VERSION "HNNBNNNYNNNNNNNNNNNNNNNNNNNNNNNNNNNNNNNNNN/4/%%%/4/'%**4NNN///"

NS_ :

BS_:

BU_: AAG BCM1 BCM2 ELV Gateway HDSG IEZS MFG MSBBR SAD SAD2 Schwerpanzer_Zusatz SitzMem_BFS SitzMem_FS SitzMem_HBFS SitzMem_HFS SitzMem_SR3 SpoilerSG TSG_BFS TSG_FS VSG VTS DK_Dummy

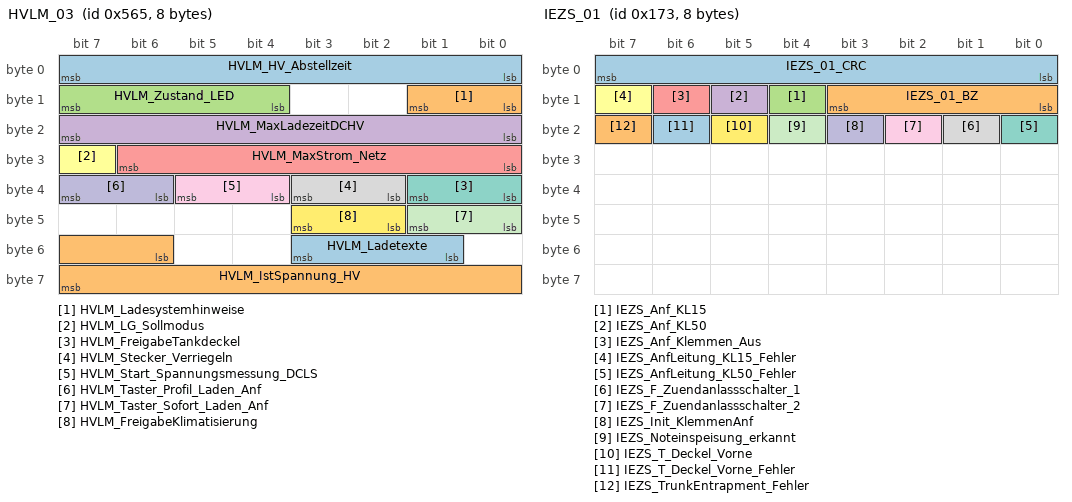
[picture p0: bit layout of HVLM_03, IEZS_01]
BO_ 1381 HVLM_03: 8 Gateway
 SG_ HVLM_HV_Abstellzeit : 0|8@1+ (4,0) [0|1012] "Unit_Minut" Vector__XXX
 SG_ HVLM_Ladesystemhinweise : 8|2@1+ (1,0) [0|3] "" Vector__XXX
 SG_ HVLM_Zustand_LED : 12|4@1+ (1,0) [0|15] "" Vector__XXX
 SG_ HVLM_MaxLadezeitDCHV : 16|8@1+ (10,0) [0|2530] "Unit_Minut" Vector__XXX
 SG_ HVLM_MaxStrom_Netz : 24|7@1+ (0.5,0) [0|62.5] "Unit_Amper" Vector__XXX
 SG_ HVLM_LG_Sollmodus : 31|1@1+ (1,0) [0|1] "" Vector__XXX
 SG_ HVLM_FreigabeTankdeckel : 32|2@1+ (1,0) [0|3] "" Vector__XXX
 SG_ HVLM_Stecker_Verriegeln : 34|2@1+ (1,0) [0|3] "" Vector__XXX
 SG_ HVLM_Start_Spannungsmessung_DCLS : 36|2@1+ (1,0) [0|3] "" Vector__XXX
 SG_ HVLM_Taster_Profil_Laden_Anf : 38|2@1+ (1,0) [0|3] "" Vector__XXX
 SG_ HVLM_Taster_Sofort_Laden_Anf : 40|2@1+ (1,0) [0|3] "" Vector__XXX
 SG_ HVLM_FreigabeKlimatisierung : 42|2@1+ (1,0) [0|3] "" Vector__XXX
 SG_ HVLM_Ladetexte : 49|3@1+ (1,0) [0|7] ""  VTS
 SG_ HVLM_IstSpannung_HV : 54|10@1+ (1,0) [0|1021] "Unit_Volt" Vector__XXX

BO_ 1340 HVLM_04: 8 Gateway
 SG_ HVLM_04_CRC : 0|8@1+ (1,0) [0|255] "" Vector__XXX
 SG_ HVLM_04_BZ : 8|4@1+ (1,0) [0|15] "" Vector__XXX
 SG_ HVLM_STH_Betriebsmodus : 12|3@1+ (1,0) [0|7] "" Vector__XXX
 SG_ HVLM_Standklima_Timer_Status : 15|1@1+ (1,0) [0|1] "" Vector__XXX
 SG_ HVLM_HVEM_MaxLeistung : 16|9@1+ (50,0) [0|25450] "Unit_Watt" Vector__XXX
 SG_ HVLM_Status_Netz : 25|1@1+ (1,0) [0|1] "" Vector__XXX
 SG_ HVLM_Ladeart : 27|2@1+ (1,0) [0|3] "" Vector__XXX
 SG_ HVLM_VK_STH_Einsatz : 29|3@1+ (1,0) [0|7] "" Vector__XXX
 SG_ HVLM_VK_Modus : 32|2@1+ (1,0) [0|3] "" Vector__XXX
 SG_ HVLM_IstModus_02 : 34|2@1+ (1,0) [0|3] "" Vector__XXX
 SG_ HVLM_HV_Anf : 36|2@1+ (1,0) [0|3] "" Vector__XXX
 SG_ HVLM_Fehlerstatus : 38|3@1+ (1,0) [0|7] "" Vector__XXX
 SG_ HVLM_Anforderung_HMS : 41|3@1+ (1,0) [0|7] "" Vector__XXX
 SG_ HVLM_Parken_beibehalten_HMS : 44|2@1+ (1,0) [0|3] "" Vector__XXX
 SG_ HVLM_Dauer_Klima : 46|5@1+ (1,0) [0|30] "Unit_Minut" Vector__XXX
 SG_ HVLM_Stecker_Status : 51|2@1+ (1,0) [0|3] ""  VTS
 SG_ HVLM_LadeAnforderung : 53|3@1+ (1,0) [0|7] "" Vector__XXX
 SG_ HVLM_MaxBatLadestromHV : 56|8@1+ (1,0) [0|253] "Unit_Amper" Vector__XXX

BO_ 371 IEZS_01: 8 IEZS
 SG_ IEZS_01_CRC : 0|8@1+ (1,0) [0|255] ""  BCM2
 SG_ IEZS_01_BZ : 8|4@1+ (1,0) [0|15] ""  BCM2
 SG_ IEZS_Anf_KL15 : 12|1@1+ (1,0) [0|1] ""  BCM2
 SG_ IEZS_Anf_KL50 : 13|1@1+ (1,0) [0|1] ""  BCM2
 SG_ IEZS_Anf_Klemmen_Aus : 14|1@1+ (1,0) [0|1] "Unit_Bit"  BCM2
 SG_ IEZS_AnfLeitung_KL15_Fehler : 15|1@1+ (1,0) [0|1] ""  BCM2
 SG_ IEZS_AnfLeitung_KL50_Fehler : 16|1@1+ (1,0) [0|1] ""  BCM2
 SG_ IEZS_F_Zuendanlassschalter_1 : 17|1@1+ (1,0) [0|1] ""  BCM2
 SG_ IEZS_F_Zuendanlassschalter_2 : 18|1@1+ (1,0) [0|1] ""  BCM2
 SG_ IEZS_Init_KlemmenAnf : 19|1@1+ (1,0) [0|1] ""  BCM2
 SG_ IEZS_Noteinspeisung_erkannt : 20|1@1+ (1,0) [0|1] ""  BCM2
 SG_ IEZS_T_Deckel_Vorne : 21|1@1+ (1,0) [0|1] ""  BCM2
 SG_ IEZS_T_Deckel_Vorne_Fehler : 22|1@1+ (1,0) [0|1] ""  BCM2
 SG_ IEZS_TrunkEntrapment_Fehler : 23|1@1+ (1,0) [0|1] ""  BCM2

BO_ 17 IMMO_Auth_Master_Slave01: 8 BCM2
 SG_ IMMO_Auth_Master_Slave01_Sig : 0|64@1+ (1,0) [0|1.84467440737096E+019] ""  Gateway

BO_ 19 IMMO_Auth_Master_Slave02: 8 BCM2
 SG_ IMMO_Auth_Master_Slave02_Sig : 0|64@1+ (1,0) [0|1.84467440737096E+019] ""  Gateway

BO_ 21 IMMO_Auth_Master_Slave03: 8 BCM2
 SG_ IMMO_Auth_Master_Slave03_Sig : 0|64@1+ (1,0) [0|1.84467440737096E+019] ""  Gateway

BO_ 23 IMMO_Auth_Master_Slave04: 8 BCM2
 SG_ IMMO_Auth_Master_Slave04_Sig : 0|64@1+ (1,0) [0|1.84467440737096E+019] ""  Gateway

BO_ 25 IMMO_Auth_Master_Slave05: 8 BCM2
 SG_ IMMO_Auth_Master_Slave05_Sig : 0|64@1+ (1,0) [0|1.84467440737096E+019] ""  Gateway

BO_ 27 IMMO_Auth_Master_Slave06: 8 BCM2
 SG_ IMMO_Auth_Master_Slave06_Sig : 0|64@1+ (1,0) [0|1.84467440737096E+019] ""  ELV

BO_ 29 IMMO_Auth_Master_Slave07: 8 BCM2
 SG_ IMMO_Auth_Master_Slave07_Sig1 : 0|64@1+ (1,0) [0|1.84467440737096E+019] ""  Gateway

BO_ 31 IMMO_Auth_Master_Slave08: 8 BCM2
 SG_ IMMO_Auth_Master_Slave08_Sig : 0|64@1+ (1,0) [0|1.84467440737096E+019] ""  VTS

BO_ 16 IMMO_Auth_Slave01_Master: 8 Gateway
 SG_ IMMO_Auth_Slave01_Master_Sig : 0|64@1+ (1,0) [0|1.84467440737096E+019] ""  BCM2

BO_ 18 IMMO_Auth_Slave02_Master: 8 Gateway
 SG_ IMMO_Auth_Slave02_Master_Sig : 0|64@1+ (1,0) [0|1.84467440737096E+019] ""  BCM2

BO_ 20 IMMO_Auth_Slave03_Master: 8 Gateway
 SG_ IMMO_Auth_Slave03_Master_Sig : 0|64@1+ (1,0) [0|1.84467440737096E+019] ""  BCM2

BO_ 22 IMMO_Auth_Slave04_Master: 8 Gateway
 SG_ IMMO_Auth_Slave04_Master_Sig : 0|64@1+ (1,0) [0|1.84467440737096E+019] ""  BCM2

BO_ 24 IMMO_Auth_Slave05_Master: 8 Gateway
 SG_ IMMO_Auth_Slave05_Master_Sig : 0|64@1+ (1,0) [0|1.84467440737096E+019] ""  BCM2

BO_ 26 IMMO_Auth_Slave06_Master: 8 ELV
 SG_ IMMO_Auth_Slave06_Master_Sig : 0|64@1+ (1,0) [0|1.84467440737096E+019] ""  BCM2

BO_ 28 IMMO_Auth_Slave07_Master: 8 Gateway
 SG_ IMMO_Auth_Slave07_Master_Sig1 : 0|64@1+ (1,0) [0|1.84467440737096E+019] ""  BCM2

BO_ 30 IMMO_Auth_Slave08_Master: 8 VTS
 SG_ IMMO_Auth_Slave08_Master_Sig : 0|64@1+ (1,0) [0|1.84467440737096E+019] ""  BCM2

BO_ 268 IMMO_CORD_01: 8 Gateway
 SG_ ImoCord_Auth_Aufforderung_WFS : 63|1@1+ (1,0) [0|1] ""  BCM2

BO_ 1524 Innenlicht_11: 8 BCM1
 SG_ IL_Dimmung_V_Tuerkontur : 0|8@1+ (1,0) [0|100] "Unit_PerCent"  Gateway,TSG_BFS,TSG_FS
 SG_ IL_Dimmung_H_Tuerkontur : 8|8@1+ (1,0) [0|100] "Unit_PerCent"  Gateway,TSG_BFS,TSG_FS
 SG_ IL_Dimmung_Tuerinnengriff : 16|8@1+ (1,0) [0|100] "Unit_PerCent"  Gateway,TSG_BFS,TSG_FS
 SG_ IL_Dimmung_Umfeldbel : 24|8@1+ (1,0) [0|100] "Unit_PerCent"  Gateway,TSG_BFS,TSG_FS
 SG_ IL_Bel_FS_Ausstieg : 32|1@1+ (1,0) [0|1] ""  Gateway,TSG_FS
 SG_ IL_Bel_BFS_Ausstieg : 33|1@1+ (1,0) [0|1] ""  Gateway,TSG_BFS
 SG_ IL_Bel_HFS_Ausstieg : 34|1@1+ (1,0) [0|1] ""  Gateway,TSG_FS
 SG_ IL_Bel_HBFS_Ausstieg : 35|1@1+ (1,0) [0|1] ""  Gateway,TSG_BFS
 SG_ BCM1_Innenlicht_gedimmt_V : 36|1@1+ (1,0) [0|1] ""  Gateway
 SG_ BCM1_Innenlicht_gedimmt_H : 37|1@1+ (1,0) [0|1] ""  Gateway
 SG_ IL_Innenlicht_aktiv : 38|1@1+ (1,0) [0|1] ""  Gateway
 SG_ IL_Klemme_30G_aktiv : 39|1@1+ (1,0) [0|1] ""  Gateway,TSG_BFS,TSG_FS
 SG_ BCM1_DI_Rampe_Innenlicht : 40|1@1+ (1,0) [0|1] ""  Gateway
 SG_ BCM1_DI_Rampe_Leselicht : 41|1@1+ (1,0) [0|1] ""  Gateway
 SG_ BCM1_Innenlicht_H : 42|1@1+ (1,0) [0|1] ""  Gateway,TSG_FS
 SG_ BCM1_Innenlicht_V : 43|1@1+ (1,0) [0|1] ""  Gateway
 SG_ BCM1_Leselicht_Anf_hl : 44|1@1+ (1,0) [0|1] ""  Gateway
 SG_ BCM1_Leselicht_Anf_hr : 45|1@1+ (1,0) [0|1] ""  Gateway
 SG_ BCM1_Leselicht_Anf_vl : 46|1@1+ (1,0) [0|1] ""  Gateway
 SG_ BCM1_Leselicht_Anf_vr : 47|1@1+ (1,0) [0|1] ""  Gateway
 SG_ BCM1_Leuchten_Aus : 48|1@1+ (1,0) [0|1] ""  Gateway
 SG_ AMB_Charisma_FahrPr : 49|4@1+ (1,0) [0|15] ""  Gateway
 SG_ AMB_Charisma_Status : 53|2@1+ (1,0) [0|3] ""  Gateway
 SG_ IL_Dimmung_Lautspr : 56|8@1+ (1,0) [0|100] "Unit_PerCent"  Gateway,TSG_BFS,TSG_FS

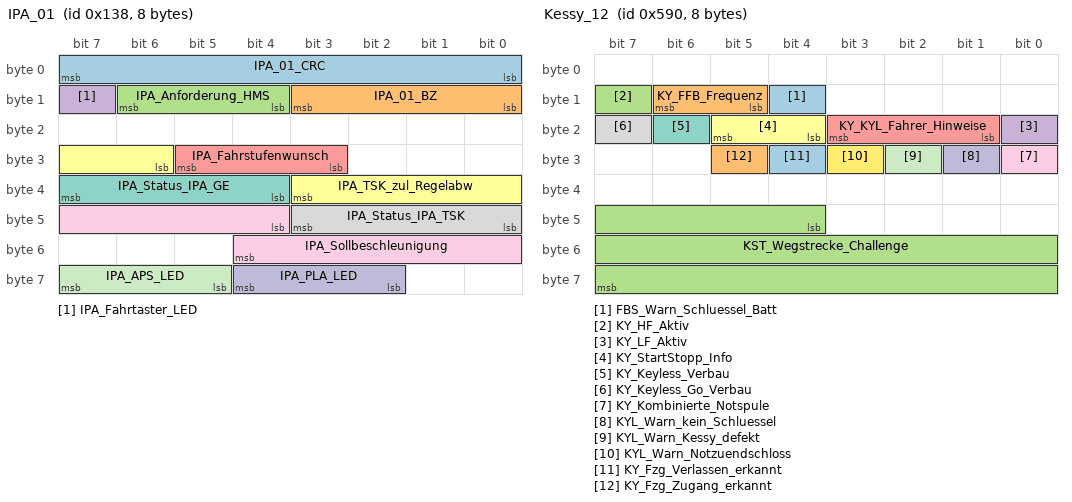
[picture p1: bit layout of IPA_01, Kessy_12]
BO_ 312 IPA_01: 8 Gateway
 SG_ IPA_01_CRC : 0|8@1+ (1,0) [0|255] "" Vector__XXX
 SG_ IPA_01_BZ : 8|4@1+ (1,0) [0|15] "" Vector__XXX
 SG_ IPA_Anforderung_HMS : 12|3@1+ (1,0) [0|7] "" Vector__XXX
 SG_ IPA_Fahrtaster_LED : 15|1@1+ (1,0) [0|1] ""  BCM1
 SG_ IPA_Fahrstufenwunsch : 27|3@1+ (1,0) [0|7] "" Vector__XXX
 SG_ IPA_TSK_zul_Regelabw : 30|6@1+ (0.024,0) [0|1.512] "Unit_MeterPerSeconSquar" Vector__XXX
 SG_ IPA_Status_IPA_GE : 36|4@1+ (1,0) [0|15] "" Vector__XXX
 SG_ IPA_Status_IPA_TSK : 40|4@1+ (1,0) [0|15] ""  BCM1
 SG_ IPA_Sollbeschleunigung : 44|9@1+ (0.01,-4.11) [-4.1|1] "Unit_MeterPerSeconSquar" Vector__XXX
 SG_ IPA_PLA_LED : 58|3@1+ (1,0) [0|7] ""  BCM1
 SG_ IPA_APS_LED : 61|3@1+ (1,0) [0|7] ""  BCM1

BO_ 1863 ISO_AAG_Req: 8 Gateway
 SG_ ISO_AAG_Req_Data : 0|64@1+ (1,0) [0|1.84467440737096E+019] ""  AAG

BO_ 1969 ISO_AAG_Resp: 8 AAG
 SG_ ISO_AAG_Resp_Data : 0|64@1+ (1,0) [0|1.84467440737096E+019] ""  Gateway

BO_ 1806 ISO_BCM1_Req: 8 Gateway
 SG_ ISO_BCM1_Req_Data : 0|64@1+ (1,0) [0|1.84467440737096E+019] ""  BCM1

BO_ 1912 ISO_BCM1_Resp: 8 BCM1
 SG_ ISO_BCM1_Resp_Data : 0|64@1+ (1,0) [0|1.84467440737096E+019] ""  Gateway

BO_ 1841 ISO_ELV_Req: 8 Gateway
 SG_ ISO_ELV_Req_Data : 0|64@1+ (1,0) [0|1.84467440737096E+019] ""  ELV

BO_ 1947 ISO_ELV_Resp: 8 ELV
 SG_ ISO_ELV_Resp_Data : 0|64@1+ (1,0) [0|1.84467440737096E+019] ""  Gateway

BO_ 1792 ISO_Funktionaler_Req_All: 8 Gateway
 SG_ ISO_ALL_01_Req_Data : 0|64@1+ (1,0) [0|1.84467440737096E+019] ""  AAG,BCM1,BCM2,ELV,HDSG,IEZS,MFG,MSBBR,SAD,SAD2,SitzMem_BFS,SitzMem_FS,SitzMem_HBFS,SitzMem_HFS,SitzMem_SR3,SpoilerSG,TSG_BFS,TSG_FS,VSG,VTS

BO_ 1827 ISO_HDSG_Req: 8 Gateway
 SG_ ISO_HDSG_Req_Data : 0|64@1+ (1,0) [0|1.84467440737096E+019] ""  HDSG

BO_ 1933 ISO_HDSG_Resp: 8 HDSG
 SG_ ISO_HDSG_Resp_Data : 0|64@1+ (1,0) [0|1.84467440737096E+019] ""  Gateway

BO_ 1842 ISO_Kessy_Req: 8 Gateway
 SG_ ISO_Kessy_Req_Data : 0|64@1+ (1,0) [0|1.84467440737096E+019] ""  IEZS

BO_ 1948 ISO_Kessy_Resp: 8 IEZS
 SG_ ISO_Kessy_Resp_Data : 0|64@1+ (1,0) [0|1.84467440737096E+019] ""  Gateway

BO_ 1836 ISO_MFG_Req: 8 Gateway
 SG_ ISO_MFG_Req_Data : 0|64@1+ (1,0) [0|1.84467440737096E+019] ""  MFG

BO_ 1942 ISO_MFG_Resp: 8 MFG
 SG_ ISO_MFG_Resp_Data : 0|64@1+ (1,0) [0|1.84467440737096E+019] ""  Gateway

BO_ 2549350921 ISO_OBDC_SKEY_Req: 8 Gateway
 SG_ ISO_OBDC_SKEY_Req_Data : 0|64@1+ (1,0) [0|1.84467440737096E+019] ""  BCM2

BO_ 2549483778 ISO_OBDC_SKEY_Resp: 8 BCM2
 SG_ ISO_OBDC_SKEY_Resp_Data : 0|64@1+ (1,0) [0|1.84467440737096E+019] ""  Gateway

BO_ 2549350923 ISO_OBDC_VSR_Req: 8 Gateway
 SG_ ISO_OBDC_VSR_Req_Data : 0|64@1+ (1,0) [0|1.84467440737096E+019] ""  VTS

BO_ 2549484290 ISO_OBDC_VSR_Resp: 8 VTS
 SG_ ISO_OBDC_VSR_Resp_Data : 0|64@1+ (1,0) [0|1.84467440737096E+019] ""  Gateway

BO_ 1869 ISO_Sitzmemo_BFS_Req: 8 Gateway
 SG_ ISO_Sitzmemo_BFS_Req_Data : 0|64@1+ (1,0) [0|1.84467440737096E+019] ""  SitzMem_BFS

BO_ 1975 ISO_Sitzmemo_BFS_Resp: 8 SitzMem_BFS
 SG_ ISO_Sitzmemo_BFS_Resp_Data : 0|64@1+ (1,0) [0|1.84467440737096E+019] ""  Gateway

BO_ 1868 ISO_Sitzmemo_FS_Req: 8 Gateway
 SG_ ISO_Sitzmemo_FS_Req_Data : 0|64@1+ (1,0) [0|1.84467440737096E+019] ""  SitzMem_FS

BO_ 1974 ISO_Sitzmemo_FS_Resp: 8 SitzMem_FS
 SG_ ISO_Sitzmemo_FS_Resp_Data : 0|64@1+ (1,0) [0|1.84467440737096E+019] ""  Gateway

BO_ 2549352706 ISO_SKEY_OBDC_Req: 8 BCM2
 SG_ ISO_SKEY_OBDC_Req_Data : 0|64@1+ (1,0) [0|1.84467440737096E+019] ""  Gateway

BO_ 2549481993 ISO_SKEY_OBDC_Resp: 8 Gateway
 SG_ ISO_SKEY_OBDC_Resp_Data : 0|64@1+ (1,0) [0|1.84467440737096E+019] ""  BCM2

BO_ 1828 ISO_SpoilerSG_Req: 8 Gateway
 SG_ ISO_SpoilerSG_Req_Data : 0|64@1+ (1,0) [0|1.84467440737096E+019] ""  SpoilerSG

BO_ 1934 ISO_SpoilerSG_Resp: 8 SpoilerSG
 SG_ ISO_SpoilerSG_Resp_Data : 0|64@1+ (1,0) [0|1.84467440737096E+019] ""  Gateway

BO_ 1835 ISO_STS_Req: 8 Gateway
 SG_ ISO_STS_Req_Data : 0|64@1+ (1,0) [0|1.84467440737096E+019] ""  VTS

BO_ 1941 ISO_STS_Resp: 8 VTS
 SG_ ISO_STS_Resp_Data : 0|64@1+ (1,0) [0|1.84467440737096E+019] ""  Gateway

BO_ 1867 ISO_TSG_BT_Req: 8 Gateway
 SG_ ISO_TSG_BT_Req_Data : 0|64@1+ (1,0) [0|1.84467440737096E+019] ""  TSG_BFS

BO_ 1973 ISO_TSG_BT_Resp: 8 TSG_BFS
 SG_ ISO_TSG_BT_Resp_Data : 0|64@1+ (1,0) [0|1.84467440737096E+019] ""  Gateway

BO_ 1866 ISO_TSG_FT_Req: 8 Gateway
 SG_ ISO_TSG_FT_Req_Data : 0|64@1+ (1,0) [0|1.84467440737096E+019] ""  TSG_FS

BO_ 1972 ISO_TSG_FT_Resp: 8 TSG_FS
 SG_ ISO_TSG_FT_Resp_Data : 0|64@1+ (1,0) [0|1.84467440737096E+019] ""  Gateway

BO_ 1855 ISO_TSG_HBFS_Req: 8 Gateway
 SG_ ISO_TSG_HBFS_Req_Data : 0|64@1+ (1,0) [0|1.84467440737096E+019] ""  TSG_BFS

BO_ 1961 ISO_TSG_HBFS_Resp: 8 TSG_BFS
 SG_ ISO_TSG_HBFS_Resp_Data : 0|64@1+ (1,0) [0|1.84467440737096E+019] ""  Gateway

BO_ 1854 ISO_TSG_HFS_Req: 8 Gateway
 SG_ ISO_TSG_HFS_Req_Data : 0|64@1+ (1,0) [0|1.84467440737096E+019] ""  TSG_FS

BO_ 1960 ISO_TSG_HFS_Resp: 8 TSG_FS
 SG_ ISO_TSG_HFS_Resp_Data : 0|64@1+ (1,0) [0|1.84467440737096E+019] ""  Gateway

BO_ 1837 ISO_VSG_Req: 8 Gateway
 SG_ ISO_VSG_Req_Data : 0|64@1+ (1,0) [0|1.84467440737096E+019] ""  VSG

BO_ 1943 ISO_VSG_Resp: 8 VSG
 SG_ ISO_VSG_Resp_Data : 0|64@1+ (1,0) [0|1.84467440737096E+019] ""  Gateway

BO_ 2549353218 ISO_VSR_OBDC_Req: 8 VTS
 SG_ ISO_VSR_OBDC_Req_Data : 0|64@1+ (1,0) [0|1.84467440737096E+019] ""  Gateway

BO_ 2549481995 ISO_VSR_OBDC_Resp: 8 Gateway
 SG_ ISO_VSR_OBDC_Resp_Data : 0|64@1+ (1,0) [0|1.84467440737096E+019] ""  VTS

BO_ 2549874827 ISOx_BCM2_Req: 8 Gateway
 SG_ ISO_BCM2_Req_Data : 0|64@1+ (1,0) [0|1.84467440737096E+019] ""  BCM2

BO_ 2550005899 ISOx_BCM2_Resp: 8 BCM2
 SG_ ISO_BCM2_Resp_Data : 0|64@1+ (1,0) [0|1.84467440737096E+019] ""  Gateway

BO_ 2549874818 ISOx_LCM_L_Req: 8 Gateway
 SG_ ISO_LCM_L_Req_Data : 0|64@1+ (1,0) [0|1.84467440737096E+019] ""  BCM1

BO_ 2550005890 ISOx_LCM_L_Resp: 8 BCM1
 SG_ ISO_LCM_L_Resp_Data : 0|64@1+ (1,0) [0|1.84467440737096E+019] ""  Gateway

BO_ 2549874819 ISOx_LCM_R_Req: 8 Gateway
 SG_ ISO_LCM_R_Req_Data : 0|64@1+ (1,0) [0|1.84467440737096E+019] ""  BCM1

BO_ 2550005891 ISOx_LCM_R_Resp: 8 BCM1
 SG_ ISO_LCM_R_Resp_Data : 0|64@1+ (1,0) [0|1.84467440737096E+019] ""  Gateway

BO_ 2549874838 ISOx_LED_LM_L_Req: 8 Gateway
 SG_ ISO_LED_LM_L_Req_Data : 0|64@1+ (1,0) [0|1.84467440737096E+019] ""  BCM1

BO_ 2550005910 ISOx_LED_LM_L_Resp: 8 BCM1
 SG_ ISO_LED_LM_L_Resp_Data : 0|64@1+ (1,0) [0|1.84467440737096E+019] ""  Gateway

BO_ 2549874839 ISOx_LED_LM_R_Req: 8 Gateway
 SG_ ISO_LED_LM_R_Req_Data : 0|64@1+ (1,0) [0|1.84467440737096E+019] ""  BCM1

BO_ 2550005911 ISOx_LED_LM_R_Resp: 8 BCM1
 SG_ ISO_LED_LM_R_Resp_Data : 0|64@1+ (1,0) [0|1.84467440737096E+019] ""  Gateway

BO_ 2549874848 ISOx_SAD2_Req: 8 Gateway
 SG_ ISO_SAD2_Req_Data : 0|64@1+ (1,0) [0|1.84467440737096E+019] ""  SAD2

BO_ 2550005920 ISOx_SAD2_Resp: 8 SAD2
 SG_ ISO_SAD2_Resp_Data : 0|64@1+ (1,0) [0|1.84467440737096E+019] ""  Gateway

BO_ 2549874820 ISOx_SAD_Req: 8 Gateway
 SG_ ISO_SAD_Req_Data : 0|64@1+ (1,0) [0|1.84467440737096E+019] ""  SAD

BO_ 2550005892 ISOx_SAD_Resp: 8 SAD
 SG_ ISO_SAD_Resp_Data : 0|64@1+ (1,0) [0|1.84467440737096E+019] ""  Gateway

BO_ 2549874843 ISOx_SBBR_Req: 8 Gateway
 SG_ ISO_SBBR_Req_Data : 0|64@1+ (1,0) [0|1.84467440737096E+019] ""  MSBBR

BO_ 2550005915 ISOx_SBBR_Resp: 8 MSBBR
 SG_ ISO_SBBR_Resp_Data : 0|64@1+ (1,0) [0|1.84467440737096E+019] ""  Gateway

BO_ 2549874824 ISOx_Sitzmemo_HBFS_Req: 8 Gateway
 SG_ ISO_Sitzmemo_HBFS_Req_Data : 0|64@1+ (1,0) [0|1.84467440737096E+019] ""  SitzMem_HBFS

BO_ 2550005896 ISOx_Sitzmemo_HBFS_Resp: 8 SitzMem_HBFS
 SG_ ISO_Sitzmemo_HBFS_Resp_Data : 0|64@1+ (1,0) [0|1.84467440737096E+019] ""  Gateway

BO_ 2549874823 ISOx_Sitzmemo_HFS_Req: 8 Gateway
 SG_ ISO_Sitzmemo_HFS_Req_Data : 0|64@1+ (1,0) [0|1.84467440737096E+019] ""  SitzMem_HFS

BO_ 2550005895 ISOx_Sitzmemo_HFS_Resp: 8 SitzMem_HFS
 SG_ ISO_Sitzmemo_HFS_Resp_Data : 0|64@1+ (1,0) [0|1.84467440737096E+019] ""  Gateway

BO_ 2549874837 ISOx_Sitzmemo_SR3_Req: 8 Gateway
 SG_ ISO_Sitzmemo_SR3_Req_Data : 0|64@1+ (1,0) [0|1.84467440737096E+019] ""  SitzMem_SR3

BO_ 2550005909 ISOx_Sitzmemo_SR3_Resp: 8 SitzMem_SR3
 SG_ ISO_Sitzmemo_SR3_Resp_Data : 0|64@1+ (1,0) [0|1.84467440737096E+019] ""  Gateway

BO_ 497 Kessy_11: 8 BCM2
 SG_ FBS_IDG_in_Reichweite : 12|1@1+ (1,0) [0|1] ""  Gateway,HDSG
 SG_ FFB_Auf_Taste : 13|1@1+ (1,0) [0|1] ""  Gateway,SitzMem_FS
 SG_ FFB_HDF_Taste : 14|1@1+ (1,0) [0|1] ""  AAG,BCM1,Gateway,HDSG
 SG_ FFB_Panik_Taste : 15|1@1+ (1,0) [0|1] ""  Gateway,MFG,SitzMem_FS
 SG_ FFB_Zu_Taste : 16|1@1+ (1,0) [0|1] ""  Gateway,SitzMem_FS
 SG_ KY_FT_Entriegelung_Autorisiert : 17|1@1+ (1,0) [0|1] ""  Gateway,SitzMem_FS,TSG_BFS,TSG_FS
 SG_ KY_FT_Verriegelung_Autorisiert : 18|1@1+ (1,0) [0|1] ""  Gateway,TSG_FS
 SG_ KY_BT_Entriegelung_Autorisiert : 19|1@1+ (1,0) [0|1] ""  Gateway,TSG_BFS
 SG_ KY_BT_Verriegelung_Autorisiert : 20|1@1+ (1,0) [0|1] ""  Gateway,TSG_BFS
 SG_ KY_HFS_Entriegelung_Autorisiert : 21|1@1+ (1,0) [0|1] ""  Gateway,TSG_FS
 SG_ KY_HFS_Verriegelung_Autorisiert : 22|1@1+ (1,0) [0|1] ""  Gateway,TSG_FS
 SG_ KY_HBFS_Entriegelung_Autorisiert : 23|1@1+ (1,0) [0|1] ""  Gateway,TSG_BFS
 SG_ KY_HBFS_Verriegelung_Autorisiert : 24|1@1+ (1,0) [0|1] ""  Gateway,TSG_BFS
 SG_ KY_Front_Entr_Autorisiert : 25|1@1+ (1,0) [0|1] ""  BCM1,Gateway
 SG_ KY_Front_Verr_Autorisiert : 26|1@1+ (1,0) [0|1] ""  BCM1,Gateway
 SG_ KY_HD_Entriegelung_Autorisiert : 27|1@1+ (1,0) [0|1] ""  Gateway,HDSG
 SG_ KY_HD_Verriegelung_Autorisiert : 28|1@1+ (1,0) [0|1] ""  Gateway,HDSG
 SG_ KY_Bereich : 29|3@1+ (1,0) [0|7] ""  BCM1,Gateway
 SG_ KY_Position : 32|3@1+ (1,0) [0|7] ""  BCM1,Gateway
 SG_ KY_ZV_Signatur : 35|11@1+ (1,0) [0|2047] ""  Gateway,TSG_BFS,TSG_FS
 SG_ Schluesselnr_Personalisierung : 46|4@1+ (1,0) [0|15] ""  BCM1,Gateway,MFG,SitzMem_BFS,SitzMem_FS,TSG_BFS,TSG_FS
 SG_ FFB_FDF_Taste : 50|1@1+ (1,0) [0|1] ""  BCM1,Gateway
 SG_ FFB_Joker_Taste : 51|1@1+ (1,0) [0|1] ""  BCM1,Gateway,VSG

BO_ 1424 Kessy_12: 8 BCM2
 SG_ FBS_Warn_Schluessel_Batt : 12|1@1+ (1,0) [0|1] ""  Gateway
 SG_ KY_FFB_Frequenz : 13|2@1+ (1,0) [0|3] ""  Gateway,HDSG
 SG_ KY_HF_Aktiv : 15|1@1+ (1,0) [0|1] ""  Gateway,HDSG
 SG_ KY_LF_Aktiv : 16|1@1+ (1,0) [0|1] ""  Gateway,HDSG
 SG_ KY_KYL_Fahrer_Hinweise : 17|3@1+ (1,0) [0|7] ""  Gateway
 SG_ KY_StartStopp_Info : 20|2@1+ (1,0) [0|3] ""  Gateway
 SG_ KY_Keyless_Verbau : 22|1@1+ (1,0) [0|1] ""  Gateway
 SG_ KY_Keyless_Go_Verbau : 23|1@1+ (1,0) [0|1] ""  Gateway
 SG_ KY_Kombinierte_Notspule : 24|1@1+ (1,0) [0|1] ""  Gateway
 SG_ KYL_Warn_kein_Schluessel : 25|1@1+ (1,0) [0|1] ""  Gateway
 SG_ KYL_Warn_Kessy_defekt : 26|1@1+ (1,0) [0|1] ""  Gateway
 SG_ KYL_Warn_Notzuendschloss : 27|1@1+ (1,0) [0|1] ""  Gateway
 SG_ KY_Fzg_Verlassen_erkannt : 28|1@1+ (1,0) [0|1] ""  ELV,Gateway
 SG_ KY_Fzg_Zugang_erkannt : 29|1@1+ (1,0) [0|1] ""  ELV,Gateway
 SG_ KST_Wegstrecke_Challenge : 44|20@1+ (1,0) [0|1048575] ""  Gateway

BO_ 960 Klemmen_Status_01: 4 BCM2
 SG_ Klemmen_Status_01_CRC : 0|8@1+ (1,0) [0|255] ""  AAG,BCM1,ELV,Gateway,SitzMem_SR3
 SG_ Klemmen_Status_01_BZ : 8|4@1+ (1,0) [0|15] ""  AAG,BCM1,ELV,Gateway,SitzMem_SR3,VTS
 SG_ ZAS_Kl_S : 16|1@1+ (1,0) [0|1] ""  AAG,BCM1,ELV,Gateway,HDSG,IEZS,SAD,SAD2,SitzMem_BFS,SitzMem_FS,SitzMem_HBFS,SitzMem_HFS,SitzMem_SR3,TSG_BFS,TSG_FS,VSG,VTS
 SG_ ZAS_Kl_15 : 17|1@1+ (1,0) [0|1] ""  AAG,BCM1,ELV,Gateway,HDSG,IEZS,MSBBR,SAD,SAD2,SitzMem_BFS,SitzMem_FS,SitzMem_HBFS,SitzMem_HFS,SitzMem_SR3,SpoilerSG,TSG_BFS,TSG_FS,VSG,VTS
 SG_ ZAS_Kl_X : 18|1@1+ (1,0) [0|1] ""  Gateway
 SG_ ZAS_Kl_50_Startanforderung : 19|1@1+ (1,0) [0|1] ""  AAG,BCM1,Gateway,IEZS,SAD,SAD2,TSG_BFS,TSG_FS,VTS
 SG_ BCM_Remotestart_Betrieb : 20|1@1+ (1,0) [0|1] ""  ELV,Gateway,TSG_BFS,TSG_FS
 SG_ ZAS_Kl_Infotainment : 21|1@1+ (1,0) [0|1] ""  Gateway
 SG_ BCM_Remotestart_KL15_Anf : 22|1@1+ (1,0) [0|1] ""  Gateway
 SG_ BCM_Remotestart_MO_Start : 23|1@1+ (1,0) [0|1] ""  Gateway
 SG_ KST_Warn_P1_ZST_def : 24|1@1+ (1,0) [0|1] ""  Gateway
 SG_ KST_Warn_P2_ZST_def : 25|1@1+ (1,0) [0|1] ""  Gateway
 SG_ KST_Fahrerhinweis_1 : 26|1@1+ (1,0) [0|1] ""  Gateway
 SG_ KST_Fahrerhinweis_2 : 27|1@1+ (1,0) [0|1] ""  Gateway
 SG_ KST_Fahrerhinweis_3 : 28|1@1+ (1,0) [0|1] ""  Gateway
 SG_ KST_Fahrerhinweis_4 : 29|1@1+ (1,0) [0|1] ""  Gateway
 SG_ KST_Fahrerhinweis_5 : 30|1@1+ (1,0) [0|1] ""  Gateway
 SG_ KST_Fahrerhinweis_6 : 31|1@1+ (1,0) [0|1] ""  Gateway

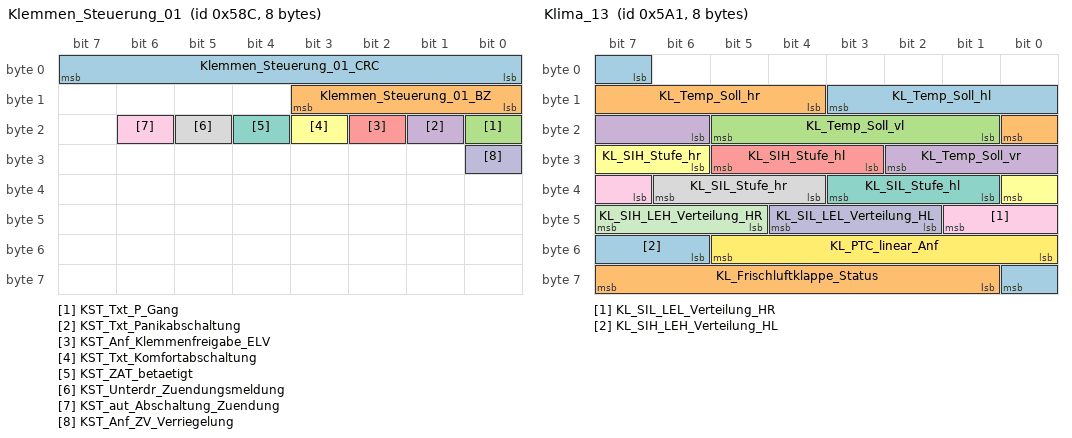
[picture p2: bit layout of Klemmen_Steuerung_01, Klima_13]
BO_ 1420 Klemmen_Steuerung_01: 8 BCM2
 SG_ Klemmen_Steuerung_01_CRC : 0|8@1+ (1,0) [0|255] ""  Gateway
 SG_ Klemmen_Steuerung_01_BZ : 8|4@1+ (1,0) [0|15] ""  Gateway
 SG_ KST_Txt_P_Gang : 16|1@1+ (1,0) [0|1] ""  Gateway
 SG_ KST_Txt_Panikabschaltung : 17|1@1+ (1,0) [0|1] ""  Gateway
 SG_ KST_Anf_Klemmenfreigabe_ELV : 18|1@1+ (1,0) [0|1] ""  ELV,Gateway
 SG_ KST_Txt_Komfortabschaltung : 19|1@1+ (1,0) [0|1] ""  Gateway
 SG_ KST_ZAT_betaetigt : 20|1@1+ (1,0) [0|1] ""  Gateway
 SG_ KST_Unterdr_Zuendungsmeldung : 21|1@1+ (1,0) [0|1] ""  Gateway
 SG_ KST_aut_Abschaltung_Zuendung : 22|1@1+ (1,0) [0|1] ""  BCM1,Gateway
 SG_ KST_Anf_ZV_Verriegelung : 24|1@1+ (1,0) [0|1] ""  Gateway

BO_ 1646 Klima_03: 8 Gateway
 SG_ KL_STL_aktiv : 0|1@1+ (1,0) [0|1] ""  BCM2
 SG_ KL_STH_aktiv : 1|1@1+ (1,0) [0|1] ""  BCM1,BCM2,TSG_FS
 SG_ KL_Solarluefter_aktiv : 2|1@1+ (1,0) [0|1] ""  BCM2,HDSG
 SG_ KL_Umluft_Taste : 3|1@1+ (1,0) [0|1] "" Vector__XXX
 SG_ KL_Geblaese_Fond_Status : 4|4@1+ (1,0) [0|15] ""  SAD2,BCM2,HDSG,SAD
 SG_ KL_STH_Ansteuerung : 8|2@1+ (1,0) [0|3] "" Vector__XXX
 SG_ KL_STH_Betriebsdauer : 10|6@1+ (1,0) [0|60] "Unit_Minut" Vector__XXX
 SG_ KL_Magnetventil : 16|1@1+ (1,0) [0|1] "" Vector__XXX
 SG_ KL_WaPu : 17|1@1+ (1,0) [0|1] ""  BCM1
 SG_ KL_Geblaese_Status : 18|4@1+ (1,0) [0|15] ""  BCM2,HDSG,SAD,SAD2
 SG_ KL_Restwaerme_aktiv : 22|1@1+ (1,0) [0|1] ""  BCM1,BCM2
 SG_ KL_Kompressorkupplung : 23|1@1+ (1,0) [0|1] ""  BCM1
 SG_ KL_BCmE_Livetip_Freigabe : 24|1@1+ (1,0) [0|1] "" Vector__XXX
 SG_ KL_HYB_ASV_hinten_schliessen_Anf : 25|1@1+ (1,0) [0|1] "" Vector__XXX
 SG_ KL_HYB_ASV_vorne_schliessen_Anf : 26|1@1+ (1,0) [0|1] "" Vector__XXX
 SG_ KL_HYB_Spuelbetrieb_Freigabe : 27|1@1+ (1,0) [0|1] "" Vector__XXX
 SG_ KL_Innen_Temp : 32|8@1+ (0.5,-50) [-50|76] "Unit_DegreCelsi"  BCM1,BCM2,HDSG,SAD,SAD2,SitzMem_BFS,SitzMem_FS,SitzMem_HBFS,SitzMem_HFS,SitzMem_SR3,TSG_BFS,TSG_FS,VTS
 SG_ KL_FSH_Automatikbetrieb : 51|1@1+ (1,0) [0|1] "" Vector__XXX
 SG_ KL_SIH_LEH_Verteilung_VL : 52|3@1+ (1,0) [0|7] ""  BCM1
 SG_ KL_SIH_LEL_Verteilung_VL : 55|3@1+ (1,0) [0|7] ""  BCM1
 SG_ KL_SIH_LEH_Verteilung_VR : 58|3@1+ (1,0) [0|7] ""  BCM1
 SG_ KL_SIH_LEL_Verteilung_VR : 61|3@1+ (1,0) [0|7] ""  BCM1

BO_ 949 Klima_11: 8 Gateway
 SG_ KL_Drehz_Anh : 0|1@1+ (1,0) [0|1] "" Vector__XXX
 SG_ KL_Vorwarn_Komp_ein : 1|1@1+ (1,0) [0|1] "" Vector__XXX
 SG_ KL_AC_Schalter : 2|1@1+ (1,0) [0|1] "" Vector__XXX
 SG_ KL_Komp_Moment_alt : 3|1@1+ (1,0) [0|1] "" Vector__XXX
 SG_ KL_Vorwarn_Zuheizer_ein : 6|1@1+ (1,0) [0|1] "" Vector__XXX
 SG_ KL_Zustand : 7|1@1+ (1,0) [0|1] "" Vector__XXX
 SG_ KL_Kompressorkupplung_linear : 8|8@1+ (20,0) [0|4000] "Unit_MilliAmper"  BCM1
 SG_ KL_Charisma_FahrPr : 16|4@1+ (1,0) [0|15] "" Vector__XXX
 SG_ KL_Charisma_Status : 20|2@1+ (1,0) [0|3] "" Vector__XXX
 SG_ KL_nachtr_Stopp_Anf : 22|1@1+ (1,0) [0|1] "" Vector__XXX
 SG_ KL_T_Charge : 23|1@1+ (1,0) [0|1] "" Vector__XXX
 SG_ KL_Last_Kompr : 24|8@1+ (0.25,0) [0|63.5] "Unit_NewtoMeter" Vector__XXX
 SG_ KL_Spannungs_Anf : 32|2@1+ (1,0) [0|3] "" Vector__XXX
 SG_ KL_Thermomanagement : 34|2@1+ (1,0) [0|3] "" Vector__XXX
 SG_ KL_StartStopp_Info : 36|2@1+ (1,0) [0|3] "" Vector__XXX
 SG_ KL_Freilauf_Info : 38|2@1+ (1,0) [0|3] "" Vector__XXX
 SG_ KL_Anf_KL : 40|8@1+ (0.4,0) [0|101.6] "Unit_PerCent" Vector__XXX
 SG_ KL_el_Zuheizer_Stufe : 48|3@1+ (1,0) [0|7] ""  BCM1
 SG_ KL_Ausstattung_Klima : 51|3@1+ (1,0) [0|7] ""  BCM1

BO_ 1640 Klima_12: 8 Gateway
 SG_ KL_LRH_Taster : 0|1@1+ (1,0) [0|1] "" Vector__XXX
 SG_ KL_LRH_Stufe : 1|2@1+ (1,0) [0|3] "" Vector__XXX
 SG_ HSH_Taster : 3|2@1+ (1,0) [0|3] ""  BCM2,VSG
 SG_ FSH_Taster : 5|1@1+ (1,0) [0|1] ""  BCM2
 SG_ KL_Zuheizer_Freigabe : 6|1@1+ (1,0) [0|1] "" Vector__XXX
 SG_ KL_Beschlagsgefahr : 7|1@1+ (1,0) [0|1] "" Vector__XXX
 SG_ KL_SIH_Soll_li : 8|3@1+ (1,0) [0|7] ""  BCM1
 SG_ KL_SIH_Soll_re : 11|3@1+ (1,0) [0|7] ""  BCM1
 SG_ KRH_Soll_li : 14|2@1+ (1,0) [0|3] ""  BCM1
 SG_ KL_SIL_Soll_li : 16|3@1+ (1,0) [0|7] ""  BCM1
 SG_ KL_SIL_Soll_re : 19|3@1+ (1,0) [0|7] ""  BCM1
 SG_ KRH_Soll_re : 22|2@1+ (1,0) [0|3] ""  BCM1
 SG_ KL_Geblspng_Soll : 24|8@1+ (0.05,1.45) [1.5|14] "Unit_Volt" Vector__XXX
 SG_ KL_Geblspng_Fond_Soll : 32|8@1+ (0.05,1.45) [1.5|14] "Unit_Volt" Vector__XXX
 SG_ KL_I_Geblaese : 40|8@1+ (0.25,0) [0|63.5] "Unit_Amper" Vector__XXX
 SG_ KL_Kompressorstrom_soll : 48|10@1+ (1,0) [0|1021] ""  BCM1
 SG_ KL_Umluftklappe_Status : 58|4@1+ (1,0) [0|15] ""  HDSG
 SG_ KL_PTC_Verbauinfo : 62|2@1+ (1,0) [0|3] "" Vector__XXX

BO_ 1441 Klima_13: 8 Gateway
 SG_ KL_Temp_Soll_hl : 7|5@1+ (0.5,15.5) [15.5|30] "Unit_DegreCelsi"  BCM1
 SG_ KL_Temp_Soll_hr : 12|5@1+ (0.5,15.5) [15.5|30] "Unit_DegreCelsi"  BCM1
 SG_ KL_Temp_Soll_vl : 17|5@1+ (0.5,15.5) [15.5|30] "Unit_DegreCelsi"  BCM1
 SG_ KL_Temp_Soll_vr : 22|5@1+ (0.5,15.5) [15.5|30] "Unit_DegreCelsi"  BCM1
 SG_ KL_SIH_Stufe_hl : 27|3@1+ (1,0) [0|6] ""  BCM1
 SG_ KL_SIH_Stufe_hr : 30|3@1+ (1,0) [0|6] ""  BCM1
 SG_ KL_SIL_Stufe_hl : 33|3@1+ (1,0) [0|6] ""  BCM1
 SG_ KL_SIL_Stufe_hr : 36|3@1+ (1,0) [0|6] ""  BCM1
 SG_ KL_SIL_LEL_Verteilung_HR : 39|3@1+ (1,0) [0|7] ""  BCM1
 SG_ KL_SIL_LEL_Verteilung_HL : 42|3@1+ (1,0) [0|7] ""  BCM1
 SG_ KL_SIH_LEH_Verteilung_HR : 45|3@1+ (1,0) [0|7] ""  BCM1
 SG_ KL_PTC_linear_Anf : 48|6@1+ (50,0) [0|3100] "Unit_Watt" Vector__XXX
 SG_ KL_SIH_LEH_Verteilung_HL : 54|3@1+ (1,0) [0|7] ""  BCM1
 SG_ KL_Frischluftklappe_Status : 57|7@1+ (1,0) [0|100] "Unit_PerCent" Vector__XXX

BO_ 992 Klima_hinten_01: 8 Gateway
 SG_ KL_Fond_Fuss_Temp_hl : 0|10@1+ (0.1,-5) [-5|97.1] "Unit_DegreCelsi" Vector__XXX
 SG_ KL_SL_Soll_hl : 10|3@1+ (1,0) [0|7] ""  BCM1
 SG_ KL_SL_Soll_hr : 13|3@1+ (1,0) [0|7] ""  BCM1
 SG_ KL_Fond_Fuss_Temp_hr : 16|10@1+ (0.1,-5) [-5|97.1] "Unit_DegreCelsi" Vector__XXX
 SG_ KL_SH_Soll_hl : 26|3@1+ (1,0) [0|7] ""  BCM1
 SG_ KL_SH_Soll_hr : 29|3@1+ (1,0) [0|7] ""  BCM1
 SG_ KL_MA_Temp_hl : 32|10@1+ (0.1,-5) [-5|97.1] "Unit_DegreCelsi" Vector__XXX
 SG_ KL_SIH_Takt_hl : 42|1@1+ (1,0) [0|1] "" Vector__XXX
 SG_ KL_SIH_Takt_hr : 43|1@1+ (1,0) [0|1] "" Vector__XXX
 SG_ KL_Fehler_Umluft : 44|1@1+ (1,0) [0|1] "" Vector__XXX
 SG_ KL_RAB : 45|1@1+ (1,0) [0|1] "" Vector__XXX
 SG_ KL_Fond_Absperrventil : 46|1@1+ (1,0) [0|1] "" Vector__XXX
 SG_ KL_Fond_KD_Fehler : 47|1@1+ (1,0) [0|1] "" Vector__XXX
 SG_ KL_MA_Temp_hr : 48|10@1+ (0.1,-5) [-5|97.1] "Unit_DegreCelsi" Vector__XXX
 SG_ KL_Fehler_Fussraum_Klappen : 58|2@1+ (1,0) [0|3] "" Vector__XXX
 SG_ KL_Fehler_Temp_Klappen : 60|2@1+ (1,0) [0|3] "" Vector__XXX
 SG_ KL_Fehler_Temp_MA_Klappen : 62|2@1+ (1,0) [0|3] "" Vector__XXX

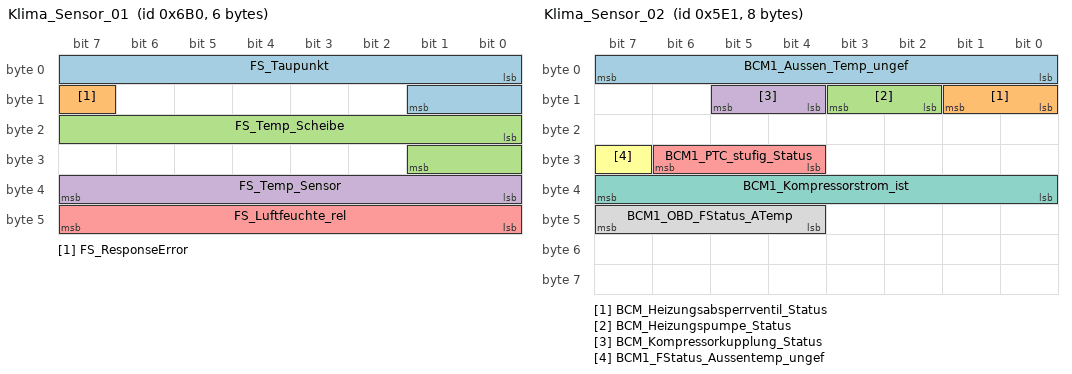
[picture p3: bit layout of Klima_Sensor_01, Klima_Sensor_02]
BO_ 1712 Klima_Sensor_01: 6 BCM1
 SG_ FS_Taupunkt : 0|10@1+ (0.1,-39.6) [-39.5|60.4] "Unit_DegreCelsi"  Gateway,VTS
 SG_ FS_ResponseError : 15|1@1+ (1,0) [0|1] ""  Gateway
 SG_ FS_Temp_Scheibe : 16|10@1+ (0.1,-39.6) [-39.5|60.4] "Unit_DegreCelsi"  Gateway,VTS
 SG_ FS_Temp_Sensor : 32|8@1+ (0.5,-40) [-39.5|87] "Unit_DegreCelsi"  Gateway,VTS
 SG_ FS_Luftfeuchte_rel : 40|8@1+ (0.5,-0.5) [0|100] "Unit_PerCent"  Gateway,VTS

BO_ 1505 Klima_Sensor_02: 8 BCM1
 SG_ BCM1_Aussen_Temp_ungef : 0|8@1+ (0.5,-50) [-50|76] "Unit_DegreCelsi"  BCM2,Gateway,HDSG,TSG_BFS,TSG_FS
 SG_ BCM_Heizungsabsperrventil_Status : 8|2@1+ (1,0) [0|3] ""  BCM2,Gateway
 SG_ BCM_Heizungspumpe_Status : 10|2@1+ (1,0) [0|3] ""  BCM2,Gateway
 SG_ BCM_Kompressorkupplung_Status : 12|2@1+ (1,0) [0|3] ""  BCM2,Gateway
 SG_ BCM1_PTC_stufig_Status : 28|3@1+ (1,0) [0|7] ""  Gateway
 SG_ BCM1_FStatus_Aussentemp_ungef : 31|1@1+ (1,0) [0|1] ""  Gateway
 SG_ BCM1_Kompressorstrom_ist : 32|8@1+ (4,0) [0|1000] "Unit_MilliAmper"  Gateway
 SG_ BCM1_OBD_FStatus_ATemp : 44|4@1+ (1,0) [0|15] ""  Gateway

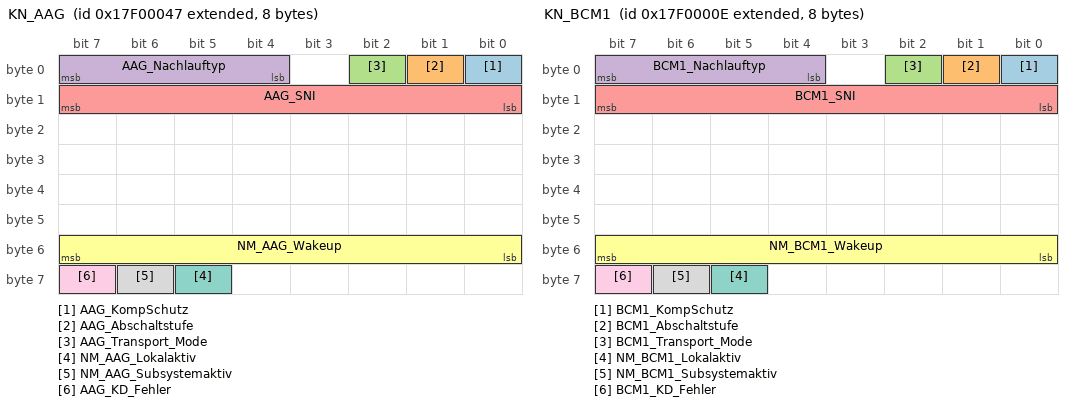
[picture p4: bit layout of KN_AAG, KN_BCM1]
BO_ 2549088327 KN_AAG: 8 AAG
 SG_ AAG_KompSchutz : 0|1@1+ (1,0) [0|1] "" Vector__XXX
 SG_ AAG_Abschaltstufe : 1|1@1+ (1,0) [0|1] "" Vector__XXX
 SG_ AAG_Transport_Mode : 2|1@1+ (1,0) [0|1] "" Vector__XXX
 SG_ AAG_Nachlauftyp : 4|4@1+ (1,0) [0|15] ""  Gateway
 SG_ AAG_SNI : 8|8@1+ (1,0) [0|255] ""  Gateway
 SG_ NM_AAG_Wakeup : 48|8@1+ (1,0) [0|255] "" Vector__XXX
 SG_ NM_AAG_Lokalaktiv : 61|1@1+ (1,0) [0|1] ""  Gateway
 SG_ NM_AAG_Subsystemaktiv : 62|1@1+ (1,0) [0|1] ""  Gateway
 SG_ AAG_KD_Fehler : 63|1@1+ (1,0) [0|1] ""  Gateway

BO_ 2549088270 KN_BCM1: 8 BCM1
 SG_ BCM1_KompSchutz : 0|1@1+ (1,0) [0|1] "" Vector__XXX
 SG_ BCM1_Abschaltstufe : 1|1@1+ (1,0) [0|1] "" Vector__XXX
 SG_ BCM1_Transport_Mode : 2|1@1+ (1,0) [0|1] "" Vector__XXX
 SG_ BCM1_Nachlauftyp : 4|4@1+ (1,0) [0|15] ""  Gateway
 SG_ BCM1_SNI : 8|8@1+ (1,0) [0|255] ""  Gateway
 SG_ NM_BCM1_Wakeup : 48|8@1+ (1,0) [0|255] "" Vector__XXX
 SG_ NM_BCM1_Lokalaktiv : 61|1@1+ (1,0) [0|1] ""  Gateway
 SG_ NM_BCM1_Subsystemaktiv : 62|1@1+ (1,0) [0|1] ""  Gateway
 SG_ BCM1_KD_Fehler : 63|1@1+ (1,0) [0|1] ""  Gateway

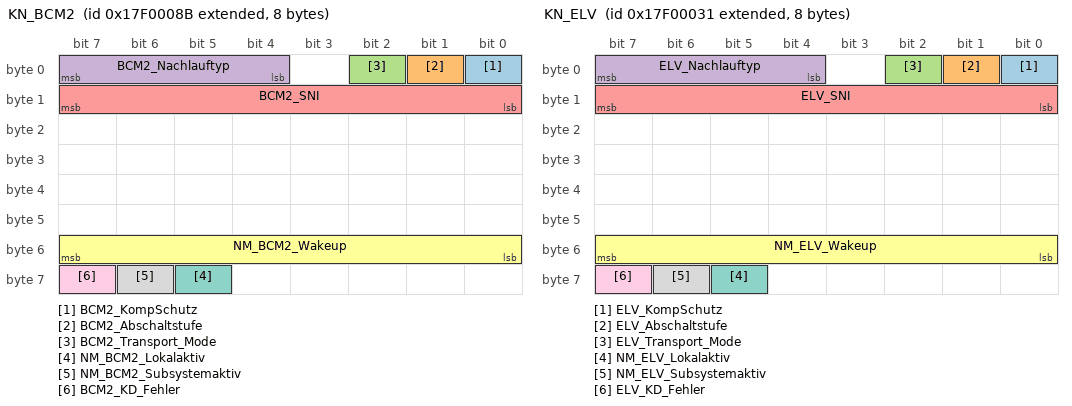
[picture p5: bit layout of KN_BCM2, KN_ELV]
BO_ 2549088395 KN_BCM2: 8 BCM2
 SG_ BCM2_KompSchutz : 0|1@1+ (1,0) [0|1] "" Vector__XXX
 SG_ BCM2_Abschaltstufe : 1|1@1+ (1,0) [0|1] "" Vector__XXX
 SG_ BCM2_Transport_Mode : 2|1@1+ (1,0) [0|1] "" Vector__XXX
 SG_ BCM2_Nachlauftyp : 4|4@1+ (1,0) [0|15] ""  Gateway
 SG_ BCM2_SNI : 8|8@1+ (1,0) [0|255] ""  Gateway
 SG_ NM_BCM2_Wakeup : 48|8@1+ (1,0) [0|255] "" Vector__XXX
 SG_ NM_BCM2_Lokalaktiv : 61|1@1+ (1,0) [0|1] ""  Gateway
 SG_ NM_BCM2_Subsystemaktiv : 62|1@1+ (1,0) [0|1] ""  Gateway
 SG_ BCM2_KD_Fehler : 63|1@1+ (1,0) [0|1] ""  Gateway

BO_ 2549088305 KN_ELV: 8 ELV
 SG_ ELV_KompSchutz : 0|1@1+ (1,0) [0|1] "" Vector__XXX
 SG_ ELV_Abschaltstufe : 1|1@1+ (1,0) [0|1] "" Vector__XXX
 SG_ ELV_Transport_Mode : 2|1@1+ (1,0) [0|1] "" Vector__XXX
 SG_ ELV_Nachlauftyp : 4|4@1+ (1,0) [0|15] ""  Gateway
 SG_ ELV_SNI : 8|8@1+ (1,0) [0|255] ""  Gateway
 SG_ NM_ELV_Wakeup : 48|8@1+ (1,0) [0|255] "" Vector__XXX
 SG_ NM_ELV_Lokalaktiv : 61|1@1+ (1,0) [0|1] ""  Gateway
 SG_ NM_ELV_Subsystemaktiv : 62|1@1+ (1,0) [0|1] ""  Gateway
 SG_ ELV_KD_Fehler : 63|1@1+ (1,0) [0|1] ""  Gateway

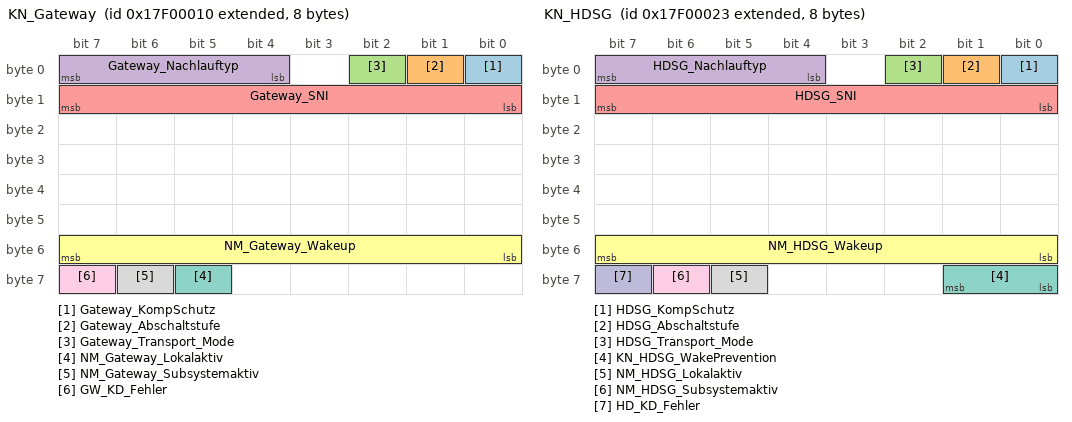
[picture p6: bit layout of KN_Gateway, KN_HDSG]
BO_ 2549088272 KN_Gateway: 8 Gateway
 SG_ Gateway_KompSchutz : 0|1@1+ (1,0) [0|1] "" Vector__XXX
 SG_ Gateway_Abschaltstufe : 1|1@1+ (1,0) [0|1] "" Vector__XXX
 SG_ Gateway_Transport_Mode : 2|1@1+ (1,0) [0|1] "" Vector__XXX
 SG_ Gateway_Nachlauftyp : 4|4@1+ (1,0) [0|15] "" Vector__XXX
 SG_ Gateway_SNI : 8|8@1+ (1,0) [0|255] "" Vector__XXX
 SG_ NM_Gateway_Wakeup : 48|8@1+ (1,0) [0|255] "" Vector__XXX
 SG_ NM_Gateway_Lokalaktiv : 61|1@1+ (1,0) [0|1] "" Vector__XXX
 SG_ NM_Gateway_Subsystemaktiv : 62|1@1+ (1,0) [0|1] "" Vector__XXX
 SG_ GW_KD_Fehler : 63|1@1+ (1,0) [0|1] "" Vector__XXX

BO_ 2549088291 KN_HDSG: 8 HDSG
 SG_ HDSG_KompSchutz : 0|1@1+ (1,0) [0|1] "" Vector__XXX
 SG_ HDSG_Abschaltstufe : 1|1@1+ (1,0) [0|1] "" Vector__XXX
 SG_ HDSG_Transport_Mode : 2|1@1+ (1,0) [0|1] "" Vector__XXX
 SG_ HDSG_Nachlauftyp : 4|4@1+ (1,0) [0|15] ""  Gateway
 SG_ HDSG_SNI : 8|8@1+ (1,0) [0|255] ""  Gateway
 SG_ NM_HDSG_Wakeup : 48|8@1+ (1,0) [0|255] "" Vector__XXX
 SG_ KN_HDSG_WakePrevention : 56|2@1+ (1,0) [0|3] ""  Gateway
 SG_ NM_HDSG_Lokalaktiv : 61|1@1+ (1,0) [0|1] ""  Gateway
 SG_ NM_HDSG_Subsystemaktiv : 62|1@1+ (1,0) [0|1] "" Vector__XXX
 SG_ HD_KD_Fehler : 63|1@1+ (1,0) [0|1] ""  Gateway

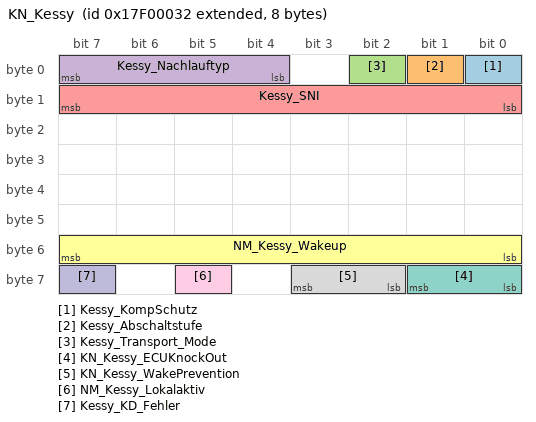
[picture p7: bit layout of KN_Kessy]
BO_ 2549088306 KN_Kessy: 8 IEZS
 SG_ Kessy_KompSchutz : 0|1@1+ (1,0) [0|1] "" Vector__XXX
 SG_ Kessy_Abschaltstufe : 1|1@1+ (1,0) [0|1] "" Vector__XXX
 SG_ Kessy_Transport_Mode : 2|1@1+ (1,0) [0|1] "" Vector__XXX
 SG_ Kessy_Nachlauftyp : 4|4@1+ (1,0) [0|15] ""  Gateway
 SG_ Kessy_SNI : 8|8@1+ (1,0) [0|255] ""  Gateway
 SG_ NM_Kessy_Wakeup : 48|8@1+ (1,0) [0|255] "" Vector__XXX
 SG_ KN_Kessy_ECUKnockOut : 56|2@1+ (1,0) [0|3] ""  Gateway
 SG_ KN_Kessy_WakePrevention : 58|2@1+ (1,0) [0|3] ""  Gateway
 SG_ NM_Kessy_Lokalaktiv : 61|1@1+ (1,0) [0|1] ""  Gateway
 SG_ Kessy_KD_Fehler : 63|1@1+ (1,0) [0|1] ""  Gateway

CM_ SG_ 1381 HVLM_HV_Abstellzeit "Zeitraum zwischen HV-Deaktiviert und HV-Aktiviert";
CM_ SG_ 1381 HVLM_Ladesystemhinweise "Anzeigen von Hinweisen zum Ladesystem.
Anzeigen, dass das Ladesystem defekt ist.";
CM_ SG_ 1381 HVLM_Zustand_LED "Zustand der Lade-LED im Kombi und Dosenbeleuchtung";
CM_ SG_ 1381 HVLM_MaxLadezeitDCHV "maximale Ladezeit in Minuten für die Ladesäule";
CM_ SG_ 1381 HVLM_MaxStrom_Netz "maximal zulässiger Strom auf Primärseite (AC) des Ladegerätes
Minima aus
Vorgabe z.B. über
- intelligente Kommunikation
- Control Pilot Duty Cycle
- Widerstandskodierung Kabel (Proximity)
- Vorgabe MMI, o.ä.";
CM_ SG_ 1381 HVLM_LG_Sollmodus "Sollmodus AC Ladegerät";
CM_ SG_ 1381 HVLM_FreigabeTankdeckel "Tankdeckelfreigabe";
CM_ SG_ 1381 HVLM_Stecker_Verriegeln "Anforderung Steckerverriegelung";
CM_ SG_ 1381 HVLM_Start_Spannungsmessung_DCLS "Meldung an das BMS, dass an der DC-Ladesäule eine Messspannung aufgeschaltet wird.";
CM_ SG_ 1381 HVLM_Taster_Profil_Laden_Anf "SollZustand der Profil-Laden-Taste; LED an der Ladedose";
CM_ SG_ 1381 HVLM_Taster_Sofort_Laden_Anf "Sollzustand der Sofort-Laden-Taste; LED an der Ladedose";
CM_ SG_ 1381 HVLM_FreigabeKlimatisierung "Klimatisierung freigeben";
CM_ SG_ 1381 HVLM_Ladetexte "Anzeige, ob AC- oder DC-Laden nicht möglich ist";
CM_ SG_ 1381 HVLM_IstSpannung_HV "Ausgangsspannung des Ladegerätes und DC-Spannung der Ladesäule. Messung zwischen den DC HV-Leitungen. ";
CM_ BO_ 1340 "CAN-Botschaft";
CM_ SG_ 1340 HVLM_04_CRC "Für MLB:
'Berechnung siehe Lastenheft 'Kommunikationsabsicherung für FlexRay und CAN''

Ab MQB und MLBevo:
'Berechnung siehe Lastenheft 'End-to-End Kommunikationsabsicherung''

Endwerte siehe Begleitdokument 'S-PDU Kennungsfolgen'";
CM_ SG_ 1340 HVLM_04_BZ "Fortlaufender Botschaftszaehler";
CM_ SG_ 1340 HVLM_STH_Betriebsmodus "Betriebsmodus der Standheizung für Vorkonditionierung und Timerklimatisierung";
CM_ SG_ 1340 HVLM_Standklima_Timer_Status "Signalisierung an das KBT ob mind. ein Timer zur Standklimatisierung programmiert ist";
CM_ SG_ 1340 HVLM_HVEM_MaxLeistung "Maximal zulässige Leistung, die das HVEM vom Lader nutzen darf. Wenn das Fzg nicht über einen Lader mit dem AC Netz verbunden ist ist dieser Wert 0.";
CM_ SG_ 1340 HVLM_Status_Netz "Information, ob das Fahrzeug mit einem Stromnetz verbunden ist.";
CM_ SG_ 1340 HVLM_Ladeart "Anzeige, ob Strom in das Fzg. fließt und wofür er verwendet wird.";
CM_ SG_ 1340 HVLM_VK_STH_Einsatz "Auswahl der PHEV Standheizung";
CM_ SG_ 1340 HVLM_VK_Modus "Übermittlung des aktuellen Konditionierungs-Status für HMI, Mobile Online Dienste";
CM_ SG_ 1340 HVLM_IstModus_02 "aktueller Modus";
CM_ SG_ 1340 HVLM_HV_Anf "HV-Aktivierung Anforderung und Grund der Anforderung";
CM_ SG_ 1340 HVLM_Fehlerstatus "aktueller Fehlerstatus des Ladegerätes
";
CM_ SG_ 1340 HVLM_Anforderung_HMS "Anforderung zur Verriegelung des Triebstrangs";
CM_ SG_ 1340 HVLM_Parken_beibehalten_HMS "Anforderung den Triebstrang verriegelt zu halten";
CM_ SG_ 1340 HVLM_Dauer_Klima "Dauer der Innenraumklimatisierung";
CM_ SG_ 1340 HVLM_Stecker_Status "Status der Steckererkennung unabhängig vom Lademodus (AC oder DC)";
CM_ SG_ 1340 HVLM_LadeAnforderung "Mitteilung des Lademanagements an das MSG ob Stecker erkannt wurde, Laden gestartet, ein autonomer Betriebszustand aktiviert, eine Relaxing Phase für die Batterie angefordert werden soll";
CM_ SG_ 1340 HVLM_MaxBatLadestromHV "Empfohlener HV Batterieladestrom bei einer geplanten Ladung";
CM_ SG_ 371 IEZS_01_CRC "CRC zur Erfüllung der FUSI-Anforderungen (Erfassung Anforderung zum Schalten der Klemmen).";
CM_ SG_ 371 IEZS_01_BZ "Botschaftszähler zur Erfüllung der FUSI-Anforderungen (Erfassung Anforderung zum Schalten der Klemmen).";
CM_ SG_ 371 IEZS_Anf_KL15 "Anforderung der Starteinrichtung (iEZS) zum Schalten der Klemme 15";
CM_ SG_ 371 IEZS_Anf_KL50 "Anforderung der Porsche Starteinrichtung (iEZS) zum Schalten der KL50";
CM_ SG_ 371 IEZS_Anf_Klemmen_Aus "Von der Starteinrichtung (iEZS) erfasste Anforderung zum Ausschalten der Klemmen.";
CM_ SG_ 371 IEZS_AnfLeitung_KL15_Fehler "Information der Starteinrichtung (iEZS) über einen diagnostizierten Leitungsdefekt der Redundanzleitung";
CM_ SG_ 371 IEZS_AnfLeitung_KL50_Fehler "Information der Porsche Starteinrichtung über einen an der Kl50-HW-Redundanzleitung diagnostizierten Fehler";
CM_ SG_ 371 IEZS_F_Zuendanlassschalter_1 "Übertragung eines in der Starteinrichtung ermittelten Fehlers";
CM_ SG_ 371 IEZS_F_Zuendanlassschalter_2 "Übertragung eines im iEZS ermittelten Fehlers an das BCM2 ";
CM_ SG_ 371 IEZS_Init_KlemmenAnf "Information der Porsche Starteinrichtung, dass die Positionserfassung in der Applikation noch nicht abgeschlossen ist";
CM_ SG_ 371 IEZS_Noteinspeisung_erkannt "Das iEZS überwacht den Noteinspeisepunkt und sendet die Info an die Klemmensteuerung im BCM2. ";
CM_ SG_ 371 IEZS_T_Deckel_Vorne "Information über einen betätigten (Schweller-)Taster für den Deckel vorne.";
CM_ SG_ 371 IEZS_T_Deckel_Vorne_Fehler "Information über einen hängenden (Schweller-)Taster für den Deckel-vorne.";
CM_ SG_ 371 IEZS_TrunkEntrapment_Fehler "Information über einen diagnostizierten Fehler am Stellelement TrunkEntrapment.";
CM_ SG_ 29 IMMO_Auth_Master_Slave07_Sig1 "Signal zur WFS Auth. vom Master ans cGW/OCU
NoSigSendType";
CM_ SG_ 31 IMMO_Auth_Master_Slave08_Sig "Signal zur WFS Auth. vom Master ans VTS
NoSigSendType";
CM_ SG_ 28 IMMO_Auth_Slave07_Master_Sig1 "Signal zur WFS Auth. vom VTS an den Master
NoMsgSendType";
CM_ SG_ 30 IMMO_Auth_Slave08_Master_Sig "Signal zur WFS Auth. vom VTS an den Master
NoMsgSendType";
CM_ SG_ 268 ImoCord_Auth_Aufforderung_WFS "WFS-Anforderung";
CM_ SG_ 1524 IL_Dimmung_V_Tuerkontur "Dimmung Türkontur vorne (bei Änderung im 30 ms Raster)";
CM_ SG_ 1524 IL_Dimmung_H_Tuerkontur "Dimmung Türkontur hinten (bei Änderung im 30 ms Raster)";
CM_ SG_ 1524 IL_Dimmung_Tuerinnengriff "Dimmung Türinnengriff";
CM_ SG_ 1524 IL_Dimmung_Umfeldbel "Dimmung Umfeldbeleuchtung an Türaußenseite oder Außenspiegel";
CM_ SG_ 1524 IL_Bel_FS_Ausstieg "Einschalten der Ausstiegsleuchten oder Türwarnleuchten in Tür oder im Schweller";
CM_ SG_ 1524 IL_Bel_BFS_Ausstieg "Einschalten der Ausstiegsleuchten oder Türwarnleuchten in Tür oder im Schweller";
CM_ SG_ 1524 IL_Bel_HFS_Ausstieg "Einschalten der Ausstiegsleuchten oder Türwarnleuchten in Tür oder im Schweller";
CM_ SG_ 1524 IL_Bel_HBFS_Ausstieg "Einschalten der Ausstiegsleuchten oder Türwarnleuchten in Tür oder im Schweller";
CM_ SG_ 1524 BCM1_Innenlicht_gedimmt_V "Steuerung von BCM_Innenlicht_V";
CM_ SG_ 1524 BCM1_Innenlicht_gedimmt_H "Steuerung von BCM_Innenlicht_H";
CM_ SG_ 1524 IL_Innenlicht_aktiv "Status Innenlicht";
CM_ SG_ 1524 IL_Klemme_30G_aktiv "Synchrones Abschalten";
CM_ SG_ 1524 BCM1_DI_Rampe_Innenlicht "Dimmrampe Innenlicht";
CM_ SG_ 1524 BCM1_DI_Rampe_Leselicht "Dimmrampe Leselicht";
CM_ SG_ 1524 BCM1_Innenlicht_H "Anforderung Innenlicht hinten";
CM_ SG_ 1524 BCM1_Innenlicht_V "Anforderung Innenlicht vorne";
CM_ SG_ 1524 BCM1_Leselicht_Anf_hl " Leselicht hinten links Anforderung";
CM_ SG_ 1524 BCM1_Leselicht_Anf_hr "Leselicht hinten rechts Anforderung";
CM_ SG_ 1524 BCM1_Leselicht_Anf_vl "Leselicht vorne links Anforderung";
CM_ SG_ 1524 BCM1_Leselicht_Anf_vr "Leselicht vorne rechts Anforderung";
CM_ SG_ 1524 BCM1_Leuchten_Aus "Innenbeleuchtung ausschalten (keine Änderung / ausschalten)";
CM_ SG_ 1524 AMB_Charisma_FahrPr "MLBevo: Aktuelles Fahrprogramm des Charisma-Teilnehmers (siehe Systemlastenheft Drive Select)
MQB: Istwert der Kennlinie (siehe Systemlastenheft MQB FPA)";
CM_ SG_ 1524 AMB_Charisma_Status "Systemstatus des Charismateilnehmers

Wert 0x3 ist nur für Fahrzeuge ab MQB relevant";
CM_ SG_ 1524 IL_Dimmung_Lautspr "Dimmung Umfeldbeleuchtung an Türaußenseite oder Außenspiegel";
CM_ SG_ 312 IPA_01_CRC "Für MLB:
'Berechnung siehe Lastenheft 'Kommunikationsabsicherung für FlexRay und CAN''

Ab MQB und MLBevo:
'Berechnung siehe Lastenheft 'End-to-End Kommunikationsabsicherung''

Endwerte siehe Begleitdokument 'S-PDU Kennungsfolgen'";
CM_ SG_ 312 IPA_Anforderung_HMS "Anforderung vom IPA (Intelligent Park Assist) an das HMS (Haltemanagement System)";
CM_ SG_ 312 IPA_Fahrtaster_LED "Ansteuerung der Funktions-LED vom IPA Fahrtaster. Pulsieren = LED Auf- und Abdimmen
0 = Init_Inaktiv
1 = LED Pulsieren";
CM_ SG_ 312 IPA_Fahrstufenwunsch "Anforderung zum Einlegen der erforderlichen Fahrstufe";
CM_ SG_ 312 IPA_TSK_zul_Regelabw "Zulässige Regelabweichung für Beschleunigungsanforderungen";
CM_ SG_ 312 IPA_Status_IPA_GE "Darstellung des internen Status der Funktion IPA. Dient als Steuersignal für Statusmaschinen im Getriebe-SG (Handshakemechanismus)";
CM_ SG_ 312 IPA_Status_IPA_TSK "Statusinformation vom IPA für Handshakemechanismus mit TSK";
CM_ SG_ 312 IPA_Sollbeschleunigung "Anforderung vom IPA an den TSK, das Fahrzeug zu beschleunigen.";
CM_ SG_ 312 IPA_PLA_LED "Ansteuerung der PLA Funktions-LED durch das BCM.
0 = LED aus
1 = LED ein
2 = LED blinken
3 = Funktion gesperrt, LED aus
4 = frei
5 = frei
6 = Init
7 = frei";
CM_ SG_ 312 IPA_APS_LED "Ansteuerung der APS Funktions-LED durch das BCM.
0 = LED aus
1 = LED ein
2 = LED blinken
3 = Funktion gesperrt, LED aus
4 = frei
5 = frei
6 = Init
7 = frei";
CM_ SG_ 1863 ISO_AAG_Req_Data "Diagnose Request Anhaengeranschlussgeraet";
CM_ SG_ 1969 ISO_AAG_Resp_Data "Diagnose Response Anhaengeranschlussgeraet";
CM_ SG_ 1841 ISO_ELV_Req_Data "Diagnose Request Elektronische Lenkradverriegelung";
CM_ SG_ 1947 ISO_ELV_Resp_Data "Diagnose Response Elektronische Lenkradverriegelung";
CM_ SG_ 1792 ISO_ALL_01_Req_Data "Funktionaler Request ALL";
CM_ SG_ 1827 ISO_HDSG_Req_Data "Diagnose Request Heckdeckelsteuergeraet";
CM_ SG_ 1933 ISO_HDSG_Resp_Data "Diagnose Response Heckdeckelsteuergeraet";
CM_ SG_ 1842 ISO_Kessy_Req_Data "Diagnose Request Keyless Entry System";
CM_ SG_ 1948 ISO_Kessy_Resp_Data "Diagnose Response Keyless Entry System";
CM_ SG_ 1836 ISO_MFG_Req_Data "Diagnose Request Multifunktionssteuergeraet";
CM_ SG_ 1942 ISO_MFG_Resp_Data "Diagnose Resonse Multifunktionssteuergeraet";
CM_ BO_ 2549350921 "Datenübertragung vom OBDC zum Datenanforderer SKEY";
CM_ SG_ 2549350921 ISO_OBDC_SKEY_Req_Data "Kommunikation zwischen OBDC (Onboard Data Collector) und Datenanforderer SKEY (ServiceKey)";
CM_ BO_ 2549483778 "Datenübertragung vom OBDC zum Datenanforderer SKEY";
CM_ SG_ 2549483778 ISO_OBDC_SKEY_Resp_Data "Kommunikation zwischen Datenanforderer  SKEY (ServiceKey) und OBDC (Onboard Data Collector)";
CM_ BO_ 2549350923 "Datenübertragung vom OBDC zum Datenanforderer SKEY";
CM_ SG_ 2549350923 ISO_OBDC_VSR_Req_Data "Kommunikation zwischen OBDC (Onboard Data Collector) und Datenanforderer OPR (Online Pannenruf)";
CM_ BO_ 2549484290 "Datenübertragung vom OBDC zum Datenanforderer SKEY";
CM_ SG_ 2549484290 ISO_OBDC_VSR_Resp_Data "Kommunikation zwischen Datenanforderer  SKEY (ServiceKey) und OBDC (Onboard Data Collector)";
CM_ SG_ 1869 ISO_Sitzmemo_BFS_Req_Data "Diagnose Request Sitzmemory Beifahrer";
CM_ SG_ 1975 ISO_Sitzmemo_BFS_Resp_Data "Diagnose Response Sitzmemory Beifahrer";
CM_ SG_ 1868 ISO_Sitzmemo_FS_Req_Data "Diagnose Request Sitzmemory Fahrer";
CM_ SG_ 1974 ISO_Sitzmemo_FS_Resp_Data "Diagnose Response Sitzmemory Fahrer";
CM_ BO_ 2549352706 "Request von SKEY an OBDC";
CM_ SG_ 2549352706 ISO_SKEY_OBDC_Req_Data "Kommunikation zwischen Datenanforderer SKEY (ServiceKey) und OBDC (Onboard Data Collector)";
CM_ BO_ 2549481993 "Response von OBDC an SKEY";
CM_ SG_ 2549481993 ISO_SKEY_OBDC_Resp_Data "Kommunikation zwischen Datenanforderer SKEY (ServiceKey) und OBDC (Onboard Data Collector)";
CM_ SG_ 1828 ISO_SpoilerSG_Req_Data "Diagnose Request Spoilersteuergeraet";
CM_ SG_ 1934 ISO_SpoilerSG_Resp_Data "Diagnose Response Spoilersteuergeraet";
CM_ SG_ 1835 ISO_STS_Req_Data "Diagnose Request Schnittstellen-Tracking-System";
CM_ SG_ 1941 ISO_STS_Resp_Data "Diagnose Response Schnittstellen-Tracking-System";
CM_ SG_ 1867 ISO_TSG_BT_Req_Data "Diagnose Request Tuersteuergeraet Beifahrer";
CM_ SG_ 1973 ISO_TSG_BT_Resp_Data "Diagnose Response Tuersteuergeraet Beifahrer";
CM_ SG_ 1866 ISO_TSG_FT_Req_Data "Diagnose Request Tuersteuergeraet Fahrer";
CM_ SG_ 1972 ISO_TSG_FT_Resp_Data "Diagnose Response Tuersteuergeraet Fahrer";
CM_ SG_ 1855 ISO_TSG_HBFS_Req_Data "Diagnose Request Tuersteuergeraet hinten rechts";
CM_ SG_ 1961 ISO_TSG_HBFS_Resp_Data "Diagnose Response Tuersteuergeraet hinten rechts";
CM_ SG_ 1854 ISO_TSG_HFS_Req_Data "Diagnose Request Tuersteuergeraet hinten links";
CM_ SG_ 1960 ISO_TSG_HFS_Resp_Data "Diagnose Response Tuersteuergeraet hinten links";
CM_ SG_ 1837 ISO_VSG_Req_Data "Diagnose Request Verdeck-Steuergeraet";
CM_ SG_ 1943 ISO_VSG_Resp_Data "Diagnose Response Verdeck-Steuergeraet";
CM_ BO_ 2549353218 "Datenanforderer VSR fordert Daten vom OBDC ab";
CM_ BO_ 2549481995 "Datenverteiler VSR fordert Daten vom OBDC ab";
CM_ BO_ 2549874818 "Lichtsteuerung links am Frontlicht-CAN";
CM_ SG_ 2549874818 ISO_LCM_L_Req_Data "Diagnose Request Light Control Module links";
CM_ BO_ 2550005890 "Lichtsteuerung links am Frontlicht-CAN";
CM_ SG_ 2550005890 ISO_LCM_L_Resp_Data "Diagnose Response Light Control Module links";
CM_ BO_ 2549874819 "Lichtsteuerung rechts am Frontlicht-CAN";
CM_ SG_ 2549874819 ISO_LCM_R_Req_Data "Diagnose Request Light Control Module rechts";
CM_ BO_ 2550005891 "Lichtsteuerung rechts am Frontlicht-CAN";
CM_ SG_ 2550005891 ISO_LCM_R_Resp_Data "Diagnose Response Light Control Module rechts";
CM_ BO_ 2549874838 "Lichtsteuerung links am Frontlicht-CAN";
CM_ SG_ 2549874838 ISO_LED_LM_L_Req_Data "Diagnose Request Steuergeraet für LED-Scheinwerfer links";
CM_ BO_ 2550005910 "Lichtsteuerung links am Frontlicht-CAN";
CM_ SG_ 2550005910 ISO_LED_LM_L_Resp_Data "Diagnose Response Steuergeraet für LED-Scheinwerfer links";
CM_ BO_ 2549874839 "Lichtsteuerung links am Frontlicht-CAN";
CM_ SG_ 2549874839 ISO_LED_LM_R_Req_Data "Diagnose Request Steuergeraet für LED-Scheinwerfer rechts";
CM_ BO_ 2550005911 "Lichtsteuerung links am Frontlicht-CAN";
CM_ SG_ 2550005911 ISO_LED_LM_R_Resp_Data "Diagnose Response Steuergeraet für LED-Scheinwerfer rechts";
CM_ SG_ 2549874848 ISO_SAD2_Req_Data "Diagnose Request Schiebeausstelldach 2";
CM_ SG_ 2550005920 ISO_SAD2_Resp_Data "Diagnose Response Schiebeausstelldach 2";
CM_ SG_ 2549874820 ISO_SAD_Req_Data "Diagnose Request Schiebeausstelldach";
CM_ SG_ 2550005892 ISO_SAD_Resp_Data "Diagnose Response Schiebeausstelldach";
CM_ SG_ 2549874843 ISO_SBBR_Req_Data "Diagnose Request Schluss Brems Blink Rueckleuchte";
CM_ SG_ 2550005915 ISO_SBBR_Resp_Data "Diagnose Response Schluss Brems Blink Rueckleuchte";
CM_ SG_ 2549874824 ISO_Sitzmemo_HBFS_Req_Data "Diagnose Request Sitzmemory hinten rechts";
CM_ SG_ 2550005896 ISO_Sitzmemo_HBFS_Resp_Data "Diagnose Response Sitzmemory hinten rechts";
CM_ SG_ 2549874823 ISO_Sitzmemo_HFS_Req_Data "Diagnose Request Sitzmemory hinten links";
CM_ SG_ 2550005895 ISO_Sitzmemo_HFS_Resp_Data "Diagnose Response Sitzmemory hinten links";
CM_ SG_ 2549874837 ISO_Sitzmemo_SR3_Req_Data "Diagnose Request Sitzmemory SR3";
CM_ SG_ 2550005909 ISO_Sitzmemo_SR3_Resp_Data "Diagnose Response Sitzmemory SR3";
CM_ SG_ 497 FBS_IDG_in_Reichweite "Für elektrisch betätigte Türen und Klappen muss für eine Betätigung über Funk eine Reichweitenbegrenzung eingeführt werden. Diese Bit zeigt an, dass sich der Funkschlüssel innerhalb der geforderten Reichweite befindet";
CM_ SG_ 497 FFB_Auf_Taste "Auf-Taste Funkschluessel

";
CM_ SG_ 497 FFB_HDF_Taste "HDF Taste am Funkschluessel
";
CM_ SG_ 497 FFB_Panik_Taste "Panik Taste Funkschluessel
";
CM_ SG_ 497 FFB_Zu_Taste "Zu-Taste Funkschluessel
";
CM_ SG_ 497 KY_FT_Entriegelung_Autorisiert "Erkennung / Authorisierung Keyless FT
";
CM_ SG_ 497 KY_FT_Verriegelung_Autorisiert "Authorisierung Verriegelungssensor Keyless FT
";
CM_ SG_ 497 KY_BT_Entriegelung_Autorisiert "Erkennung / Authorisierung Keyless BT
";
CM_ SG_ 497 KY_BT_Verriegelung_Autorisiert "Authorisierung Verriegelungssensor Keyless BT
";
CM_ SG_ 497 KY_HFS_Entriegelung_Autorisiert "Erkennung / Authorisierung Keyless HFS
";
CM_ SG_ 497 KY_HFS_Verriegelung_Autorisiert "Authorisierung Verriegelungssensor Keyless HFS

";
CM_ SG_ 497 KY_HBFS_Entriegelung_Autorisiert "Erkennung / Authorisierung Keyless HBFS
";
CM_ SG_ 497 KY_HBFS_Verriegelung_Autorisiert "Authorisierung Verriegelungssensor Keyless HBFS


";
CM_ SG_ 497 KY_Front_Entr_Autorisiert "Erkennung / Authorisierung Keyless Front";
CM_ SG_ 497 KY_Front_Verr_Autorisiert "Authorisierung Verriegelungssensor Keyless Front";
CM_ SG_ 497 KY_HD_Entriegelung_Autorisiert "Erkennung / Authorisierung Keyless Heck
";
CM_ SG_ 497 KY_HD_Verriegelung_Autorisiert "Autorisierung der Schließanforderung über Verriegelungsinnentaster";
CM_ SG_ 497 KY_Bereich "Schlüsselentfernung für Funktionen Annäherungslicht, automatisches Entriegeln";
CM_ SG_ 497 KY_Position "Schlüsselposition für Funktionen Annäherungslicht, automatisches Entriegeln";
CM_ SG_ 497 KY_ZV_Signatur "Signatur der ZV";
CM_ SG_ 497 Schluesselnr_Personalisierung "Signal gibt die jewels aktuelle Schlüsselnummer für die Personalisierung wieder";
CM_ SG_ 497 FFB_FDF_Taste "FDF Taste am Funkschluessel";
CM_ SG_ 497 FFB_Joker_Taste "Frei konfigurierbare Taste auf der Funkfernbedienung (für Verdecktaste, UGDO Taste).
";
CM_ SG_ 1424 FBS_Warn_Schluessel_Batt "Kombi Prio Warnung Schluessel Batterie
'Bitte Schlüsselbatterie wechseln!'";
CM_ SG_ 1424 KY_FFB_Frequenz "Frequenz FFB
";
CM_ SG_ 1424 KY_HF_Aktiv "HF Funkempfang
";
CM_ SG_ 1424 KY_LF_Aktiv "LF Schluesselkommunikation
";
CM_ SG_ 1424 KY_KYL_Fahrer_Hinweise "Kombi Fahrer Hinweise Keyless
Audi/VW
0x04 Kein Schlüssel erkannt";
CM_ SG_ 1424 KY_StartStopp_Info "Stopp-Freigabe und Start-Anforderung an den Start-Stopp-Koordinator";
CM_ SG_ 1424 KY_Keyless_Verbau "Verbauinfo Keyless 
";
CM_ SG_ 1424 KY_Keyless_Go_Verbau "Verbauinfo Keyless Go
";
CM_ SG_ 1424 KY_Kombinierte_Notspule "Verbau Kombinierte Notspule, Keyless-Antenne";
CM_ SG_ 1424 KYL_Warn_kein_Schluessel "Kombi Prio Warnung Keyless 
'Schlüssel nicht im Fahrzeug!'
";
CM_ SG_ 1424 KYL_Warn_Kessy_defekt "Kombi Prio Warnung Keyless
'Keyless Go defekt, Zündschloß benutzen'";
CM_ SG_ 1424 KYL_Warn_Notzuendschloss "Aufforderung an den Benutzer, den Schlüsssel an die Notspule zu halten, wenn Kessy den Schlüssel nicht finden kann
'Keyless Go defekt. Zum Starten den Schlüssel vor das Symbol halten!'";
CM_ SG_ 1424 KY_Fzg_Verlassen_erkannt "Fahrer/Schlüssel hat das Fahrzeug verlassen und FT wurde geschlossen";
CM_ SG_ 1424 KY_Fzg_Zugang_erkannt "Fahrer/Schlüssel hat Fahrzeug betreten und die FT geschlossen";
CM_ SG_ 1424 KST_Wegstrecke_Challenge "Wegstreckenchallenge ans Kombi und ESC";
CM_ BO_ 960 "MQB";
CM_ SG_ 960 Klemmen_Status_01_CRC "Für MLB:
'Berechnung siehe Lastenheft 'Kommunikationsabsicherung für FlexRay und CAN''

Ab MQB und MLBevo:
'Berechnung siehe Lastenheft 'End-to-End Kommunikationsabsicherung''

Endwerte siehe Begleitdokument 'S-PDU Kennungsfolgen'";
CM_ SG_ 960 Klemmen_Status_01_BZ "4bit Botschaftszaehler; wird in jeder Sendebotschaft inkrementiert";
CM_ SG_ 960 ZAS_Kl_S "Klemme S: S-Kontakt (Schluessel steckt)
";
CM_ SG_ 960 ZAS_Kl_15 "Klemme 15: Zuendung (SW-Kl.15)
";
CM_ SG_ 960 ZAS_Kl_X "Klemme 75
";
CM_ SG_ 960 ZAS_Kl_50_Startanforderung "Klemme 50: Startwunsch Fahrer
";
CM_ SG_ 960 BCM_Remotestart_Betrieb "Zeigt den Status des RemoteStarts an, d.h. KL15_RSt ist aktiviert und der Motorlauf ist im RSt-Betrieb aktiv.";
CM_ SG_ 960 ZAS_Kl_Infotainment "Separate Klemmeninformation für das Infotainment. Signal entspricht im wesentlichen einer Klemme S Information, kann aber über einen Vor - bzw. Nachlauf zu Klemme S verfügen. 
Ein konkreter Anwendungsfall für einen Nachlauf ist die Abschaltung der Klemme";
CM_ SG_ 960 BCM_Remotestart_KL15_Anf "Zeigt den Status der Aktivierung der KL15_RST durch das BCM an.";
CM_ SG_ 960 BCM_Remotestart_MO_Start "Nachdem das BCM die Remotestart MSG Freigabe sicher erkannt hat, fordert das BCM wiederum über dieses Signal vom MSG einen Motorstart durchzuführen.";
CM_ SG_ 960 KST_Warn_P1_ZST_def "Kombi Prio Warnung Klemmensteuerung 
Zündschloß defekt, Service aufsuchen!";
CM_ SG_ 960 KST_Warn_P2_ZST_def "Kombi Prio Warnung Klemmensteuerung
Zündschloß defekt!
";
CM_ SG_ 960 KST_Fahrerhinweis_1 "Signalisierung Fahrerhinweis 1 der Klemmensteuerung an das Kombi";
CM_ SG_ 960 KST_Fahrerhinweis_2 "Signalisierung Fahrerhinweis 2 der Klemmensteuerung an das Kombi";
CM_ SG_ 960 KST_Fahrerhinweis_3 "Signalisierung Fahrerhinweis 3 der Klemmensteuerung an das Kombi";
CM_ SG_ 960 KST_Fahrerhinweis_4 "Signalisierung Fahrerhinweis 4 der Klemmensteuerung an das Kombi";
CM_ SG_ 960 KST_Fahrerhinweis_5 "Signalisierung Fahrerhinweis 5 der Klemmensteuerung an das Kombi";
CM_ SG_ 960 KST_Fahrerhinweis_6 "Signalisierung Fahrerhinweis 6 der Klemmensteuerung an das Kombi";
CM_ SG_ 1420 Klemmen_Steuerung_01_CRC "Ab MQB und MLBevo:
'Berechnung siehe Lastenheft 'End-to-End Kommunikationsabsicherung''

Endwerte siehe Begleitdokument 'S-PDU Kennungsfolgen'";
CM_ SG_ 1420 Klemmen_Steuerung_01_BZ "4bit Botschaftszaehler; wird in jeder Sendebotschaft inkrementiert";
CM_ SG_ 1420 KST_Txt_P_Gang "Text: 'Wählhebel in Position P bringen!'";
CM_ SG_ 1420 KST_Txt_Panikabschaltung "Text: 'Notabschaltung''";
CM_ SG_ 1420 KST_Anf_Klemmenfreigabe_ELV "Klemmensteuerung fordert Klemmen-Freigabe durch die ELV an.";
CM_ SG_ 1420 KST_Txt_Komfortabschaltung "Dieses Signal fordert im Kombi die Meldung an, die den Fahrer über die ausgeführte automatische Zündungsabschaltung informiert. Signal wird für10s gesendet.";
CM_ SG_ 1420 KST_ZAT_betaetigt "Zündanlass-Taster (ZAT) betätigt";
CM_ SG_ 1420 KST_Unterdr_Zuendungsmeldung "Bei aktivem Signal soll die Zündungsmeldung durch das Kombi unterdrückt werden.";
CM_ SG_ 1420 KST_aut_Abschaltung_Zuendung "Falls bei eingeschalteter Zündung das Abblendlicht aktiv war, muss nach der automatischen Abschaltung der Kl_15 & Kl_S, dass Standlicht aktiv bleiben. Das Signal sendet die Information, dass eine automatische Abschaltung der Kl_15 und Kl_S erfogt.";
CM_ SG_ 1420 KST_Anf_ZV_Verriegelung "Neuer Verriegelungstrigger für die ZV nach der automatischen Klemmenabschaltung.

Wird bei Kessyfahrzeugen mit StartStop ein aktiver Stop-Mode und Fahrerverlassen erkannt, startet ein 30 Sekunden-Timer. Innerhalb dieser 30 Sekunden hat der Fahrer die Mö";
CM_ BO_ 1646 "ab MQB 7.3";
CM_ SG_ 1646 KL_STL_aktiv "Betriebsstatus Standlueftung
";
CM_ SG_ 1646 KL_STH_aktiv "Betriebsstatus Standheizung
";
CM_ SG_ 1646 KL_Solarluefter_aktiv "Betriebsstatus Solarluefter
";
CM_ SG_ 1646 KL_Umluft_Taste "Betaetigung Umlufttaste
";
CM_ SG_ 1646 KL_Geblaese_Fond_Status "Status Geblaese









";
CM_ SG_ 1646 KL_STH_Ansteuerung "Ansteuerung STH

";
CM_ SG_ 1646 KL_STH_Betriebsdauer "Betriebsdauer STH";
CM_ SG_ 1646 KL_Magnetventil "Anforderung des Bypassventils.";
CM_ SG_ 1646 KL_WaPu "Ansteuerung der Standheizungswasserpumpe";
CM_ SG_ 1646 KL_Geblaese_Status "Status Geblaese









";
CM_ SG_ 1646 KL_Restwaerme_aktiv "Signal zur Aktivierung/Deaktivierung der Wasserpumpe bei Restwärme; 
reduzierte IRÜ Empfindlichkeit";
CM_ SG_ 1646 KL_Kompressorkupplung "Signal zur Aktivierung/Deaktivierung der Kompressorkupplung";
CM_ SG_ 1646 KL_BCmE_Livetip_Freigabe "Status der Klimaanlage. 
Zeigt an, ob der Livetip 'Fenster schließen wegen Ineffizienz Klimaanlage' sinvollerweise angezeigt werden soll

MQB: nur Audi relevant";
CM_ SG_ 1646 KL_HYB_ASV_hinten_schliessen_Anf "Anforderung der Klima an das BMS, das Absperrventil des Kältemittelkreislaufs zur Batteriekühlung zu schliessen";
CM_ SG_ 1646 KL_HYB_ASV_vorne_schliessen_Anf "Anforderung der Klima an das BMS, das Absperrventil des Kältemittelkreislaufs der Klimaanlage zu schliessen";
CM_ SG_ 1646 KL_HYB_Spuelbetrieb_Freigabe "Status der Klimaanlage. Zeigt dem BMS an, ob der Spülbetrieb möglich ist";
CM_ SG_ 1646 KL_Innen_Temp "Innentemperatur

";
CM_ SG_ 1646 KL_FSH_Automatikbetrieb "Ermöglicht eine Unterscheidung von Anforderung FSH durch Kundenwunsch und Anforderung FSH durch Regelung des Klimasteuergeräts.
Das Signal liegt als Pegel an.";
CM_ SG_ 1646 KL_SIH_LEH_Verteilung_VL "Vom Kunden eingestellte Aufteilung der Heizleistung auf Sitzfläche und Lehnefläche für Sitz vorne links";
CM_ SG_ 1646 KL_SIH_LEL_Verteilung_VL "Vom Kunden eingestellte Aufteilung der Lüftungsleistung auf Sitzfläche und Lehnenfläche für Sitz vorne links";
CM_ SG_ 1646 KL_SIH_LEH_Verteilung_VR "Vom Kunden eingestellte Aufteilung der Heizleistung auf Sitzfläche und Lehnefläche für Sitz vorne rechts";
CM_ SG_ 1646 KL_SIH_LEL_Verteilung_VR "Vom Kunden eingestellte Aufteilung der Lüftungsleistung auf Sitzfläche und Lehnenfläche für Sitz vorne rechts";
CM_ BO_ 949 "ab MQB 7.4";
CM_ SG_ 949 KL_Drehz_Anh "Drehzahlanhebung vom Motor angefordert

";
CM_ SG_ 949 KL_Vorwarn_Komp_ein "Vorwarnung Kompressor ein; 140ms vorher; Information für Motor zum Aufbau Momentenreserve";
CM_ SG_ 949 KL_AC_Schalter "AC Schalter
";
CM_ SG_ 949 KL_Vorwarn_Zuheizer_ein "Vorwarnung Zuheizerbetrieb
";
CM_ SG_ 949 KL_Zustand "Betrieb Klimaanlage
";
CM_ SG_ 949 KL_Kompressorkupplung_linear "Sollwert zur Ansteuerung der Kompressorkupplung";
CM_ SG_ 949 KL_Charisma_FahrPr "MLBevo: Aktuelles Fahrprogramm des Charisma-Teilnehmers (siehe Systemlastenheft Drive Select)
MQB: Istwert der Kennlinie (siehe Systemlastenheft MQB FPA)";
CM_ SG_ 949 KL_Charisma_Status "Charisma Systemstatus des Charisma-Teilnehmers

Wert 0x3 ist nur für Fahrzeuge ab MQB relevant";
CM_ SG_ 949 KL_nachtr_Stopp_Anf "Dieses Signal dient dem Motor als Trigger, dass ein nachträglicher Motorstopp eingeleitet werden kann, wenn es die Bedingungen des StSt Koordinators dies zulassen. ";
CM_ SG_ 949 KL_T_Charge "Signal für Tastenbetätigung Charge-Taste (SOC Increasing)";
CM_ SG_ 949 KL_Last_Kompr "Aktuelles Verlustmoment der Klimaanlage bezogen auf die Kurbelwelle. Wird der Klimakompressor nicht angesteuert, ist das Schleppmoment bezogen auf die Kurbelwelle zu senden.";
CM_ SG_ 949 KL_Spannungs_Anf "Forderung des Klima-SG's zur Spannungsanhebung.";
CM_ SG_ 949 KL_Thermomanagement "Stufen des Thermomanagements;
Bei Klemme 15 AUS und erkannten Timeout zum Klimabedienteil (z.B. Klimabedienteil während des Motorsteuergeräte-Kommunikations-Nachlaufs bereits im NM-Zustand ¿Bus Sleep¿)
erfolgt keine Ansteuerung der Wasserpumpe durch die";
CM_ SG_ 949 KL_StartStopp_Info "Stopp-Freigabe und Start-Anforderung an den Start-Stopp-Koordinator";
CM_ SG_ 949 KL_Freilauf_Info "Freilauf Informationssignal von Klima zum Freilaufkoordinator. Klima kann über dieses Signal den Freilauf freigeben, verhindern bzw. explizit anfordern.";
CM_ SG_ 949 KL_Anf_KL "Anforderung Kühlerlüfter der Klimaanlage in Prozent

";
CM_ SG_ 949 KL_el_Zuheizer_Stufe "Vorgabe für Motorsteuergeraet PTC-Stufe; im MLB-B8 und MQB nur Stufe 0...3

";
CM_ SG_ 949 KL_Ausstattung_Klima "Austtattungsart der Klimabedienung";
CM_ BO_ 1640 "ab MQB IS-4";
CM_ SG_ 1640 KL_LRH_Taster "Tasterbetätigung Lenkradheizung";
CM_ SG_ 1640 KL_LRH_Stufe "Eingestellte Temperaturstufe der Lenkradheizung";
CM_ SG_ 1640 HSH_Taster "An-/Abforderung Heckscheibenheizung über spezielles Tastersignal
";
CM_ SG_ 1640 FSH_Taster "Tasterbetätigung Frontscheibenheizung
";
CM_ SG_ 1640 KL_Zuheizer_Freigabe "Freigabe Zuheizer
";
CM_ SG_ 1640 KL_Beschlagsgefahr "Beschlagsgefahr auf der Frontscheibe im Bereich des Spiegelfusses. Dient zur präventiven Ansteuerung der  Kamera-Scheibenheizung, um Kamera-Blindheit zu vermeiden
PHEV: volle Leistungsfreigabe 
HV Heizer und HV EKK bei Scheibenbeschlag ";
CM_ SG_ 1640 KL_SIH_Soll_li "Einstellung Sitzheizung Fahrer (0...6)";
CM_ SG_ 1640 KL_SIH_Soll_re "Einstellung Sitzheizung Beifahrer (0...6)";
CM_ SG_ 1640 KRH_Soll_li "Ausgabe des Sollwertes für die Kopfraumheizung links.";
CM_ SG_ 1640 KL_SIL_Soll_li "Einstellung Sitzlüftung Fahrer (0...6)";
CM_ SG_ 1640 KL_SIL_Soll_re "Einstellung Sitzlüftung Beifahrer (0...6)";
CM_ SG_ 1640 KRH_Soll_re "Ausgabe des Sollwertes für die Kopfraumheizung rechts.";
CM_ SG_ 1640 KL_Geblspng_Soll "Ausgabe des Sollwertes für die Spannung des Klimagebläsemotores vorne.







";
CM_ SG_ 1640 KL_Geblspng_Fond_Soll "Ausgabe des Sollwertes für die Spannung des Klimagebläsemotores hinten.






";
CM_ SG_ 1640 KL_I_Geblaese "Stromaufnahme Gebläse";
CM_ SG_ 1640 KL_Kompressorstrom_soll "Sollvorgabe Klima-Kompressorstrom";
CM_ SG_ 1640 KL_Umluftklappe_Status "Status Umluftklappe

";
CM_ SG_ 1640 KL_PTC_Verbauinfo "Im Klima- bzw. Heizungsbedienteil wird der Verbau eines PTCs und dessen elektr. Leistungsklasse codiert";
CM_ SG_ 1441 KL_Temp_Soll_hl "Eingestellte Solltemperatur hinten links für verteilte Komfortfunktionen";
CM_ SG_ 1441 KL_Temp_Soll_hr "Eingestellte Solltemperatur hinten rechts für verteilte Komfortfunktionen";
CM_ SG_ 1441 KL_Temp_Soll_vl "Eingestellte Solltemperatur vorne links für verteilte Komfortfunktionen";
CM_ SG_ 1441 KL_Temp_Soll_vr "Eingestellte Solltemperatur vorne rechts für verteilte Komfortfunktionen";
CM_ SG_ 1441 KL_SIH_Stufe_hl "Eingestellte Sitzheizungsstufe hinten links für verteilte Komfortfunktionen";
CM_ SG_ 1441 KL_SIH_Stufe_hr "Eingestellte Sitzheizungsstufe hinten rechts für verteilte Komfortfunktionen";
CM_ SG_ 1441 KL_SIL_Stufe_hl "Eingestellte Sitzlüftungsstufe hinten links für verteilte Komfortfunktionen";
CM_ SG_ 1441 KL_SIL_Stufe_hr "Eingestellte Sitzlüftungsstufe hinten rechts für verteilte Komfortfunktionen";
CM_ SG_ 1441 KL_SIL_LEL_Verteilung_HR "Vom Kunden eingestellte Aufteilung der Lüftungsleistung auf Sitzfläche und Lehnenfläche für Sitz hinten rechts";
CM_ SG_ 1441 KL_SIL_LEL_Verteilung_HL "Vom Kunden eingestellte Aufteilung der Lüftungsleistung auf Sitzfläche und Lehnenfläche für Sitz hinten links";
CM_ SG_ 1441 KL_SIH_LEH_Verteilung_HR "Vom Kunden eingestellte Aufteilung der Heizleistung auf Sitz und Lehne für Sitz hinten rechts.";
CM_ SG_ 1441 KL_PTC_linear_Anf "Kundenanforderung des PTC (linear)";
CM_ SG_ 1441 KL_SIH_LEH_Verteilung_HL "Vom Kunden eingestellte Aufteilung der Heizleistung auf Sitz und Lehne für Sitz hinten links";
CM_ SG_ 1441 KL_Frischluftklappe_Status "Aktuelle Position der Frischluftklappe";
CM_ SG_ 992 KL_Fond_Fuss_Temp_hl "Fussraumtemperatur hinten links";
CM_ SG_ 992 KL_SL_Soll_hl "Einstellung Sitzlüftung hinten links (0...6)";
CM_ SG_ 992 KL_SL_Soll_hr "Einstellung Sitzlüftung hinten rechts (0...6)";
CM_ SG_ 992 KL_Fond_Fuss_Temp_hr "Fussraumtemperatur hinten rechts";
CM_ SG_ 992 KL_SH_Soll_hl "Einstellung Sitzheizung hinten links (0...6)";
CM_ SG_ 992 KL_SH_Soll_hr "Einstellung Sitzheizung hinten rechts (0...6)";
CM_ SG_ 992 KL_MA_Temp_hl "Mannanstroemer hinten links Temperatur";
CM_ SG_ 992 KL_SIH_Takt_hl "Ein-Aus Taktung Sitzheizung hinten links";
CM_ SG_ 992 KL_SIH_Takt_hr "Ein-Aus Taktung Sitzheizung hinten rechts";
CM_ SG_ 992 KL_Fehler_Umluft "Status Umluftklappe";
CM_ SG_ 992 KL_RAB "Risiko-Abschätzungs- und Bewertungs-Bit";
CM_ SG_ 992 KL_Fond_Absperrventil "Absperrventil";
CM_ SG_ 992 KL_Fond_KD_Fehler "Status Kundendienstfehlerspeichereinträge

";
CM_ SG_ 992 KL_MA_Temp_hr "Mannanstroemer hinten rechts Temperatur";
CM_ SG_ 992 KL_Fehler_Fussraum_Klappen "Fehler in den Fußraumklappen werden gemeldet";
CM_ SG_ 992 KL_Fehler_Temp_Klappen "Fehler in den Temperaturklappen werden gemeldet";
CM_ SG_ 992 KL_Fehler_Temp_MA_Klappen "Fehler in den MA-Klappen werden gemeldet";
CM_ BO_ 1712 "D4 und B8-PA

1:1 LIN-CAN Botschaft, nur bei Kl.15 EIN gesendet";
CM_ SG_ 1712 FS_ResponseError "siehe LIN2.0-Specification
(Darf nicht über ein Fehlergueltigkeitsbit abgesichtert werden!)";
CM_ BO_ 1505 "ab MQB 7.3";
CM_ SG_ 1505 BCM1_Aussen_Temp_ungef "ungefilterter Wert des Aussentemperatursensors
";
CM_ SG_ 1505 BCM_Heizungsabsperrventil_Status "Das Signal beschreibt den Zustand des Heizungsabsperrventils, welches als Portexpander vom BCM1 elektrisch angesteuert wird.";
CM_ SG_ 1505 BCM_Heizungspumpe_Status "Das Signal beschreibt den Zustand der Heizungspumpe, welche als Portexpander vom BCM1 elektrisch angesteuert wird.";
CM_ SG_ 1505 BCM_Kompressorkupplung_Status "Das Signal beschreibt den Zustand der Klimakompressorkupplung, welche als Portexpander vom BCM1 elektrisch angesteuert wird.";
CM_ SG_ 1505 BCM1_PTC_stufig_Status "Status des BCM1-Heizverbrauchers PTC (stufig)";
CM_ SG_ 1505 BCM1_FStatus_Aussentemp_ungef "Fehlerstatus für Aussentemperatur (Kombianzeige)";
CM_ SG_ 1505 BCM1_Kompressorstrom_ist "IST-Strom vom Klima-Kompressor";
CM_ SG_ 1505 BCM1_OBD_FStatus_ATemp "Fehlerstatus Umgebungstemperatursensor (OBD relevanter Sensor)
";
CM_ SG_ 2549088327 AAG_KompSchutz "Funktionseinschränkung aufgrund Komponentenschutz aktiv";
CM_ SG_ 2549088327 AAG_Abschaltstufe "Funktionseinschränkung aufgrund aktiver Abschaltstufe";
CM_ SG_ 2549088327 AAG_Transport_Mode "Funktionseinschränkung aufgrund aktivem Transport Mode und/oder Transport Schutz
";
CM_ SG_ 2549088327 AAG_Nachlauftyp "Abgebildet wird die von der Hardware vorgegebene Möglichkeit, die Kommunikation nach Klemme 15 = AUS aufrecht zu erhalten. Es wird ein Init-Wert gesendet.
0 = Kommunikation nur bei KL15=EIN (kein Nachlauf, nicht weckfähig)
1 = Kommunikation nach KL15=AU";
CM_ SG_ 2549088327 AAG_SNI "Das Signal beinhaltet den Source Node Identifier (Knotenadresse, die auch in der Abbildungsvorschrift zur CAN-ID für die NM-High Botschaft verwendet wird).";
CM_ SG_ 2549088327 NM_AAG_Wakeup "enthält die Weckursache; stehen mehrere Weckursachen parallel an, dann muss der kleinste Wert übertragen werden";
CM_ SG_ 2549088327 NM_AAG_Lokalaktiv "Zeigt an ob das SG nach Klemme15 AUS und nach entsprechender MAX Aktivzeit noch aktiv war";
CM_ SG_ 2549088327 NM_AAG_Subsystemaktiv "Zeigt an ob ein Subsystem des SGs nach Klemme15 AUS und nach entsprechender MAX Aktivzeit noch aktiv war";
CM_ SG_ 2549088327 AAG_KD_Fehler "Status Kundendienst-Fehlerspeicher";
CM_ SG_ 2549088270 BCM1_KompSchutz "Funktionseinschränkung aufgrund Komponentenschutz aktiv";
CM_ SG_ 2549088270 BCM1_Abschaltstufe "Funktionseinschränkung aufgrund aktiver Abschaltstufe";
CM_ SG_ 2549088270 BCM1_Transport_Mode "Funktionseinschränkung aufgrund aktivem Transport Mode und/oder Transport Schutz";
CM_ SG_ 2549088270 BCM1_Nachlauftyp "Abgebildet wird die von der Hardware vorgegebene Möglichkeit, die Kommunikation nach Klemme 15 = AUS aufrecht zu erhalten. Es wird ein Init-Wert gesendet.
0 = Kommunikation nur bei KL15=EIN (kein Nachlauf, nicht weckfähig)
1 = Kommunikation nach KL15=AU";
CM_ SG_ 2549088270 BCM1_SNI "Das Signal beinhaltet den Source Node Identifier (Knotenadresse, die auch in der Abbildungsvorschrift zur CAN-ID für die NM-High Botschaft verwendet wird).";
CM_ SG_ 2549088270 NM_BCM1_Wakeup "enthält die Weckursache; stehen mehrere Weckursachen parallel an, dann muss der kleinste Wert übertragen werden";
CM_ SG_ 2549088270 NM_BCM1_Lokalaktiv "Zeigt an ob das SG nach Klemme15 AUS und nach entsprechender MAX Aktivzeit noch aktiv war";
CM_ SG_ 2549088270 NM_BCM1_Subsystemaktiv "Zeigt an ob ein Subsystem des SGs nach Klemme15 AUS und nach entsprechender MAX Aktivzeit noch aktiv war";
CM_ SG_ 2549088270 BCM1_KD_Fehler "Status Kundendienstfehlerspeichereinträge
";
CM_ SG_ 2549088395 BCM2_KompSchutz "Funktionseinschränkung aufgrund Komponentenschutz aktiv";
CM_ SG_ 2549088395 BCM2_Abschaltstufe "Funktionseinschränkung aufgrund aktiver Abschaltstufe";
CM_ SG_ 2549088395 BCM2_Transport_Mode "Funktionseinschränkung aufgrund aktivem Transport Mode und/oder Transport Schutz";
CM_ SG_ 2549088395 BCM2_Nachlauftyp "Abgebildet wird die von der Hardware vorgegebene Möglichkeit, die Kommunikation nach Klemme 15 = AUS aufrecht zu erhalten. Es wird ein Init-Wert gesendet.
0 = Kommunikation nur bei KL15=EIN (kein Nachlauf, nicht weckfähig)
1 = Kommunikation nach KL15=AU";
CM_ SG_ 2549088395 BCM2_SNI "Das Signal beinhaltet den Source Node Identifier (Knotenadresse, die auch in der Abbildungsvorschrift zur CAN-ID für die NM-High Botschaft verwendet wird).";
CM_ SG_ 2549088395 NM_BCM2_Wakeup "enthält die Weckursache; stehen mehrere Weckursachen parallel an, dann muss der kleinste Wert übertragen werden";
CM_ SG_ 2549088395 NM_BCM2_Lokalaktiv "Zeigt an ob das SG nach Klemme15 AUS und nach entsprechender MAX Aktivzeit noch aktiv war";
CM_ SG_ 2549088395 NM_BCM2_Subsystemaktiv "Zeigt an ob ein Subsystem des SGs nach Klemme15 AUS und nach entsprechender MAX Aktivzeit noch aktiv war";
CM_ SG_ 2549088395 BCM2_KD_Fehler "Status Kundendienstfehlerspeichereinträge
";
CM_ SG_ 2549088305 ELV_KompSchutz "Funktionseinschränkung aufgrund Komponentenschutz aktiv";
CM_ SG_ 2549088305 ELV_Abschaltstufe "Funktionseinschränkung aufgrund aktiver Abschaltstufe";
CM_ SG_ 2549088305 ELV_Transport_Mode "Funktionseinschränkung aufgrund aktivem Transport Mode und/oder Transport Schutz";
CM_ SG_ 2549088305 ELV_Nachlauftyp "Abgebildet wird die von der Hardware vorgegebene Möglichkeit, die Kommunikation nach Klemme 15 = AUS aufrecht zu erhalten. Es wird ein Init-Wert gesendet.
0 = Kommunikation nur bei KL15=EIN (kein Nachlauf, nicht weckfähig)
1 = Kommunikation nach KL15=AU";
CM_ SG_ 2549088305 ELV_SNI "Das Signal beinhaltet den Source Node Identifier (Knotenadresse, die auch in der Abbildungsvorschrift zur CAN-ID für die NM-High Botschaft verwendet wird).";
CM_ SG_ 2549088305 NM_ELV_Wakeup "enthält die Weckursache; stehen mehrere Weckursachen parallel an, dann muss der kleinste Wert übertragen werden";
CM_ SG_ 2549088305 NM_ELV_Lokalaktiv "Zeigt an ob das SG nach Klemme15 AUS und nach entsprechender MAX Aktivzeit noch aktiv war";
CM_ SG_ 2549088305 NM_ELV_Subsystemaktiv "Zeigt an ob ein Subsystem des SGs nach Klemme15 AUS und nach entsprechender MAX Aktivzeit noch aktiv war";
CM_ SG_ 2549088305 ELV_KD_Fehler "Status Kundendienstfehlerspeichereinträge
";
CM_ SG_ 2549088272 Gateway_KompSchutz "Funktionseinschränkung aufgrund Komponentenschutz aktiv";
CM_ SG_ 2549088272 Gateway_Abschaltstufe "Funktionseinschränkung aufgrund aktiver Abschaltstufe";
CM_ SG_ 2549088272 Gateway_Transport_Mode "Funktionseinschränkung aufgrund aktivem Transport Mode und/oder Transport Schutz";
CM_ SG_ 2549088272 Gateway_Nachlauftyp "Abgebildet wird die von der Hardware vorgegebene Möglichkeit, die Kommunikation nach Klemme 15 = AUS aufrecht zu erhalten. Es wird ein Init-Wert gesendet.
0 = Kommunikation nur bei KL15=EIN (kein Nachlauf, nicht weckfähig)
1 = Kommunikation nach KL15=AU";
CM_ SG_ 2549088272 Gateway_SNI "Das Signal beinhaltet den Source Node Identifier (Knotenadresse, die auch in der Abbildungsvorschrift zur CAN-ID für die NM-High Botschaft verwendet wird).";
CM_ SG_ 2549088272 NM_Gateway_Wakeup "enthält die Weckursache; stehen mehrere Weckursachen parallel an, dann muss der kleinste Wert übertragen werden";
CM_ SG_ 2549088272 NM_Gateway_Lokalaktiv "Zeigt an ob das SG nach Klemme15 AUS und nach entsprechender MAX Aktivzeit noch aktiv war";
CM_ SG_ 2549088272 NM_Gateway_Subsystemaktiv "Zeigt an ob ein Subsystem des SGs nach Klemme15 AUS und nach entsprechender MAX Aktivzeit noch aktiv war";
CM_ SG_ 2549088272 GW_KD_Fehler "Kundendienstfehlerbit Gateway zur Anzeige eines im Gateway abgelegten Fehlerspeichereintrages.";
CM_ SG_ 2549088291 HDSG_KompSchutz "Funktionseinschränkung aufgrund Komponentenschutz aktiv";
CM_ SG_ 2549088291 HDSG_Abschaltstufe "Funktionseinschränkung aufgrund aktiver Abschaltstufe";
CM_ SG_ 2549088291 HDSG_Transport_Mode "Funktionseinschränkung aufgrund aktivem Transport Mode und/oder Transport Schutz";
CM_ SG_ 2549088291 HDSG_Nachlauftyp "Abgebildet wird die von der Hardware vorgegebene Möglichkeit, die Kommunikation nach Klemme 15 = AUS aufrecht zu erhalten. Es wird ein Init-Wert gesendet.
0 = Kommunikation nur bei KL15=EIN (kein Nachlauf, nicht weckfähig)
1 = Kommunikation nach KL15=AU";
CM_ SG_ 2549088291 HDSG_SNI "Das Signal beinhaltet den Source Node Identifier (Knotenadresse, die auch in der Abbildungsvorschrift zur CAN-ID für die NM-High Botschaft verwendet wird).";
CM_ SG_ 2549088291 NM_HDSG_Wakeup "enthält die Weckursache; stehen mehrere Weckursachen parallel an, dann muss der kleinste Wert übertragen werden";
CM_ SG_ 2549088291 KN_HDSG_WakePrevention "Ausgabe des WakePrevention-Status in der Knotenbotschaft";
CM_ SG_ 2549088291 NM_HDSG_Lokalaktiv "Zeigt an ob das SG nach Klemme15 AUS und nach entsprechender MAX Aktivzeit noch aktiv war";
CM_ SG_ 2549088291 NM_HDSG_Subsystemaktiv "Zeigt an ob ein Subsystem des SGs nach Klemme15 AUS und nach entsprechender MAX Aktivzeit noch aktiv war";
CM_ SG_ 2549088291 HD_KD_Fehler "Status Kundendienstfehlerspeichereinträge
";
CM_ SG_ 2549088306 Kessy_KompSchutz "Funktionseinschränkung aufgrund Komponentenschutz aktiv";
CM_ SG_ 2549088306 Kessy_Abschaltstufe "Funktionseinschränkung aufgrund aktiver Abschaltstufe";
CM_ SG_ 2549088306 Kessy_Transport_Mode "Funktionseinschränkung aufgrund aktivem Transport Mode und/oder Transport Schutz";
CM_ SG_ 2549088306 Kessy_Nachlauftyp "Abgebildet wird die von der Hardware vorgegebene Möglichkeit, die Kommunikation nach Klemme 15 = AUS aufrecht zu erhalten. Es wird ein Init-Wert gesendet.
0 = Kommunikation nur bei KL15=EIN (kein Nachlauf, nicht weckfähig)
1 = Kommunikation nach KL15=AU";
CM_ SG_ 2549088306 Kessy_SNI "Das Signal beinhaltet den Source Node Identifier (Knotenadresse, die auch in der Abbildungsvorschrift zur CAN-ID für die NM-High Botschaft verwendet wird).";
CM_ SG_ 2549088306 NM_Kessy_Wakeup "enthält die Weckursache; stehen mehrere Weckursachen parallel an, dann muss der kleinste Wert übertragen werden";
CM_ SG_ 2549088306 KN_Kessy_ECUKnockOut "Ausgabe des ECUKnockout-Status in der Knotenbotschaft";
CM_ SG_ 2549088306 KN_Kessy_WakePrevention "Ausgabe des WakePrevention-Status in der Knotenbotschaft";
CM_ SG_ 2549088306 NM_Kessy_Lokalaktiv "Zeigt an ob das SG nach Klemme15 AUS und nach entsprechender MAX Aktivzeit noch aktiv war
alt";
CM_ SG_ 2549088306 Kessy_KD_Fehler "Status Kundendienstfehlerspeichereinträge
";
BA_DEF_ BO_  "DiagRequest" ENUM  "No","Yes";
BA_DEF_ BO_  "DiagResponse" ENUM  "No","Yes";
BA_DEF_ BO_  "DiagState" ENUM  "No","Yes";
BA_DEF_ BO_  "GenMsgChkConstant" HEX 0 4095;
BA_DEF_ BO_  "GenMsgCycleTime" INT 0 65535;
BA_DEF_ BO_  "GenMsgCycleTimeFast" INT 0 65535;
BA_DEF_ BO_  "GenMsgDelayTime" INT 0 100000;
BA_DEF_ BO_  "GenMsgILSupport" ENUM  "No","Yes";
BA_DEF_ BO_  "GenMsgNrOfRepetition" INT 0 100;
BA_DEF_ BO_  "GenMsgPDUConstants" STRING ;
BA_DEF_ BO_  "GenMsgSendType" ENUM  "Cyclic","not_used","not_used","not_used","not_used","not_used","not_used","IfActive","NoMsgSendType";
BA_DEF_ BO_  "GenMsgStartDelayTime" INT 0 100000;
BA_DEF_ BO_  "NmMessage" ENUM  "No","Yes";
BA_DEF_ BO_  "NmhMessage" ENUM  "No","Yes";
BA_DEF_ BO_  "MsgType" ENUM  "Application","NM ","NMH","TP2.0","ISO-TP ","BAP","EID";
BA_DEF_ BO_  "VAGTP20_API" HEX 0 255;
BA_DEF_ BO_  "VAGTP20_DynConnection" ENUM  "No","Yes";
BA_DEF_ BO_  "VAGTP20_DynSetup" ENUM  "No","Yes";
BA_DEF_ BO_  "VAGTP20_StatConnection" ENUM  "No","Yes";
BA_DEF_ SG_  "GenSigActiveRepetitions" INT -2147483648 2147483647;
BA_DEF_ SG_  "GenSigInactiveValue" INT -2147483648 2147483647;
BA_DEF_ SG_  "GenSigSendType" ENUM  "Cyclic","OnWrite","OnWriteWithRepetition","OnChange","OnChangeWithRepetition","IfActive","IfActiveWithRepetition","NoSigSendType","OnChangeAndIfActive","OnChangeAndIfActiveWithRepetition";
BA_DEF_ SG_  "GenSigStartValue" INT -2147483648 2147483647;
BA_DEF_ SG_  "NWM-WakeupAllowed" ENUM  "No","Yes";
BA_DEF_ SG_  "GenSigFuncType" ENUM  "NoFunction","MsgCounter","CRC-8","XOR","XOR-2","DatedBit","SW-Kl15","CHK","Constant","Protocol","CRC-8-SAE_J1850";
BA_DEF_ SG_  "GenSigSwitchedByIgnition" ENUM  "No","Yes";
BA_DEF_ SG_  "Fehlerwert" HEX 0 2147483647;
BA_DEF_ SG_  "GenSigMissingSourceValue" HEX 0 2147483647;
BA_DEF_REL_ BU_SG_REL_  "GenSigTimeoutTime" INT 0 65535;
BA_DEF_DEF_  "DiagRequest" "No";
BA_DEF_DEF_  "DiagResponse" "No";
BA_DEF_DEF_  "DiagState" "No";
BA_DEF_DEF_  "GenMsgChkConstant" 0;
BA_DEF_DEF_  "GenMsgCycleTime" 0;
BA_DEF_DEF_  "GenMsgCycleTimeFast" 0;
BA_DEF_DEF_  "GenMsgDelayTime" 0;
BA_DEF_DEF_  "GenMsgILSupport" "No";
BA_DEF_DEF_  "GenMsgNrOfRepetition" 0;
BA_DEF_DEF_  "GenMsgPDUConstants" "";
BA_DEF_DEF_  "GenMsgSendType" "NoMsgSendType";
BA_DEF_DEF_  "GenMsgStartDelayTime" 0;
BA_DEF_DEF_  "NmMessage" "No";
BA_DEF_DEF_  "NmhMessage" "No";
BA_DEF_DEF_  "MsgType" "Application";
BA_DEF_DEF_  "VAGTP20_API" 0;
BA_DEF_DEF_  "VAGTP20_DynConnection" "No";
BA_DEF_DEF_  "VAGTP20_DynSetup" "No";
BA_DEF_DEF_  "VAGTP20_StatConnection" "No";
BA_DEF_DEF_  "GenSigActiveRepetitions" 0;
BA_DEF_DEF_  "GenSigInactiveValue" 0;
BA_DEF_DEF_  "GenSigSendType" "NoSigSendType";
BA_DEF_DEF_  "GenSigStartValue" 0;
BA_DEF_DEF_  "NWM-WakeupAllowed" "No";
BA_DEF_DEF_  "GenSigFuncType" "NoFunction";
BA_DEF_DEF_  "GenSigSwitchedByIgnition" "Yes";
BA_DEF_DEF_  "Fehlerwert" 0;
BA_DEF_DEF_  "GenSigMissingSourceValue" 0;
BA_DEF_DEF_REL_ "GenSigTimeoutTime" 0;
BA_ "GenMsgSendType" BO_ 1381 0;
BA_ "GenMsgILSupport" BO_ 1381 1;
BA_ "GenMsgDelayTime" BO_ 1381 50;
BA_ "GenMsgCycleTimeFast" BO_ 1381 100;
BA_ "GenMsgCycleTime" BO_ 1381 500;
BA_ "GenMsgSendType" BO_ 1340 0;
BA_ "GenMsgPDUConstants" BO_ 1340 "0x8e,0xf9,0xe1,0x2e,0x83,0x34,0xd0,0xf1,0xaa,0x2c,0xbb,0x81,0x17,0x60,0x11,0x37";
BA_ "GenMsgILSupport" BO_ 1340 1;
BA_ "GenMsgDelayTime" BO_ 1340 100;
BA_ "GenMsgCycleTime" BO_ 1340 1000;
BA_ "GenMsgSendType" BO_ 371 0;
BA_ "GenMsgPDUConstants" BO_ 371 "0x9d,0xe8,0x36,0xa1,0xca,0x3b,0x1d,0x33,0xe0,0xd5,0xbb,0x5f,0xae,0x3c,0x31,0x9f";
BA_ "GenMsgNrOfRepetition" BO_ 371 10;
BA_ "GenMsgILSupport" BO_ 371 1;
BA_ "GenMsgDelayTime" BO_ 371 10;
BA_ "GenMsgCycleTimeFast" BO_ 371 20;
BA_ "GenMsgCycleTime" BO_ 371 500;
BA_ "GenMsgSendType" BO_ 1524 0;
BA_ "GenMsgILSupport" BO_ 1524 1;
BA_ "GenMsgDelayTime" BO_ 1524 50;
BA_ "GenMsgCycleTime" BO_ 1524 500;
BA_ "GenMsgSendType" BO_ 312 0;
BA_ "GenMsgPDUConstants" BO_ 312 "0x77,0x4e,0x14,0x87,0xf2,0xf8,0xb2,0x61,0xf6,0xa4,0x52,0x94,0xd4,0x81,0x2a,0xb1";
BA_ "GenMsgILSupport" BO_ 312 1;
BA_ "GenMsgDelayTime" BO_ 312 20;
BA_ "GenMsgCycleTime" BO_ 312 200;
BA_ "MsgType" BO_ 1863 4;
BA_ "DiagRequest" BO_ 1863 1;
BA_ "MsgType" BO_ 1969 4;
BA_ "DiagResponse" BO_ 1969 1;
BA_ "MsgType" BO_ 1806 4;
BA_ "DiagRequest" BO_ 1806 1;
BA_ "MsgType" BO_ 1912 4;
BA_ "DiagResponse" BO_ 1912 1;
BA_ "MsgType" BO_ 1841 4;
BA_ "DiagRequest" BO_ 1841 1;
BA_ "MsgType" BO_ 1947 4;
BA_ "DiagResponse" BO_ 1947 1;
BA_ "MsgType" BO_ 1792 4;
BA_ "DiagState" BO_ 1792 1;
BA_ "MsgType" BO_ 1827 4;
BA_ "DiagRequest" BO_ 1827 1;
BA_ "MsgType" BO_ 1933 4;
BA_ "DiagResponse" BO_ 1933 1;
BA_ "MsgType" BO_ 1842 4;
BA_ "DiagRequest" BO_ 1842 1;
BA_ "MsgType" BO_ 1948 4;
BA_ "DiagResponse" BO_ 1948 1;
BA_ "MsgType" BO_ 1836 4;
BA_ "DiagRequest" BO_ 1836 1;
BA_ "MsgType" BO_ 1942 4;
BA_ "DiagResponse" BO_ 1942 1;
BA_ "MsgType" BO_ 2549350921 4;
BA_ "MsgType" BO_ 2549483778 4;
BA_ "MsgType" BO_ 2549350923 4;
BA_ "MsgType" BO_ 2549484290 4;
BA_ "MsgType" BO_ 1869 4;
BA_ "DiagRequest" BO_ 1869 1;
BA_ "MsgType" BO_ 1975 4;
BA_ "DiagResponse" BO_ 1975 1;
BA_ "MsgType" BO_ 1868 4;
BA_ "DiagRequest" BO_ 1868 1;
BA_ "MsgType" BO_ 1974 4;
BA_ "DiagResponse" BO_ 1974 1;
BA_ "MsgType" BO_ 2549352706 4;
BA_ "MsgType" BO_ 2549481993 4;
BA_ "MsgType" BO_ 1828 4;
BA_ "DiagRequest" BO_ 1828 1;
BA_ "MsgType" BO_ 1934 4;
BA_ "DiagResponse" BO_ 1934 1;
BA_ "MsgType" BO_ 1835 4;
BA_ "DiagRequest" BO_ 1835 1;
BA_ "MsgType" BO_ 1941 4;
BA_ "DiagResponse" BO_ 1941 1;
BA_ "MsgType" BO_ 1867 4;
BA_ "DiagRequest" BO_ 1867 1;
BA_ "MsgType" BO_ 1973 4;
BA_ "DiagResponse" BO_ 1973 1;
BA_ "MsgType" BO_ 1866 4;
BA_ "DiagRequest" BO_ 1866 1;
BA_ "MsgType" BO_ 1972 4;
BA_ "DiagResponse" BO_ 1972 1;
BA_ "MsgType" BO_ 1855 4;
BA_ "DiagRequest" BO_ 1855 1;
BA_ "MsgType" BO_ 1961 4;
BA_ "DiagResponse" BO_ 1961 1;
BA_ "MsgType" BO_ 1854 4;
BA_ "DiagRequest" BO_ 1854 1;
BA_ "MsgType" BO_ 1960 4;
BA_ "DiagResponse" BO_ 1960 1;
BA_ "MsgType" BO_ 1837 4;
BA_ "DiagRequest" BO_ 1837 1;
BA_ "MsgType" BO_ 1943 4;
BA_ "DiagResponse" BO_ 1943 1;
BA_ "MsgType" BO_ 2549353218 4;
BA_ "MsgType" BO_ 2549481995 4;
BA_ "MsgType" BO_ 2549874827 4;
BA_ "DiagRequest" BO_ 2549874827 1;
BA_ "MsgType" BO_ 2550005899 4;
BA_ "DiagResponse" BO_ 2550005899 1;
BA_ "MsgType" BO_ 2549874818 4;
BA_ "DiagRequest" BO_ 2549874818 1;
BA_ "MsgType" BO_ 2550005890 4;
BA_ "DiagResponse" BO_ 2550005890 1;
BA_ "MsgType" BO_ 2549874819 4;
BA_ "DiagRequest" BO_ 2549874819 1;
BA_ "MsgType" BO_ 2550005891 4;
BA_ "DiagResponse" BO_ 2550005891 1;
BA_ "MsgType" BO_ 2549874838 4;
BA_ "DiagRequest" BO_ 2549874838 1;
BA_ "MsgType" BO_ 2550005910 4;
BA_ "DiagResponse" BO_ 2550005910 1;
BA_ "MsgType" BO_ 2549874839 4;
BA_ "DiagRequest" BO_ 2549874839 1;
BA_ "MsgType" BO_ 2550005911 4;
BA_ "DiagResponse" BO_ 2550005911 1;
BA_ "MsgType" BO_ 2549874848 4;
BA_ "DiagRequest" BO_ 2549874848 1;
BA_ "MsgType" BO_ 2550005920 4;
BA_ "DiagResponse" BO_ 2550005920 1;
BA_ "MsgType" BO_ 2549874820 4;
BA_ "DiagRequest" BO_ 2549874820 1;
BA_ "MsgType" BO_ 2550005892 4;
BA_ "DiagResponse" BO_ 2550005892 1;
BA_ "MsgType" BO_ 2549874843 4;
BA_ "DiagRequest" BO_ 2549874843 1;
BA_ "MsgType" BO_ 2550005915 4;
BA_ "DiagResponse" BO_ 2550005915 1;
BA_ "MsgType" BO_ 2549874824 4;
BA_ "DiagRequest" BO_ 2549874824 1;
BA_ "MsgType" BO_ 2550005896 4;
BA_ "DiagResponse" BO_ 2550005896 1;
BA_ "MsgType" BO_ 2549874823 4;
BA_ "DiagRequest" BO_ 2549874823 1;
BA_ "MsgType" BO_ 2550005895 4;
BA_ "DiagResponse" BO_ 2550005895 1;
BA_ "MsgType" BO_ 2549874837 4;
BA_ "DiagRequest" BO_ 2549874837 1;
BA_ "MsgType" BO_ 2550005909 4;
BA_ "DiagResponse" BO_ 2550005909 1;
BA_ "GenMsgSendType" BO_ 497 0;
BA_ "GenMsgNrOfRepetition" BO_ 497 7;
BA_ "GenMsgILSupport" BO_ 497 1;
BA_ "GenMsgDelayTime" BO_ 497 20;
BA_ "GenMsgCycleTimeFast" BO_ 497 40;
BA_ "GenMsgCycleTime" BO_ 497 500;
BA_ "GenMsgSendType" BO_ 1424 0;
BA_ "GenMsgILSupport" BO_ 1424 1;
BA_ "GenMsgDelayTime" BO_ 1424 50;
BA_ "GenMsgCycleTime" BO_ 1424 200;
BA_ "GenMsgSendType" BO_ 960 0;
BA_ "GenMsgPDUConstants" BO_ 960 "0xc3,0xc3,0xc3,0xc3,0xc3,0xc3,0xc3,0xc3,0xc3,0xc3,0xc3,0xc3,0xc3,0xc3,0xc3,0xc3";
BA_ "GenMsgILSupport" BO_ 960 1;
BA_ "GenMsgDelayTime" BO_ 960 10;
BA_ "GenMsgCycleTime" BO_ 960 100;
BA_ "GenMsgChkConstant" BO_ 960 195;
BA_ "GenMsgSendType" BO_ 1420 0;
BA_ "GenMsgPDUConstants" BO_ 1420 "0x9b,0xb5,0x9d,0x06,0x01,0xe7,0x8f,0xc1,0xd0,0x10,0x47,0xe9,0xd3,0xca,0x05,0xf0";
BA_ "GenMsgNrOfRepetition" BO_ 1420 3;
BA_ "GenMsgILSupport" BO_ 1420 1;
BA_ "GenMsgDelayTime" BO_ 1420 50;
BA_ "GenMsgCycleTimeFast" BO_ 1420 100;
BA_ "GenMsgCycleTime" BO_ 1420 1000;
BA_ "GenMsgSendType" BO_ 1646 0;
BA_ "GenMsgILSupport" BO_ 1646 1;
BA_ "GenMsgDelayTime" BO_ 1646 200;
BA_ "GenMsgCycleTime" BO_ 1646 2000;
BA_ "GenMsgSendType" BO_ 949 0;
BA_ "GenMsgILSupport" BO_ 949 1;
BA_ "GenMsgCycleTime" BO_ 949 100;
BA_ "GenMsgSendType" BO_ 1640 0;
BA_ "GenMsgNrOfRepetition" BO_ 1640 5;
BA_ "GenMsgILSupport" BO_ 1640 1;
BA_ "GenMsgDelayTime" BO_ 1640 50;
BA_ "GenMsgCycleTimeFast" BO_ 1640 100;
BA_ "GenMsgCycleTime" BO_ 1640 200;
BA_ "GenMsgSendType" BO_ 1441 0;
BA_ "GenMsgILSupport" BO_ 1441 1;
BA_ "GenMsgCycleTime" BO_ 1441 500;
BA_ "GenMsgSendType" BO_ 992 0;
BA_ "GenMsgILSupport" BO_ 992 1;
BA_ "GenMsgCycleTime" BO_ 992 100;
BA_ "GenMsgSendType" BO_ 1712 0;
BA_ "GenMsgILSupport" BO_ 1712 1;
BA_ "GenMsgCycleTime" BO_ 1712 500;
BA_ "GenMsgSendType" BO_ 1505 0;
BA_ "GenMsgILSupport" BO_ 1505 1;
BA_ "GenMsgCycleTime" BO_ 1505 200;
BA_ "GenMsgSendType" BO_ 2549088327 0;
BA_ "GenMsgILSupport" BO_ 2549088327 1;
BA_ "GenMsgCycleTime" BO_ 2549088327 500;
BA_ "GenMsgSendType" BO_ 2549088270 0;
BA_ "GenMsgILSupport" BO_ 2549088270 1;
BA_ "GenMsgCycleTime" BO_ 2549088270 500;
BA_ "GenMsgSendType" BO_ 2549088395 0;
BA_ "GenMsgILSupport" BO_ 2549088395 1;
BA_ "GenMsgCycleTime" BO_ 2549088395 500;
BA_ "GenMsgSendType" BO_ 2549088305 0;
BA_ "GenMsgILSupport" BO_ 2549088305 1;
BA_ "GenMsgCycleTime" BO_ 2549088305 500;
BA_ "GenMsgSendType" BO_ 2549088272 0;
BA_ "GenMsgILSupport" BO_ 2549088272 1;
BA_ "GenMsgCycleTime" BO_ 2549088272 500;
BA_ "GenMsgSendType" BO_ 2549088291 0;
BA_ "GenMsgILSupport" BO_ 2549088291 1;
BA_ "GenMsgCycleTime" BO_ 2549088291 500;
BA_ "GenMsgSendType" BO_ 2549088306 0;
BA_ "GenMsgILSupport" BO_ 2549088306 1;
BA_ "GenMsgCycleTime" BO_ 2549088306 500;
BA_ "Fehlerwert" SG_ 1381 HVLM_HV_Abstellzeit 255;
BA_ "GenSigSwitchedByIgnition" SG_ 1381 HVLM_HV_Abstellzeit 0;
BA_ "GenSigStartValue" SG_ 1381 HVLM_HV_Abstellzeit 254;
BA_ "GenSigSendType" SG_ 1381 HVLM_HV_Abstellzeit 0;
BA_ "GenSigSwitchedByIgnition" SG_ 1381 HVLM_Ladesystemhinweise 0;
BA_ "GenSigSendType" SG_ 1381 HVLM_Ladesystemhinweise 0;
BA_ "Fehlerwert" SG_ 1381 HVLM_Zustand_LED 15;
BA_ "GenSigSwitchedByIgnition" SG_ 1381 HVLM_Zustand_LED 0;
BA_ "GenSigStartValue" SG_ 1381 HVLM_Zustand_LED 14;
BA_ "GenSigSendType" SG_ 1381 HVLM_Zustand_LED 3;
BA_ "Fehlerwert" SG_ 1381 HVLM_MaxLadezeitDCHV 255;
BA_ "GenSigSwitchedByIgnition" SG_ 1381 HVLM_MaxLadezeitDCHV 0;
BA_ "GenSigStartValue" SG_ 1381 HVLM_MaxLadezeitDCHV 254;
BA_ "GenSigSendType" SG_ 1381 HVLM_MaxLadezeitDCHV 3;
BA_ "Fehlerwert" SG_ 1381 HVLM_MaxStrom_Netz 127;
BA_ "GenSigSwitchedByIgnition" SG_ 1381 HVLM_MaxStrom_Netz 0;
BA_ "GenSigStartValue" SG_ 1381 HVLM_MaxStrom_Netz 126;
BA_ "GenSigSendType" SG_ 1381 HVLM_MaxStrom_Netz 3;
BA_ "GenSigSwitchedByIgnition" SG_ 1381 HVLM_LG_Sollmodus 0;
BA_ "GenSigSendType" SG_ 1381 HVLM_LG_Sollmodus 3;
BA_ "Fehlerwert" SG_ 1381 HVLM_FreigabeTankdeckel 3;
BA_ "GenSigSwitchedByIgnition" SG_ 1381 HVLM_FreigabeTankdeckel 0;
BA_ "GenSigStartValue" SG_ 1381 HVLM_FreigabeTankdeckel 2;
BA_ "GenSigSendType" SG_ 1381 HVLM_FreigabeTankdeckel 3;
BA_ "GenSigSwitchedByIgnition" SG_ 1381 HVLM_Stecker_Verriegeln 0;
BA_ "GenSigStartValue" SG_ 1381 HVLM_Stecker_Verriegeln 2;
BA_ "GenSigSendType" SG_ 1381 HVLM_Stecker_Verriegeln 3;
BA_ "GenSigSwitchedByIgnition" SG_ 1381 HVLM_Start_Spannungsmessung_DCLS 0;
BA_ "GenSigSendType" SG_ 1381 HVLM_Start_Spannungsmessung_DCLS 3;
BA_ "Fehlerwert" SG_ 1381 HVLM_Taster_Profil_Laden_Anf 3;
BA_ "GenSigSwitchedByIgnition" SG_ 1381 HVLM_Taster_Profil_Laden_Anf 0;
BA_ "GenSigStartValue" SG_ 1381 HVLM_Taster_Profil_Laden_Anf 2;
BA_ "GenSigSendType" SG_ 1381 HVLM_Taster_Profil_Laden_Anf 3;
BA_ "Fehlerwert" SG_ 1381 HVLM_Taster_Sofort_Laden_Anf 3;
BA_ "GenSigSwitchedByIgnition" SG_ 1381 HVLM_Taster_Sofort_Laden_Anf 0;
BA_ "GenSigStartValue" SG_ 1381 HVLM_Taster_Sofort_Laden_Anf 2;
BA_ "GenSigSendType" SG_ 1381 HVLM_Taster_Sofort_Laden_Anf 3;
BA_ "Fehlerwert" SG_ 1381 HVLM_FreigabeKlimatisierung 3;
BA_ "GenSigSwitchedByIgnition" SG_ 1381 HVLM_FreigabeKlimatisierung 0;
BA_ "GenSigStartValue" SG_ 1381 HVLM_FreigabeKlimatisierung 2;
BA_ "GenSigSendType" SG_ 1381 HVLM_FreigabeKlimatisierung 0;
BA_ "GenSigSwitchedByIgnition" SG_ 1381 HVLM_Ladetexte 0;
BA_ "GenSigSendType" SG_ 1381 HVLM_Ladetexte 3;
BA_ "Fehlerwert" SG_ 1381 HVLM_IstSpannung_HV 1023;
BA_ "GenSigSwitchedByIgnition" SG_ 1381 HVLM_IstSpannung_HV 0;
BA_ "GenSigStartValue" SG_ 1381 HVLM_IstSpannung_HV 1022;
BA_ "GenSigSendType" SG_ 1381 HVLM_IstSpannung_HV 5;
BA_ "GenSigInactiveValue" SG_ 1381 HVLM_IstSpannung_HV 1022;
BA_ "GenSigSwitchedByIgnition" SG_ 1340 HVLM_04_CRC 0;
BA_ "GenSigFuncType" SG_ 1340 HVLM_04_CRC 2;
BA_ "GenSigSendType" SG_ 1340 HVLM_04_CRC 0;
BA_ "GenSigSwitchedByIgnition" SG_ 1340 HVLM_04_BZ 0;
BA_ "GenSigFuncType" SG_ 1340 HVLM_04_BZ 1;
BA_ "GenSigSendType" SG_ 1340 HVLM_04_BZ 0;
BA_ "Fehlerwert" SG_ 1340 HVLM_STH_Betriebsmodus 7;
BA_ "GenSigSwitchedByIgnition" SG_ 1340 HVLM_STH_Betriebsmodus 0;
BA_ "GenSigStartValue" SG_ 1340 HVLM_STH_Betriebsmodus 6;
BA_ "GenSigSendType" SG_ 1340 HVLM_STH_Betriebsmodus 0;
BA_ "GenSigSwitchedByIgnition" SG_ 1340 HVLM_Standklima_Timer_Status 0;
BA_ "GenSigSendType" SG_ 1340 HVLM_Standklima_Timer_Status 3;
BA_ "Fehlerwert" SG_ 1340 HVLM_HVEM_MaxLeistung 511;
BA_ "GenSigSwitchedByIgnition" SG_ 1340 HVLM_HVEM_MaxLeistung 0;
BA_ "GenSigStartValue" SG_ 1340 HVLM_HVEM_MaxLeistung 510;
BA_ "GenSigSendType" SG_ 1340 HVLM_HVEM_MaxLeistung 0;
BA_ "GenSigSwitchedByIgnition" SG_ 1340 HVLM_Status_Netz 0;
BA_ "GenSigSendType" SG_ 1340 HVLM_Status_Netz 0;
BA_ "GenSigSwitchedByIgnition" SG_ 1340 HVLM_Ladeart 0;
BA_ "GenSigSendType" SG_ 1340 HVLM_Ladeart 3;
BA_ "Fehlerwert" SG_ 1340 HVLM_VK_STH_Einsatz 7;
BA_ "GenSigSwitchedByIgnition" SG_ 1340 HVLM_VK_STH_Einsatz 0;
BA_ "GenSigStartValue" SG_ 1340 HVLM_VK_STH_Einsatz 6;
BA_ "GenSigSendType" SG_ 1340 HVLM_VK_STH_Einsatz 0;
BA_ "Fehlerwert" SG_ 1340 HVLM_VK_Modus 3;
BA_ "GenSigSwitchedByIgnition" SG_ 1340 HVLM_VK_Modus 0;
BA_ "GenSigSendType" SG_ 1340 HVLM_VK_Modus 0;
BA_ "Fehlerwert" SG_ 1340 HVLM_IstModus_02 3;
BA_ "GenSigSwitchedByIgnition" SG_ 1340 HVLM_IstModus_02 0;
BA_ "GenSigStartValue" SG_ 1340 HVLM_IstModus_02 2;
BA_ "GenSigSendType" SG_ 1340 HVLM_IstModus_02 3;
BA_ "GenSigSwitchedByIgnition" SG_ 1340 HVLM_HV_Anf 0;
BA_ "GenSigSendType" SG_ 1340 HVLM_HV_Anf 3;
BA_ "GenSigSwitchedByIgnition" SG_ 1340 HVLM_Fehlerstatus 0;
BA_ "GenSigStartValue" SG_ 1340 HVLM_Fehlerstatus 7;
BA_ "GenSigSendType" SG_ 1340 HVLM_Fehlerstatus 3;
BA_ "GenSigSwitchedByIgnition" SG_ 1340 HVLM_Anforderung_HMS 0;
BA_ "GenSigSendType" SG_ 1340 HVLM_Anforderung_HMS 3;
BA_ "Fehlerwert" SG_ 1340 HVLM_Parken_beibehalten_HMS 3;
BA_ "GenSigSwitchedByIgnition" SG_ 1340 HVLM_Parken_beibehalten_HMS 0;
BA_ "GenSigStartValue" SG_ 1340 HVLM_Parken_beibehalten_HMS 2;
BA_ "GenSigSendType" SG_ 1340 HVLM_Parken_beibehalten_HMS 3;
BA_ "Fehlerwert" SG_ 1340 HVLM_Dauer_Klima 31;
BA_ "GenSigSwitchedByIgnition" SG_ 1340 HVLM_Dauer_Klima 0;
BA_ "GenSigSendType" SG_ 1340 HVLM_Dauer_Klima 0;
BA_ "GenSigSwitchedByIgnition" SG_ 1340 HVLM_Stecker_Status 0;
BA_ "GenSigSendType" SG_ 1340 HVLM_Stecker_Status 3;
BA_ "Fehlerwert" SG_ 1340 HVLM_LadeAnforderung 7;
BA_ "GenSigSwitchedByIgnition" SG_ 1340 HVLM_LadeAnforderung 0;
BA_ "GenSigStartValue" SG_ 1340 HVLM_LadeAnforderung 6;
BA_ "GenSigSendType" SG_ 1340 HVLM_LadeAnforderung 3;
BA_ "Fehlerwert" SG_ 1340 HVLM_MaxBatLadestromHV 255;
BA_ "GenSigSwitchedByIgnition" SG_ 1340 HVLM_MaxBatLadestromHV 0;
BA_ "GenSigStartValue" SG_ 1340 HVLM_MaxBatLadestromHV 254;
BA_ "GenSigSendType" SG_ 1340 HVLM_MaxBatLadestromHV 3;
BA_ "GenSigSwitchedByIgnition" SG_ 371 IEZS_01_CRC 0;
BA_ "GenSigFuncType" SG_ 371 IEZS_01_CRC 2;
BA_ "GenSigSendType" SG_ 371 IEZS_01_CRC 4;
BA_ "GenSigSwitchedByIgnition" SG_ 371 IEZS_01_BZ 0;
BA_ "GenSigFuncType" SG_ 371 IEZS_01_BZ 1;
BA_ "GenSigSendType" SG_ 371 IEZS_01_BZ 4;
BA_ "GenSigSwitchedByIgnition" SG_ 371 IEZS_Anf_KL15 0;
BA_ "GenSigSendType" SG_ 371 IEZS_Anf_KL15 4;
BA_ "GenSigSwitchedByIgnition" SG_ 371 IEZS_Anf_KL50 0;
BA_ "GenSigSendType" SG_ 371 IEZS_Anf_KL50 4;
BA_ "GenSigSwitchedByIgnition" SG_ 371 IEZS_Anf_Klemmen_Aus 0;
BA_ "GenSigSendType" SG_ 371 IEZS_Anf_Klemmen_Aus 4;
BA_ "GenSigSwitchedByIgnition" SG_ 371 IEZS_AnfLeitung_KL15_Fehler 0;
BA_ "GenSigSendType" SG_ 371 IEZS_AnfLeitung_KL15_Fehler 4;
BA_ "GenSigSwitchedByIgnition" SG_ 371 IEZS_AnfLeitung_KL50_Fehler 0;
BA_ "GenSigSendType" SG_ 371 IEZS_AnfLeitung_KL50_Fehler 4;
BA_ "GenSigSwitchedByIgnition" SG_ 371 IEZS_F_Zuendanlassschalter_1 0;
BA_ "GenSigSendType" SG_ 371 IEZS_F_Zuendanlassschalter_1 4;
BA_ "GenSigSwitchedByIgnition" SG_ 371 IEZS_F_Zuendanlassschalter_2 0;
BA_ "GenSigSendType" SG_ 371 IEZS_F_Zuendanlassschalter_2 4;
BA_ "GenSigSwitchedByIgnition" SG_ 371 IEZS_Init_KlemmenAnf 0;
BA_ "GenSigSendType" SG_ 371 IEZS_Init_KlemmenAnf 4;
BA_ "GenSigSwitchedByIgnition" SG_ 371 IEZS_Noteinspeisung_erkannt 0;
BA_ "GenSigSendType" SG_ 371 IEZS_Noteinspeisung_erkannt 4;
BA_ "GenSigSwitchedByIgnition" SG_ 371 IEZS_T_Deckel_Vorne 0;
BA_ "GenSigSendType" SG_ 371 IEZS_T_Deckel_Vorne 4;
BA_ "GenSigSwitchedByIgnition" SG_ 371 IEZS_T_Deckel_Vorne_Fehler 0;
BA_ "GenSigSendType" SG_ 371 IEZS_T_Deckel_Vorne_Fehler 4;
BA_ "GenSigSwitchedByIgnition" SG_ 371 IEZS_TrunkEntrapment_Fehler 0;
BA_ "GenSigSendType" SG_ 371 IEZS_TrunkEntrapment_Fehler 4;
BA_ "GenSigSendType" SG_ 17 IMMO_Auth_Master_Slave01_Sig 1;
BA_ "GenSigSendType" SG_ 19 IMMO_Auth_Master_Slave02_Sig 1;
BA_ "GenSigSendType" SG_ 21 IMMO_Auth_Master_Slave03_Sig 1;
BA_ "GenSigSendType" SG_ 23 IMMO_Auth_Master_Slave04_Sig 1;
BA_ "GenSigSendType" SG_ 25 IMMO_Auth_Master_Slave05_Sig 1;
BA_ "GenSigSendType" SG_ 27 IMMO_Auth_Master_Slave06_Sig 1;
BA_ "GenSigSwitchedByIgnition" SG_ 29 IMMO_Auth_Master_Slave07_Sig1 0;
BA_ "GenSigSendType" SG_ 29 IMMO_Auth_Master_Slave07_Sig1 1;
BA_ "GenSigSwitchedByIgnition" SG_ 31 IMMO_Auth_Master_Slave08_Sig 0;
BA_ "GenSigSendType" SG_ 31 IMMO_Auth_Master_Slave08_Sig 1;
BA_ "GenSigSendType" SG_ 16 IMMO_Auth_Slave01_Master_Sig 1;
BA_ "GenSigSendType" SG_ 18 IMMO_Auth_Slave02_Master_Sig 1;
BA_ "GenSigSendType" SG_ 20 IMMO_Auth_Slave03_Master_Sig 1;
BA_ "GenSigSendType" SG_ 22 IMMO_Auth_Slave04_Master_Sig 1;
BA_ "GenSigSendType" SG_ 24 IMMO_Auth_Slave05_Master_Sig 1;
BA_ "GenSigSendType" SG_ 26 IMMO_Auth_Slave06_Master_Sig 1;
BA_ "GenSigSwitchedByIgnition" SG_ 28 IMMO_Auth_Slave07_Master_Sig1 0;
BA_ "GenSigSendType" SG_ 28 IMMO_Auth_Slave07_Master_Sig1 1;
BA_ "GenSigSwitchedByIgnition" SG_ 30 IMMO_Auth_Slave08_Master_Sig 0;
BA_ "GenSigSendType" SG_ 30 IMMO_Auth_Slave08_Master_Sig 1;
BA_ "GenSigSwitchedByIgnition" SG_ 268 ImoCord_Auth_Aufforderung_WFS 0;
BA_ "GenSigSendType" SG_ 268 ImoCord_Auth_Aufforderung_WFS 1;
BA_ "GenSigSwitchedByIgnition" SG_ 1524 IL_Dimmung_V_Tuerkontur 0;
BA_ "GenSigSendType" SG_ 1524 IL_Dimmung_V_Tuerkontur 3;
BA_ "GenSigSwitchedByIgnition" SG_ 1524 IL_Dimmung_H_Tuerkontur 0;
BA_ "GenSigSendType" SG_ 1524 IL_Dimmung_H_Tuerkontur 3;
BA_ "GenSigSwitchedByIgnition" SG_ 1524 IL_Dimmung_Tuerinnengriff 0;
BA_ "GenSigSendType" SG_ 1524 IL_Dimmung_Tuerinnengriff 3;
BA_ "GenSigSwitchedByIgnition" SG_ 1524 IL_Dimmung_Umfeldbel 0;
BA_ "GenSigSendType" SG_ 1524 IL_Dimmung_Umfeldbel 3;
BA_ "GenSigSwitchedByIgnition" SG_ 1524 IL_Bel_FS_Ausstieg 0;
BA_ "GenSigSendType" SG_ 1524 IL_Bel_FS_Ausstieg 3;
BA_ "GenSigSwitchedByIgnition" SG_ 1524 IL_Bel_BFS_Ausstieg 0;
BA_ "GenSigSendType" SG_ 1524 IL_Bel_BFS_Ausstieg 3;
BA_ "GenSigSwitchedByIgnition" SG_ 1524 IL_Bel_HFS_Ausstieg 0;
BA_ "GenSigSendType" SG_ 1524 IL_Bel_HFS_Ausstieg 3;
BA_ "GenSigSwitchedByIgnition" SG_ 1524 IL_Bel_HBFS_Ausstieg 0;
BA_ "GenSigSendType" SG_ 1524 IL_Bel_HBFS_Ausstieg 3;
BA_ "GenSigSwitchedByIgnition" SG_ 1524 BCM1_Innenlicht_gedimmt_V 0;
BA_ "GenSigSendType" SG_ 1524 BCM1_Innenlicht_gedimmt_V 3;
BA_ "GenSigSwitchedByIgnition" SG_ 1524 BCM1_Innenlicht_gedimmt_H 0;
BA_ "GenSigSendType" SG_ 1524 BCM1_Innenlicht_gedimmt_H 3;
BA_ "GenSigSwitchedByIgnition" SG_ 1524 IL_Innenlicht_aktiv 0;
BA_ "GenSigStartValue" SG_ 1524 IL_Innenlicht_aktiv 1;
BA_ "GenSigSendType" SG_ 1524 IL_Innenlicht_aktiv 3;
BA_ "GenSigSwitchedByIgnition" SG_ 1524 IL_Klemme_30G_aktiv 0;
BA_ "GenSigSendType" SG_ 1524 IL_Klemme_30G_aktiv 3;
BA_ "GenSigSwitchedByIgnition" SG_ 1524 BCM1_DI_Rampe_Innenlicht 0;
BA_ "GenSigSendType" SG_ 1524 BCM1_DI_Rampe_Innenlicht 3;
BA_ "GenSigSwitchedByIgnition" SG_ 1524 BCM1_DI_Rampe_Leselicht 0;
BA_ "GenSigSendType" SG_ 1524 BCM1_DI_Rampe_Leselicht 3;
BA_ "GenSigSwitchedByIgnition" SG_ 1524 BCM1_Innenlicht_H 0;
BA_ "GenSigSendType" SG_ 1524 BCM1_Innenlicht_H 3;
BA_ "GenSigSwitchedByIgnition" SG_ 1524 BCM1_Innenlicht_V 0;
BA_ "GenSigSendType" SG_ 1524 BCM1_Innenlicht_V 3;
BA_ "GenSigSwitchedByIgnition" SG_ 1524 BCM1_Leselicht_Anf_hl 0;
BA_ "GenSigSendType" SG_ 1524 BCM1_Leselicht_Anf_hl 3;
BA_ "GenSigSwitchedByIgnition" SG_ 1524 BCM1_Leselicht_Anf_hr 0;
BA_ "GenSigSendType" SG_ 1524 BCM1_Leselicht_Anf_hr 3;
BA_ "GenSigSwitchedByIgnition" SG_ 1524 BCM1_Leselicht_Anf_vl 0;
BA_ "GenSigSendType" SG_ 1524 BCM1_Leselicht_Anf_vl 3;
BA_ "GenSigSwitchedByIgnition" SG_ 1524 BCM1_Leselicht_Anf_vr 0;
BA_ "GenSigSendType" SG_ 1524 BCM1_Leselicht_Anf_vr 3;
BA_ "GenSigSwitchedByIgnition" SG_ 1524 BCM1_Leuchten_Aus 0;
BA_ "GenSigSendType" SG_ 1524 BCM1_Leuchten_Aus 3;
BA_ "GenSigSwitchedByIgnition" SG_ 1524 AMB_Charisma_FahrPr 0;
BA_ "GenSigSendType" SG_ 1524 AMB_Charisma_FahrPr 3;
BA_ "GenSigSwitchedByIgnition" SG_ 1524 AMB_Charisma_Status 0;
BA_ "GenSigSendType" SG_ 1524 AMB_Charisma_Status 3;
BA_ "GenSigSwitchedByIgnition" SG_ 1524 IL_Dimmung_Lautspr 0;
BA_ "GenSigSendType" SG_ 1524 IL_Dimmung_Lautspr 3;
BA_ "GenSigFuncType" SG_ 312 IPA_01_CRC 2;
BA_ "GenSigSendType" SG_ 312 IPA_01_CRC 0;
BA_ "GenSigFuncType" SG_ 312 IPA_01_BZ 1;
BA_ "GenSigSendType" SG_ 312 IPA_01_BZ 0;
BA_ "GenSigSendType" SG_ 312 IPA_Anforderung_HMS 0;
BA_ "GenSigSwitchedByIgnition" SG_ 312 IPA_Fahrtaster_LED 0;
BA_ "GenSigSendType" SG_ 312 IPA_Fahrtaster_LED 3;
BA_ "GenSigSendType" SG_ 312 IPA_Fahrstufenwunsch 0;
BA_ "GenSigSendType" SG_ 312 IPA_TSK_zul_Regelabw 0;
BA_ "GenSigStartValue" SG_ 312 IPA_Status_IPA_GE 1;
BA_ "GenSigSendType" SG_ 312 IPA_Status_IPA_GE 0;
BA_ "GenSigStartValue" SG_ 312 IPA_Status_IPA_TSK 1;
BA_ "GenSigSendType" SG_ 312 IPA_Status_IPA_TSK 0;
BA_ "GenSigSendType" SG_ 312 IPA_Sollbeschleunigung 0;
BA_ "GenSigStartValue" SG_ 312 IPA_PLA_LED 6;
BA_ "GenSigSendType" SG_ 312 IPA_PLA_LED 3;
BA_ "GenSigStartValue" SG_ 312 IPA_APS_LED 6;
BA_ "GenSigSendType" SG_ 312 IPA_APS_LED 3;
BA_ "GenSigSwitchedByIgnition" SG_ 1863 ISO_AAG_Req_Data 0;
BA_ "GenSigFuncType" SG_ 1863 ISO_AAG_Req_Data 9;
BA_ "GenSigSendType" SG_ 1863 ISO_AAG_Req_Data 3;
BA_ "GenSigSwitchedByIgnition" SG_ 1969 ISO_AAG_Resp_Data 0;
BA_ "GenSigFuncType" SG_ 1969 ISO_AAG_Resp_Data 9;
BA_ "GenSigSendType" SG_ 1969 ISO_AAG_Resp_Data 3;
BA_ "GenSigSwitchedByIgnition" SG_ 1806 ISO_BCM1_Req_Data 0;
BA_ "GenSigFuncType" SG_ 1806 ISO_BCM1_Req_Data 9;
BA_ "GenSigSendType" SG_ 1806 ISO_BCM1_Req_Data 3;
BA_ "GenSigSwitchedByIgnition" SG_ 1912 ISO_BCM1_Resp_Data 0;
BA_ "GenSigFuncType" SG_ 1912 ISO_BCM1_Resp_Data 9;
BA_ "GenSigSendType" SG_ 1912 ISO_BCM1_Resp_Data 3;
BA_ "GenSigSwitchedByIgnition" SG_ 1841 ISO_ELV_Req_Data 0;
BA_ "GenSigFuncType" SG_ 1841 ISO_ELV_Req_Data 9;
BA_ "GenSigSendType" SG_ 1841 ISO_ELV_Req_Data 3;
BA_ "GenSigSwitchedByIgnition" SG_ 1947 ISO_ELV_Resp_Data 0;
BA_ "GenSigFuncType" SG_ 1947 ISO_ELV_Resp_Data 9;
BA_ "GenSigSendType" SG_ 1947 ISO_ELV_Resp_Data 3;
BA_ "GenSigSwitchedByIgnition" SG_ 1792 ISO_ALL_01_Req_Data 0;
BA_ "GenSigFuncType" SG_ 1792 ISO_ALL_01_Req_Data 9;
BA_ "GenSigSendType" SG_ 1792 ISO_ALL_01_Req_Data 3;
BA_ "GenSigSwitchedByIgnition" SG_ 1827 ISO_HDSG_Req_Data 0;
BA_ "GenSigFuncType" SG_ 1827 ISO_HDSG_Req_Data 9;
BA_ "GenSigSendType" SG_ 1827 ISO_HDSG_Req_Data 3;
BA_ "GenSigSwitchedByIgnition" SG_ 1933 ISO_HDSG_Resp_Data 0;
BA_ "GenSigFuncType" SG_ 1933 ISO_HDSG_Resp_Data 9;
BA_ "GenSigSendType" SG_ 1933 ISO_HDSG_Resp_Data 3;
BA_ "GenSigSwitchedByIgnition" SG_ 1842 ISO_Kessy_Req_Data 0;
BA_ "GenSigFuncType" SG_ 1842 ISO_Kessy_Req_Data 9;
BA_ "GenSigSendType" SG_ 1842 ISO_Kessy_Req_Data 3;
BA_ "GenSigSwitchedByIgnition" SG_ 1948 ISO_Kessy_Resp_Data 0;
BA_ "GenSigFuncType" SG_ 1948 ISO_Kessy_Resp_Data 9;
BA_ "GenSigSendType" SG_ 1948 ISO_Kessy_Resp_Data 3;
BA_ "GenSigSwitchedByIgnition" SG_ 1836 ISO_MFG_Req_Data 0;
BA_ "GenSigFuncType" SG_ 1836 ISO_MFG_Req_Data 9;
BA_ "GenSigSendType" SG_ 1836 ISO_MFG_Req_Data 3;
BA_ "GenSigSwitchedByIgnition" SG_ 1942 ISO_MFG_Resp_Data 0;
BA_ "GenSigFuncType" SG_ 1942 ISO_MFG_Resp_Data 9;
BA_ "GenSigSendType" SG_ 1942 ISO_MFG_Resp_Data 3;
BA_ "GenSigSwitchedByIgnition" SG_ 2549350921 ISO_OBDC_SKEY_Req_Data 0;
BA_ "GenSigFuncType" SG_ 2549350921 ISO_OBDC_SKEY_Req_Data 9;
BA_ "GenSigSendType" SG_ 2549350921 ISO_OBDC_SKEY_Req_Data 3;
BA_ "GenSigSwitchedByIgnition" SG_ 2549483778 ISO_OBDC_SKEY_Resp_Data 0;
BA_ "GenSigFuncType" SG_ 2549483778 ISO_OBDC_SKEY_Resp_Data 9;
BA_ "GenSigSendType" SG_ 2549483778 ISO_OBDC_SKEY_Resp_Data 3;
BA_ "GenSigSwitchedByIgnition" SG_ 2549350923 ISO_OBDC_VSR_Req_Data 0;
BA_ "GenSigFuncType" SG_ 2549350923 ISO_OBDC_VSR_Req_Data 9;
BA_ "GenSigSendType" SG_ 2549350923 ISO_OBDC_VSR_Req_Data 3;
BA_ "GenSigSwitchedByIgnition" SG_ 2549484290 ISO_OBDC_VSR_Resp_Data 0;
BA_ "GenSigFuncType" SG_ 2549484290 ISO_OBDC_VSR_Resp_Data 9;
BA_ "GenSigSendType" SG_ 2549484290 ISO_OBDC_VSR_Resp_Data 3;
BA_ "GenSigSwitchedByIgnition" SG_ 1869 ISO_Sitzmemo_BFS_Req_Data 0;
BA_ "GenSigFuncType" SG_ 1869 ISO_Sitzmemo_BFS_Req_Data 9;
BA_ "GenSigSendType" SG_ 1869 ISO_Sitzmemo_BFS_Req_Data 3;
BA_ "GenSigSwitchedByIgnition" SG_ 1975 ISO_Sitzmemo_BFS_Resp_Data 0;
BA_ "GenSigFuncType" SG_ 1975 ISO_Sitzmemo_BFS_Resp_Data 9;
BA_ "GenSigSendType" SG_ 1975 ISO_Sitzmemo_BFS_Resp_Data 3;
BA_ "GenSigSwitchedByIgnition" SG_ 1868 ISO_Sitzmemo_FS_Req_Data 0;
BA_ "GenSigFuncType" SG_ 1868 ISO_Sitzmemo_FS_Req_Data 9;
BA_ "GenSigSendType" SG_ 1868 ISO_Sitzmemo_FS_Req_Data 3;
BA_ "GenSigSwitchedByIgnition" SG_ 1974 ISO_Sitzmemo_FS_Resp_Data 0;
BA_ "GenSigFuncType" SG_ 1974 ISO_Sitzmemo_FS_Resp_Data 9;
BA_ "GenSigSendType" SG_ 1974 ISO_Sitzmemo_FS_Resp_Data 3;
BA_ "GenSigSwitchedByIgnition" SG_ 2549352706 ISO_SKEY_OBDC_Req_Data 0;
BA_ "GenSigFuncType" SG_ 2549352706 ISO_SKEY_OBDC_Req_Data 9;
BA_ "GenSigSendType" SG_ 2549352706 ISO_SKEY_OBDC_Req_Data 3;
BA_ "GenSigSwitchedByIgnition" SG_ 2549481993 ISO_SKEY_OBDC_Resp_Data 0;
BA_ "GenSigFuncType" SG_ 2549481993 ISO_SKEY_OBDC_Resp_Data 9;
BA_ "GenSigSendType" SG_ 2549481993 ISO_SKEY_OBDC_Resp_Data 3;
BA_ "GenSigSwitchedByIgnition" SG_ 1828 ISO_SpoilerSG_Req_Data 0;
BA_ "GenSigFuncType" SG_ 1828 ISO_SpoilerSG_Req_Data 9;
BA_ "GenSigSendType" SG_ 1828 ISO_SpoilerSG_Req_Data 3;
BA_ "GenSigSwitchedByIgnition" SG_ 1934 ISO_SpoilerSG_Resp_Data 0;
BA_ "GenSigFuncType" SG_ 1934 ISO_SpoilerSG_Resp_Data 9;
BA_ "GenSigSendType" SG_ 1934 ISO_SpoilerSG_Resp_Data 3;
BA_ "GenSigSwitchedByIgnition" SG_ 1835 ISO_STS_Req_Data 0;
BA_ "GenSigFuncType" SG_ 1835 ISO_STS_Req_Data 9;
BA_ "GenSigSendType" SG_ 1835 ISO_STS_Req_Data 3;
BA_ "GenSigSwitchedByIgnition" SG_ 1941 ISO_STS_Resp_Data 0;
BA_ "GenSigFuncType" SG_ 1941 ISO_STS_Resp_Data 9;
BA_ "GenSigSendType" SG_ 1941 ISO_STS_Resp_Data 3;
BA_ "GenSigSwitchedByIgnition" SG_ 1867 ISO_TSG_BT_Req_Data 0;
BA_ "GenSigFuncType" SG_ 1867 ISO_TSG_BT_Req_Data 9;
BA_ "GenSigSendType" SG_ 1867 ISO_TSG_BT_Req_Data 3;
BA_ "GenSigSwitchedByIgnition" SG_ 1973 ISO_TSG_BT_Resp_Data 0;
BA_ "GenSigFuncType" SG_ 1973 ISO_TSG_BT_Resp_Data 9;
BA_ "GenSigSendType" SG_ 1973 ISO_TSG_BT_Resp_Data 3;
BA_ "GenSigSwitchedByIgnition" SG_ 1866 ISO_TSG_FT_Req_Data 0;
BA_ "GenSigFuncType" SG_ 1866 ISO_TSG_FT_Req_Data 9;
BA_ "GenSigSendType" SG_ 1866 ISO_TSG_FT_Req_Data 3;
BA_ "GenSigSwitchedByIgnition" SG_ 1972 ISO_TSG_FT_Resp_Data 0;
BA_ "GenSigFuncType" SG_ 1972 ISO_TSG_FT_Resp_Data 9;
BA_ "GenSigSendType" SG_ 1972 ISO_TSG_FT_Resp_Data 3;
BA_ "GenSigSwitchedByIgnition" SG_ 1855 ISO_TSG_HBFS_Req_Data 0;
BA_ "GenSigFuncType" SG_ 1855 ISO_TSG_HBFS_Req_Data 9;
BA_ "GenSigSendType" SG_ 1855 ISO_TSG_HBFS_Req_Data 3;
BA_ "GenSigSwitchedByIgnition" SG_ 1961 ISO_TSG_HBFS_Resp_Data 0;
BA_ "GenSigFuncType" SG_ 1961 ISO_TSG_HBFS_Resp_Data 9;
BA_ "GenSigSendType" SG_ 1961 ISO_TSG_HBFS_Resp_Data 3;
BA_ "GenSigSwitchedByIgnition" SG_ 1854 ISO_TSG_HFS_Req_Data 0;
BA_ "GenSigFuncType" SG_ 1854 ISO_TSG_HFS_Req_Data 9;
BA_ "GenSigSendType" SG_ 1854 ISO_TSG_HFS_Req_Data 3;
BA_ "GenSigSwitchedByIgnition" SG_ 1960 ISO_TSG_HFS_Resp_Data 0;
BA_ "GenSigFuncType" SG_ 1960 ISO_TSG_HFS_Resp_Data 9;
BA_ "GenSigSendType" SG_ 1960 ISO_TSG_HFS_Resp_Data 3;
BA_ "GenSigSwitchedByIgnition" SG_ 1837 ISO_VSG_Req_Data 0;
BA_ "GenSigFuncType" SG_ 1837 ISO_VSG_Req_Data 9;
BA_ "GenSigSendType" SG_ 1837 ISO_VSG_Req_Data 3;
BA_ "GenSigSwitchedByIgnition" SG_ 1943 ISO_VSG_Resp_Data 0;
BA_ "GenSigFuncType" SG_ 1943 ISO_VSG_Resp_Data 9;
BA_ "GenSigSendType" SG_ 1943 ISO_VSG_Resp_Data 3;
BA_ "GenSigSwitchedByIgnition" SG_ 2549353218 ISO_VSR_OBDC_Req_Data 0;
BA_ "GenSigFuncType" SG_ 2549353218 ISO_VSR_OBDC_Req_Data 9;
BA_ "GenSigSendType" SG_ 2549353218 ISO_VSR_OBDC_Req_Data 3;
BA_ "GenSigSwitchedByIgnition" SG_ 2549481995 ISO_VSR_OBDC_Resp_Data 0;
BA_ "GenSigFuncType" SG_ 2549481995 ISO_VSR_OBDC_Resp_Data 9;
BA_ "GenSigSendType" SG_ 2549481995 ISO_VSR_OBDC_Resp_Data 3;
BA_ "GenSigSwitchedByIgnition" SG_ 2549874827 ISO_BCM2_Req_Data 0;
BA_ "GenSigFuncType" SG_ 2549874827 ISO_BCM2_Req_Data 9;
BA_ "GenSigSendType" SG_ 2549874827 ISO_BCM2_Req_Data 3;
BA_ "GenSigSwitchedByIgnition" SG_ 2550005899 ISO_BCM2_Resp_Data 0;
BA_ "GenSigFuncType" SG_ 2550005899 ISO_BCM2_Resp_Data 9;
BA_ "GenSigSendType" SG_ 2550005899 ISO_BCM2_Resp_Data 3;
BA_ "GenSigSwitchedByIgnition" SG_ 2549874818 ISO_LCM_L_Req_Data 0;
BA_ "GenSigFuncType" SG_ 2549874818 ISO_LCM_L_Req_Data 9;
BA_ "GenSigSendType" SG_ 2549874818 ISO_LCM_L_Req_Data 3;
BA_ "GenSigSwitchedByIgnition" SG_ 2550005890 ISO_LCM_L_Resp_Data 0;
BA_ "GenSigFuncType" SG_ 2550005890 ISO_LCM_L_Resp_Data 9;
BA_ "GenSigSendType" SG_ 2550005890 ISO_LCM_L_Resp_Data 3;
BA_ "GenSigSwitchedByIgnition" SG_ 2549874819 ISO_LCM_R_Req_Data 0;
BA_ "GenSigFuncType" SG_ 2549874819 ISO_LCM_R_Req_Data 9;
BA_ "GenSigSendType" SG_ 2549874819 ISO_LCM_R_Req_Data 3;
BA_ "GenSigSwitchedByIgnition" SG_ 2550005891 ISO_LCM_R_Resp_Data 0;
BA_ "GenSigFuncType" SG_ 2550005891 ISO_LCM_R_Resp_Data 9;
BA_ "GenSigSendType" SG_ 2550005891 ISO_LCM_R_Resp_Data 3;
BA_ "GenSigSwitchedByIgnition" SG_ 2549874838 ISO_LED_LM_L_Req_Data 0;
BA_ "GenSigFuncType" SG_ 2549874838 ISO_LED_LM_L_Req_Data 9;
BA_ "GenSigSendType" SG_ 2549874838 ISO_LED_LM_L_Req_Data 3;
BA_ "GenSigSwitchedByIgnition" SG_ 2550005910 ISO_LED_LM_L_Resp_Data 0;
BA_ "GenSigFuncType" SG_ 2550005910 ISO_LED_LM_L_Resp_Data 9;
BA_ "GenSigSendType" SG_ 2550005910 ISO_LED_LM_L_Resp_Data 3;
BA_ "GenSigSwitchedByIgnition" SG_ 2549874839 ISO_LED_LM_R_Req_Data 0;
BA_ "GenSigFuncType" SG_ 2549874839 ISO_LED_LM_R_Req_Data 9;
BA_ "GenSigSendType" SG_ 2549874839 ISO_LED_LM_R_Req_Data 3;
BA_ "GenSigSwitchedByIgnition" SG_ 2550005911 ISO_LED_LM_R_Resp_Data 0;
BA_ "GenSigFuncType" SG_ 2550005911 ISO_LED_LM_R_Resp_Data 9;
BA_ "GenSigSendType" SG_ 2550005911 ISO_LED_LM_R_Resp_Data 3;
BA_ "GenSigSwitchedByIgnition" SG_ 2549874848 ISO_SAD2_Req_Data 0;
BA_ "GenSigFuncType" SG_ 2549874848 ISO_SAD2_Req_Data 9;
BA_ "GenSigSendType" SG_ 2549874848 ISO_SAD2_Req_Data 3;
BA_ "GenSigSwitchedByIgnition" SG_ 2550005920 ISO_SAD2_Resp_Data 0;
BA_ "GenSigFuncType" SG_ 2550005920 ISO_SAD2_Resp_Data 9;
BA_ "GenSigSendType" SG_ 2550005920 ISO_SAD2_Resp_Data 3;
BA_ "GenSigSwitchedByIgnition" SG_ 2549874820 ISO_SAD_Req_Data 0;
BA_ "GenSigFuncType" SG_ 2549874820 ISO_SAD_Req_Data 9;
BA_ "GenSigSendType" SG_ 2549874820 ISO_SAD_Req_Data 3;
BA_ "GenSigSwitchedByIgnition" SG_ 2550005892 ISO_SAD_Resp_Data 0;
BA_ "GenSigFuncType" SG_ 2550005892 ISO_SAD_Resp_Data 9;
BA_ "GenSigSendType" SG_ 2550005892 ISO_SAD_Resp_Data 3;
BA_ "GenSigSwitchedByIgnition" SG_ 2549874843 ISO_SBBR_Req_Data 0;
BA_ "GenSigFuncType" SG_ 2549874843 ISO_SBBR_Req_Data 9;
BA_ "GenSigSendType" SG_ 2549874843 ISO_SBBR_Req_Data 3;
BA_ "GenSigSwitchedByIgnition" SG_ 2550005915 ISO_SBBR_Resp_Data 0;
BA_ "GenSigFuncType" SG_ 2550005915 ISO_SBBR_Resp_Data 9;
BA_ "GenSigSendType" SG_ 2550005915 ISO_SBBR_Resp_Data 3;
BA_ "GenSigSwitchedByIgnition" SG_ 2549874824 ISO_Sitzmemo_HBFS_Req_Data 0;
BA_ "GenSigFuncType" SG_ 2549874824 ISO_Sitzmemo_HBFS_Req_Data 9;
BA_ "GenSigSendType" SG_ 2549874824 ISO_Sitzmemo_HBFS_Req_Data 3;
BA_ "GenSigSwitchedByIgnition" SG_ 2550005896 ISO_Sitzmemo_HBFS_Resp_Data 0;
BA_ "GenSigFuncType" SG_ 2550005896 ISO_Sitzmemo_HBFS_Resp_Data 9;
BA_ "GenSigSendType" SG_ 2550005896 ISO_Sitzmemo_HBFS_Resp_Data 3;
BA_ "GenSigSwitchedByIgnition" SG_ 2549874823 ISO_Sitzmemo_HFS_Req_Data 0;
BA_ "GenSigFuncType" SG_ 2549874823 ISO_Sitzmemo_HFS_Req_Data 9;
BA_ "GenSigSendType" SG_ 2549874823 ISO_Sitzmemo_HFS_Req_Data 3;
BA_ "GenSigSwitchedByIgnition" SG_ 2550005895 ISO_Sitzmemo_HFS_Resp_Data 0;
BA_ "GenSigFuncType" SG_ 2550005895 ISO_Sitzmemo_HFS_Resp_Data 9;
BA_ "GenSigSendType" SG_ 2550005895 ISO_Sitzmemo_HFS_Resp_Data 3;
BA_ "GenSigSwitchedByIgnition" SG_ 2549874837 ISO_Sitzmemo_SR3_Req_Data 0;
BA_ "GenSigFuncType" SG_ 2549874837 ISO_Sitzmemo_SR3_Req_Data 9;
BA_ "GenSigSendType" SG_ 2549874837 ISO_Sitzmemo_SR3_Req_Data 3;
BA_ "GenSigSwitchedByIgnition" SG_ 2550005909 ISO_Sitzmemo_SR3_Resp_Data 0;
BA_ "GenSigFuncType" SG_ 2550005909 ISO_Sitzmemo_SR3_Resp_Data 9;
BA_ "GenSigSendType" SG_ 2550005909 ISO_Sitzmemo_SR3_Resp_Data 3;
BA_ "GenSigSwitchedByIgnition" SG_ 497 FBS_IDG_in_Reichweite 0;
BA_ "GenSigSendType" SG_ 497 FBS_IDG_in_Reichweite 2;
BA_ "GenSigSwitchedByIgnition" SG_ 497 FFB_Auf_Taste 0;
BA_ "GenSigSendType" SG_ 497 FFB_Auf_Taste 2;
BA_ "GenSigSwitchedByIgnition" SG_ 497 FFB_HDF_Taste 0;
BA_ "GenSigSendType" SG_ 497 FFB_HDF_Taste 2;
BA_ "GenSigSwitchedByIgnition" SG_ 497 FFB_Panik_Taste 0;
BA_ "GenSigSendType" SG_ 497 FFB_Panik_Taste 2;
BA_ "GenSigSwitchedByIgnition" SG_ 497 FFB_Zu_Taste 0;
BA_ "GenSigSendType" SG_ 497 FFB_Zu_Taste 2;
BA_ "GenSigSwitchedByIgnition" SG_ 497 KY_FT_Entriegelung_Autorisiert 0;
BA_ "GenSigSendType" SG_ 497 KY_FT_Entriegelung_Autorisiert 2;
BA_ "GenSigSwitchedByIgnition" SG_ 497 KY_FT_Verriegelung_Autorisiert 0;
BA_ "GenSigSendType" SG_ 497 KY_FT_Verriegelung_Autorisiert 2;
BA_ "GenSigSwitchedByIgnition" SG_ 497 KY_BT_Entriegelung_Autorisiert 0;
BA_ "GenSigSendType" SG_ 497 KY_BT_Entriegelung_Autorisiert 2;
BA_ "GenSigSwitchedByIgnition" SG_ 497 KY_BT_Verriegelung_Autorisiert 0;
BA_ "GenSigSendType" SG_ 497 KY_BT_Verriegelung_Autorisiert 2;
BA_ "GenSigSwitchedByIgnition" SG_ 497 KY_HFS_Entriegelung_Autorisiert 0;
BA_ "GenSigSendType" SG_ 497 KY_HFS_Entriegelung_Autorisiert 2;
BA_ "GenSigSwitchedByIgnition" SG_ 497 KY_HFS_Verriegelung_Autorisiert 0;
BA_ "GenSigSendType" SG_ 497 KY_HFS_Verriegelung_Autorisiert 2;
BA_ "GenSigSwitchedByIgnition" SG_ 497 KY_HBFS_Entriegelung_Autorisiert 0;
BA_ "GenSigSendType" SG_ 497 KY_HBFS_Entriegelung_Autorisiert 2;
BA_ "GenSigSwitchedByIgnition" SG_ 497 KY_HBFS_Verriegelung_Autorisiert 0;
BA_ "GenSigSendType" SG_ 497 KY_HBFS_Verriegelung_Autorisiert 2;
BA_ "GenSigSwitchedByIgnition" SG_ 497 KY_Front_Entr_Autorisiert 0;
BA_ "GenSigSendType" SG_ 497 KY_Front_Entr_Autorisiert 2;
BA_ "GenSigSwitchedByIgnition" SG_ 497 KY_Front_Verr_Autorisiert 0;
BA_ "GenSigSendType" SG_ 497 KY_Front_Verr_Autorisiert 2;
BA_ "GenSigSwitchedByIgnition" SG_ 497 KY_HD_Entriegelung_Autorisiert 0;
BA_ "GenSigSendType" SG_ 497 KY_HD_Entriegelung_Autorisiert 2;
BA_ "GenSigSwitchedByIgnition" SG_ 497 KY_HD_Verriegelung_Autorisiert 0;
BA_ "GenSigSendType" SG_ 497 KY_HD_Verriegelung_Autorisiert 2;
BA_ "GenSigSwitchedByIgnition" SG_ 497 KY_Bereich 0;
BA_ "GenSigStartValue" SG_ 497 KY_Bereich 7;
BA_ "GenSigSendType" SG_ 497 KY_Bereich 2;
BA_ "GenSigSwitchedByIgnition" SG_ 497 KY_Position 0;
BA_ "GenSigStartValue" SG_ 497 KY_Position 7;
BA_ "GenSigSendType" SG_ 497 KY_Position 2;
BA_ "GenSigSwitchedByIgnition" SG_ 497 KY_ZV_Signatur 0;
BA_ "GenSigSendType" SG_ 497 KY_ZV_Signatur 2;
BA_ "Fehlerwert" SG_ 497 Schluesselnr_Personalisierung 15;
BA_ "GenSigSwitchedByIgnition" SG_ 497 Schluesselnr_Personalisierung 0;
BA_ "GenSigStartValue" SG_ 497 Schluesselnr_Personalisierung 14;
BA_ "GenSigSendType" SG_ 497 Schluesselnr_Personalisierung 2;
BA_ "GenSigSwitchedByIgnition" SG_ 497 FFB_FDF_Taste 0;
BA_ "GenSigSendType" SG_ 497 FFB_FDF_Taste 2;
BA_ "GenSigSwitchedByIgnition" SG_ 497 FFB_Joker_Taste 0;
BA_ "GenSigSendType" SG_ 497 FFB_Joker_Taste 2;
BA_ "GenSigSwitchedByIgnition" SG_ 1424 FBS_Warn_Schluessel_Batt 0;
BA_ "GenSigSendType" SG_ 1424 FBS_Warn_Schluessel_Batt 3;
BA_ "GenSigSwitchedByIgnition" SG_ 1424 KY_FFB_Frequenz 0;
BA_ "GenSigSendType" SG_ 1424 KY_FFB_Frequenz 3;
BA_ "GenSigSwitchedByIgnition" SG_ 1424 KY_HF_Aktiv 0;
BA_ "GenSigSendType" SG_ 1424 KY_HF_Aktiv 3;
BA_ "GenSigSwitchedByIgnition" SG_ 1424 KY_LF_Aktiv 0;
BA_ "GenSigSendType" SG_ 1424 KY_LF_Aktiv 3;
BA_ "GenSigSwitchedByIgnition" SG_ 1424 KY_KYL_Fahrer_Hinweise 0;
BA_ "GenSigSendType" SG_ 1424 KY_KYL_Fahrer_Hinweise 3;
BA_ "GenSigSwitchedByIgnition" SG_ 1424 KY_StartStopp_Info 0;
BA_ "GenSigSendType" SG_ 1424 KY_StartStopp_Info 3;
BA_ "GenSigSwitchedByIgnition" SG_ 1424 KY_Keyless_Verbau 0;
BA_ "GenSigSendType" SG_ 1424 KY_Keyless_Verbau 3;
BA_ "GenSigSwitchedByIgnition" SG_ 1424 KY_Keyless_Go_Verbau 0;
BA_ "GenSigSendType" SG_ 1424 KY_Keyless_Go_Verbau 3;
BA_ "GenSigSwitchedByIgnition" SG_ 1424 KY_Kombinierte_Notspule 0;
BA_ "GenSigSendType" SG_ 1424 KY_Kombinierte_Notspule 3;
BA_ "GenSigSwitchedByIgnition" SG_ 1424 KYL_Warn_kein_Schluessel 0;
BA_ "GenSigSendType" SG_ 1424 KYL_Warn_kein_Schluessel 3;
BA_ "GenSigSwitchedByIgnition" SG_ 1424 KYL_Warn_Kessy_defekt 0;
BA_ "GenSigSendType" SG_ 1424 KYL_Warn_Kessy_defekt 3;
BA_ "GenSigSwitchedByIgnition" SG_ 1424 KYL_Warn_Notzuendschloss 0;
BA_ "GenSigSendType" SG_ 1424 KYL_Warn_Notzuendschloss 3;
BA_ "GenSigSwitchedByIgnition" SG_ 1424 KY_Fzg_Verlassen_erkannt 0;
BA_ "GenSigSendType" SG_ 1424 KY_Fzg_Verlassen_erkannt 3;
BA_ "GenSigSwitchedByIgnition" SG_ 1424 KY_Fzg_Zugang_erkannt 0;
BA_ "GenSigSendType" SG_ 1424 KY_Fzg_Zugang_erkannt 3;
BA_ "GenSigSwitchedByIgnition" SG_ 1424 KST_Wegstrecke_Challenge 0;
BA_ "GenSigSendType" SG_ 1424 KST_Wegstrecke_Challenge 0;
BA_ "GenSigSwitchedByIgnition" SG_ 960 Klemmen_Status_01_CRC 0;
BA_ "GenSigFuncType" SG_ 960 Klemmen_Status_01_CRC 2;
BA_ "GenSigSendType" SG_ 960 Klemmen_Status_01_CRC 0;
BA_ "GenSigSwitchedByIgnition" SG_ 960 Klemmen_Status_01_BZ 0;
BA_ "GenSigFuncType" SG_ 960 Klemmen_Status_01_BZ 1;
BA_ "GenSigSendType" SG_ 960 Klemmen_Status_01_BZ 0;
BA_ "GenSigSwitchedByIgnition" SG_ 960 ZAS_Kl_S 0;
BA_ "GenSigSendType" SG_ 960 ZAS_Kl_S 3;
BA_ "GenSigSwitchedByIgnition" SG_ 960 ZAS_Kl_15 0;
BA_ "GenSigFuncType" SG_ 960 ZAS_Kl_15 6;
BA_ "NWM-WakeupAllowed" SG_ 960 ZAS_Kl_15 1;
BA_ "GenSigSendType" SG_ 960 ZAS_Kl_15 3;
BA_ "GenSigSwitchedByIgnition" SG_ 960 ZAS_Kl_X 0;
BA_ "GenSigSendType" SG_ 960 ZAS_Kl_X 3;
BA_ "GenSigSwitchedByIgnition" SG_ 960 ZAS_Kl_50_Startanforderung 0;
BA_ "GenSigSendType" SG_ 960 ZAS_Kl_50_Startanforderung 3;
BA_ "GenSigSwitchedByIgnition" SG_ 960 BCM_Remotestart_Betrieb 0;
BA_ "GenSigSendType" SG_ 960 BCM_Remotestart_Betrieb 3;
BA_ "GenSigSwitchedByIgnition" SG_ 960 ZAS_Kl_Infotainment 0;
BA_ "GenSigSendType" SG_ 960 ZAS_Kl_Infotainment 3;
BA_ "GenSigSwitchedByIgnition" SG_ 960 BCM_Remotestart_KL15_Anf 0;
BA_ "GenSigSendType" SG_ 960 BCM_Remotestart_KL15_Anf 3;
BA_ "GenSigSwitchedByIgnition" SG_ 960 BCM_Remotestart_MO_Start 0;
BA_ "GenSigSendType" SG_ 960 BCM_Remotestart_MO_Start 3;
BA_ "GenSigSwitchedByIgnition" SG_ 960 KST_Warn_P1_ZST_def 0;
BA_ "GenSigSendType" SG_ 960 KST_Warn_P1_ZST_def 3;
BA_ "GenSigSwitchedByIgnition" SG_ 960 KST_Warn_P2_ZST_def 0;
BA_ "GenSigSendType" SG_ 960 KST_Warn_P2_ZST_def 3;
BA_ "GenSigSwitchedByIgnition" SG_ 960 KST_Fahrerhinweis_1 0;
BA_ "GenSigSendType" SG_ 960 KST_Fahrerhinweis_1 3;
BA_ "GenSigSwitchedByIgnition" SG_ 960 KST_Fahrerhinweis_2 0;
BA_ "GenSigSendType" SG_ 960 KST_Fahrerhinweis_2 3;
BA_ "GenSigSwitchedByIgnition" SG_ 960 KST_Fahrerhinweis_3 0;
BA_ "GenSigSendType" SG_ 960 KST_Fahrerhinweis_3 3;
BA_ "GenSigSwitchedByIgnition" SG_ 960 KST_Fahrerhinweis_4 0;
BA_ "GenSigSendType" SG_ 960 KST_Fahrerhinweis_4 3;
BA_ "GenSigSwitchedByIgnition" SG_ 960 KST_Fahrerhinweis_5 0;
BA_ "GenSigSendType" SG_ 960 KST_Fahrerhinweis_5 3;
BA_ "GenSigSwitchedByIgnition" SG_ 960 KST_Fahrerhinweis_6 0;
BA_ "GenSigSendType" SG_ 960 KST_Fahrerhinweis_6 3;
BA_ "GenSigSwitchedByIgnition" SG_ 1420 Klemmen_Steuerung_01_CRC 0;
BA_ "GenSigFuncType" SG_ 1420 Klemmen_Steuerung_01_CRC 2;
BA_ "GenSigSendType" SG_ 1420 Klemmen_Steuerung_01_CRC 0;
BA_ "GenSigSwitchedByIgnition" SG_ 1420 Klemmen_Steuerung_01_BZ 0;
BA_ "GenSigFuncType" SG_ 1420 Klemmen_Steuerung_01_BZ 1;
BA_ "GenSigSendType" SG_ 1420 Klemmen_Steuerung_01_BZ 0;
BA_ "GenSigSwitchedByIgnition" SG_ 1420 KST_Txt_P_Gang 0;
BA_ "GenSigSendType" SG_ 1420 KST_Txt_P_Gang 3;
BA_ "GenSigSwitchedByIgnition" SG_ 1420 KST_Txt_Panikabschaltung 0;
BA_ "GenSigSendType" SG_ 1420 KST_Txt_Panikabschaltung 3;
BA_ "GenSigSwitchedByIgnition" SG_ 1420 KST_Anf_Klemmenfreigabe_ELV 0;
BA_ "GenSigSendType" SG_ 1420 KST_Anf_Klemmenfreigabe_ELV 3;
BA_ "GenSigSwitchedByIgnition" SG_ 1420 KST_Txt_Komfortabschaltung 0;
BA_ "GenSigSendType" SG_ 1420 KST_Txt_Komfortabschaltung 3;
BA_ "GenSigSwitchedByIgnition" SG_ 1420 KST_ZAT_betaetigt 0;
BA_ "GenSigSendType" SG_ 1420 KST_ZAT_betaetigt 3;
BA_ "GenSigSwitchedByIgnition" SG_ 1420 KST_Unterdr_Zuendungsmeldung 0;
BA_ "GenSigSendType" SG_ 1420 KST_Unterdr_Zuendungsmeldung 3;
BA_ "GenSigSwitchedByIgnition" SG_ 1420 KST_aut_Abschaltung_Zuendung 0;
BA_ "GenSigSendType" SG_ 1420 KST_aut_Abschaltung_Zuendung 4;
BA_ "GenSigActiveRepetitions" SG_ 1420 KST_aut_Abschaltung_Zuendung 3;
BA_ "GenSigSwitchedByIgnition" SG_ 1420 KST_Anf_ZV_Verriegelung 0;
BA_ "GenSigSendType" SG_ 1420 KST_Anf_ZV_Verriegelung 3;
BA_ "GenSigSwitchedByIgnition" SG_ 1646 KL_STL_aktiv 0;
BA_ "GenSigSendType" SG_ 1646 KL_STL_aktiv 3;
BA_ "GenSigSwitchedByIgnition" SG_ 1646 KL_STH_aktiv 0;
BA_ "GenSigSendType" SG_ 1646 KL_STH_aktiv 3;
BA_ "GenSigSwitchedByIgnition" SG_ 1646 KL_Solarluefter_aktiv 0;
BA_ "GenSigSendType" SG_ 1646 KL_Solarluefter_aktiv 3;
BA_ "GenSigSwitchedByIgnition" SG_ 1646 KL_Umluft_Taste 0;
BA_ "GenSigSendType" SG_ 1646 KL_Umluft_Taste 3;
BA_ "Fehlerwert" SG_ 1646 KL_Geblaese_Fond_Status 15;
BA_ "GenSigSwitchedByIgnition" SG_ 1646 KL_Geblaese_Fond_Status 0;
BA_ "GenSigStartValue" SG_ 1646 KL_Geblaese_Fond_Status 14;
BA_ "GenSigSendType" SG_ 1646 KL_Geblaese_Fond_Status 0;
BA_ "GenSigSwitchedByIgnition" SG_ 1646 KL_STH_Ansteuerung 0;
BA_ "GenSigSendType" SG_ 1646 KL_STH_Ansteuerung 3;
BA_ "GenSigSwitchedByIgnition" SG_ 1646 KL_STH_Betriebsdauer 0;
BA_ "GenSigSendType" SG_ 1646 KL_STH_Betriebsdauer 3;
BA_ "GenSigSwitchedByIgnition" SG_ 1646 KL_Magnetventil 0;
BA_ "GenSigSendType" SG_ 1646 KL_Magnetventil 3;
BA_ "GenSigSwitchedByIgnition" SG_ 1646 KL_WaPu 0;
BA_ "GenSigSendType" SG_ 1646 KL_WaPu 3;
BA_ "Fehlerwert" SG_ 1646 KL_Geblaese_Status 15;
BA_ "GenSigSwitchedByIgnition" SG_ 1646 KL_Geblaese_Status 0;
BA_ "GenSigStartValue" SG_ 1646 KL_Geblaese_Status 14;
BA_ "GenSigSendType" SG_ 1646 KL_Geblaese_Status 0;
BA_ "GenSigSwitchedByIgnition" SG_ 1646 KL_Restwaerme_aktiv 0;
BA_ "GenSigSendType" SG_ 1646 KL_Restwaerme_aktiv 3;
BA_ "GenSigSwitchedByIgnition" SG_ 1646 KL_Kompressorkupplung 0;
BA_ "GenSigSendType" SG_ 1646 KL_Kompressorkupplung 3;
BA_ "GenSigSwitchedByIgnition" SG_ 1646 KL_BCmE_Livetip_Freigabe 0;
BA_ "GenSigSendType" SG_ 1646 KL_BCmE_Livetip_Freigabe 3;
BA_ "GenSigSwitchedByIgnition" SG_ 1646 KL_HYB_ASV_hinten_schliessen_Anf 0;
BA_ "GenSigSendType" SG_ 1646 KL_HYB_ASV_hinten_schliessen_Anf 3;
BA_ "GenSigSwitchedByIgnition" SG_ 1646 KL_HYB_ASV_vorne_schliessen_Anf 0;
BA_ "GenSigSendType" SG_ 1646 KL_HYB_ASV_vorne_schliessen_Anf 3;
BA_ "GenSigSwitchedByIgnition" SG_ 1646 KL_HYB_Spuelbetrieb_Freigabe 0;
BA_ "GenSigSendType" SG_ 1646 KL_HYB_Spuelbetrieb_Freigabe 3;
BA_ "Fehlerwert" SG_ 1646 KL_Innen_Temp 255;
BA_ "GenSigSwitchedByIgnition" SG_ 1646 KL_Innen_Temp 0;
BA_ "GenSigStartValue" SG_ 1646 KL_Innen_Temp 254;
BA_ "GenSigSendType" SG_ 1646 KL_Innen_Temp 0;
BA_ "GenSigSwitchedByIgnition" SG_ 1646 KL_FSH_Automatikbetrieb 0;
BA_ "GenSigSendType" SG_ 1646 KL_FSH_Automatikbetrieb 3;
BA_ "GenSigSwitchedByIgnition" SG_ 1646 KL_SIH_LEH_Verteilung_VL 0;
BA_ "GenSigSendType" SG_ 1646 KL_SIH_LEH_Verteilung_VL 3;
BA_ "GenSigSwitchedByIgnition" SG_ 1646 KL_SIH_LEL_Verteilung_VL 0;
BA_ "GenSigSendType" SG_ 1646 KL_SIH_LEL_Verteilung_VL 3;
BA_ "GenSigSwitchedByIgnition" SG_ 1646 KL_SIH_LEH_Verteilung_VR 0;
BA_ "GenSigSendType" SG_ 1646 KL_SIH_LEH_Verteilung_VR 3;
BA_ "GenSigSwitchedByIgnition" SG_ 1646 KL_SIH_LEL_Verteilung_VR 0;
BA_ "GenSigSendType" SG_ 1646 KL_SIH_LEL_Verteilung_VR 3;
BA_ "GenSigSwitchedByIgnition" SG_ 949 KL_Drehz_Anh 0;
BA_ "GenSigSendType" SG_ 949 KL_Drehz_Anh 0;
BA_ "GenSigSwitchedByIgnition" SG_ 949 KL_Vorwarn_Komp_ein 0;
BA_ "GenSigSendType" SG_ 949 KL_Vorwarn_Komp_ein 0;
BA_ "GenSigSwitchedByIgnition" SG_ 949 KL_AC_Schalter 0;
BA_ "GenSigSendType" SG_ 949 KL_AC_Schalter 0;
BA_ "GenSigSwitchedByIgnition" SG_ 949 KL_Komp_Moment_alt 0;
BA_ "GenSigFuncType" SG_ 949 KL_Komp_Moment_alt 5;
BA_ "GenSigSendType" SG_ 949 KL_Komp_Moment_alt 0;
BA_ "GenSigSwitchedByIgnition" SG_ 949 KL_Vorwarn_Zuheizer_ein 0;
BA_ "GenSigSendType" SG_ 949 KL_Vorwarn_Zuheizer_ein 0;
BA_ "GenSigSwitchedByIgnition" SG_ 949 KL_Zustand 0;
BA_ "GenSigSendType" SG_ 949 KL_Zustand 0;
BA_ "GenSigSwitchedByIgnition" SG_ 949 KL_Kompressorkupplung_linear 0;
BA_ "GenSigStartValue" SG_ 949 KL_Kompressorkupplung_linear 254;
BA_ "GenSigSendType" SG_ 949 KL_Kompressorkupplung_linear 0;
BA_ "GenSigSwitchedByIgnition" SG_ 949 KL_Charisma_FahrPr 0;
BA_ "GenSigSendType" SG_ 949 KL_Charisma_FahrPr 0;
BA_ "GenSigSwitchedByIgnition" SG_ 949 KL_Charisma_Status 0;
BA_ "GenSigSendType" SG_ 949 KL_Charisma_Status 0;
BA_ "GenSigSwitchedByIgnition" SG_ 949 KL_nachtr_Stopp_Anf 0;
BA_ "GenSigSendType" SG_ 949 KL_nachtr_Stopp_Anf 0;
BA_ "GenSigSwitchedByIgnition" SG_ 949 KL_T_Charge 0;
BA_ "GenSigSendType" SG_ 949 KL_T_Charge 0;
BA_ "Fehlerwert" SG_ 949 KL_Last_Kompr 255;
BA_ "GenSigSwitchedByIgnition" SG_ 949 KL_Last_Kompr 0;
BA_ "GenSigSendType" SG_ 949 KL_Last_Kompr 0;
BA_ "GenSigSwitchedByIgnition" SG_ 949 KL_Spannungs_Anf 0;
BA_ "GenSigSendType" SG_ 949 KL_Spannungs_Anf 0;
BA_ "GenSigSwitchedByIgnition" SG_ 949 KL_Thermomanagement 0;
BA_ "GenSigSendType" SG_ 949 KL_Thermomanagement 0;
BA_ "GenSigSwitchedByIgnition" SG_ 949 KL_StartStopp_Info 0;
BA_ "GenSigSendType" SG_ 949 KL_StartStopp_Info 0;
BA_ "GenSigSwitchedByIgnition" SG_ 949 KL_Freilauf_Info 0;
BA_ "GenSigSendType" SG_ 949 KL_Freilauf_Info 0;
BA_ "Fehlerwert" SG_ 949 KL_Anf_KL 255;
BA_ "GenSigSwitchedByIgnition" SG_ 949 KL_Anf_KL 0;
BA_ "GenSigSendType" SG_ 949 KL_Anf_KL 0;
BA_ "GenSigSwitchedByIgnition" SG_ 949 KL_el_Zuheizer_Stufe 0;
BA_ "GenSigSendType" SG_ 949 KL_el_Zuheizer_Stufe 0;
BA_ "GenSigSwitchedByIgnition" SG_ 949 KL_Ausstattung_Klima 0;
BA_ "GenSigSendType" SG_ 949 KL_Ausstattung_Klima 0;
BA_ "GenSigSwitchedByIgnition" SG_ 1640 KL_LRH_Taster 0;
BA_ "GenSigSendType" SG_ 1640 KL_LRH_Taster 0;
BA_ "GenSigSwitchedByIgnition" SG_ 1640 KL_LRH_Stufe 0;
BA_ "GenSigStartValue" SG_ 1640 KL_LRH_Stufe 1;
BA_ "GenSigSendType" SG_ 1640 KL_LRH_Stufe 0;
BA_ "GenSigSwitchedByIgnition" SG_ 1640 HSH_Taster 0;
BA_ "GenSigSendType" SG_ 1640 HSH_Taster 4;
BA_ "GenSigActiveRepetitions" SG_ 1640 HSH_Taster 5;
BA_ "GenSigSwitchedByIgnition" SG_ 1640 FSH_Taster 0;
BA_ "GenSigSendType" SG_ 1640 FSH_Taster 4;
BA_ "GenSigActiveRepetitions" SG_ 1640 FSH_Taster 5;
BA_ "GenSigSwitchedByIgnition" SG_ 1640 KL_Zuheizer_Freigabe 0;
BA_ "GenSigSendType" SG_ 1640 KL_Zuheizer_Freigabe 3;
BA_ "GenSigSwitchedByIgnition" SG_ 1640 KL_Beschlagsgefahr 0;
BA_ "GenSigSendType" SG_ 1640 KL_Beschlagsgefahr 3;
BA_ "GenSigSwitchedByIgnition" SG_ 1640 KL_SIH_Soll_li 0;
BA_ "GenSigSendType" SG_ 1640 KL_SIH_Soll_li 3;
BA_ "GenSigSwitchedByIgnition" SG_ 1640 KL_SIH_Soll_re 0;
BA_ "GenSigSendType" SG_ 1640 KL_SIH_Soll_re 3;
BA_ "GenSigSwitchedByIgnition" SG_ 1640 KRH_Soll_li 0;
BA_ "GenSigSendType" SG_ 1640 KRH_Soll_li 3;
BA_ "GenSigSwitchedByIgnition" SG_ 1640 KL_SIL_Soll_li 0;
BA_ "GenSigSendType" SG_ 1640 KL_SIL_Soll_li 3;
BA_ "GenSigSwitchedByIgnition" SG_ 1640 KL_SIL_Soll_re 0;
BA_ "GenSigSendType" SG_ 1640 KL_SIL_Soll_re 3;
BA_ "GenSigSwitchedByIgnition" SG_ 1640 KRH_Soll_re 0;
BA_ "GenSigSendType" SG_ 1640 KRH_Soll_re 3;
BA_ "Fehlerwert" SG_ 1640 KL_Geblspng_Soll 255;
BA_ "GenSigSwitchedByIgnition" SG_ 1640 KL_Geblspng_Soll 0;
BA_ "GenSigSendType" SG_ 1640 KL_Geblspng_Soll 0;
BA_ "Fehlerwert" SG_ 1640 KL_Geblspng_Fond_Soll 255;
BA_ "GenSigSwitchedByIgnition" SG_ 1640 KL_Geblspng_Fond_Soll 0;
BA_ "GenSigSendType" SG_ 1640 KL_Geblspng_Fond_Soll 0;
BA_ "Fehlerwert" SG_ 1640 KL_I_Geblaese 255;
BA_ "GenSigSwitchedByIgnition" SG_ 1640 KL_I_Geblaese 0;
BA_ "GenSigSendType" SG_ 1640 KL_I_Geblaese 0;
BA_ "Fehlerwert" SG_ 1640 KL_Kompressorstrom_soll 1023;
BA_ "GenSigSwitchedByIgnition" SG_ 1640 KL_Kompressorstrom_soll 0;
BA_ "GenSigStartValue" SG_ 1640 KL_Kompressorstrom_soll 1022;
BA_ "GenSigSendType" SG_ 1640 KL_Kompressorstrom_soll 0;
BA_ "Fehlerwert" SG_ 1640 KL_Umluftklappe_Status 15;
BA_ "GenSigSwitchedByIgnition" SG_ 1640 KL_Umluftklappe_Status 0;
BA_ "GenSigStartValue" SG_ 1640 KL_Umluftklappe_Status 14;
BA_ "GenSigSendType" SG_ 1640 KL_Umluftklappe_Status 0;
BA_ "GenSigSwitchedByIgnition" SG_ 1640 KL_PTC_Verbauinfo 0;
BA_ "GenSigSendType" SG_ 1640 KL_PTC_Verbauinfo 0;
BA_ "GenSigSwitchedByIgnition" SG_ 1441 KL_Temp_Soll_hl 0;
BA_ "GenSigStartValue" SG_ 1441 KL_Temp_Soll_hl 31;
BA_ "GenSigSendType" SG_ 1441 KL_Temp_Soll_hl 0;
BA_ "GenSigSwitchedByIgnition" SG_ 1441 KL_Temp_Soll_hr 0;
BA_ "GenSigStartValue" SG_ 1441 KL_Temp_Soll_hr 31;
BA_ "GenSigSendType" SG_ 1441 KL_Temp_Soll_hr 0;
BA_ "GenSigSwitchedByIgnition" SG_ 1441 KL_Temp_Soll_vl 0;
BA_ "GenSigStartValue" SG_ 1441 KL_Temp_Soll_vl 31;
BA_ "GenSigSendType" SG_ 1441 KL_Temp_Soll_vl 0;
BA_ "GenSigSwitchedByIgnition" SG_ 1441 KL_Temp_Soll_vr 0;
BA_ "GenSigStartValue" SG_ 1441 KL_Temp_Soll_vr 31;
BA_ "GenSigSendType" SG_ 1441 KL_Temp_Soll_vr 0;
BA_ "GenSigSwitchedByIgnition" SG_ 1441 KL_SIH_Stufe_hl 0;
BA_ "GenSigSendType" SG_ 1441 KL_SIH_Stufe_hl 0;
BA_ "GenSigSwitchedByIgnition" SG_ 1441 KL_SIH_Stufe_hr 0;
BA_ "GenSigSendType" SG_ 1441 KL_SIH_Stufe_hr 0;
BA_ "GenSigSwitchedByIgnition" SG_ 1441 KL_SIL_Stufe_hl 0;
BA_ "GenSigSendType" SG_ 1441 KL_SIL_Stufe_hl 0;
BA_ "GenSigSwitchedByIgnition" SG_ 1441 KL_SIL_Stufe_hr 0;
BA_ "GenSigSendType" SG_ 1441 KL_SIL_Stufe_hr 0;
BA_ "GenSigSwitchedByIgnition" SG_ 1441 KL_SIL_LEL_Verteilung_HR 0;
BA_ "GenSigSendType" SG_ 1441 KL_SIL_LEL_Verteilung_HR 0;
BA_ "GenSigSwitchedByIgnition" SG_ 1441 KL_SIL_LEL_Verteilung_HL 0;
BA_ "GenSigSendType" SG_ 1441 KL_SIL_LEL_Verteilung_HL 0;
BA_ "GenSigSwitchedByIgnition" SG_ 1441 KL_SIH_LEH_Verteilung_HR 0;
BA_ "GenSigSendType" SG_ 1441 KL_SIH_LEH_Verteilung_HR 0;
BA_ "Fehlerwert" SG_ 1441 KL_PTC_linear_Anf 63;
BA_ "GenSigSwitchedByIgnition" SG_ 1441 KL_PTC_linear_Anf 0;
BA_ "GenSigSendType" SG_ 1441 KL_PTC_linear_Anf 0;
BA_ "GenSigSwitchedByIgnition" SG_ 1441 KL_SIH_LEH_Verteilung_HL 0;
BA_ "GenSigSendType" SG_ 1441 KL_SIH_LEH_Verteilung_HL 0;
BA_ "Fehlerwert" SG_ 1441 KL_Frischluftklappe_Status 127;
BA_ "GenSigSwitchedByIgnition" SG_ 1441 KL_Frischluftklappe_Status 0;
BA_ "GenSigStartValue" SG_ 1441 KL_Frischluftklappe_Status 126;
BA_ "GenSigSendType" SG_ 1441 KL_Frischluftklappe_Status 0;
BA_ "Fehlerwert" SG_ 992 KL_Fond_Fuss_Temp_hl 1023;
BA_ "GenSigSwitchedByIgnition" SG_ 992 KL_Fond_Fuss_Temp_hl 0;
BA_ "GenSigStartValue" SG_ 992 KL_Fond_Fuss_Temp_hl 1022;
BA_ "GenSigSendType" SG_ 992 KL_Fond_Fuss_Temp_hl 0;
BA_ "GenSigSwitchedByIgnition" SG_ 992 KL_SL_Soll_hl 0;
BA_ "GenSigSendType" SG_ 992 KL_SL_Soll_hl 0;
BA_ "GenSigSwitchedByIgnition" SG_ 992 KL_SL_Soll_hr 0;
BA_ "GenSigSendType" SG_ 992 KL_SL_Soll_hr 0;
BA_ "Fehlerwert" SG_ 992 KL_Fond_Fuss_Temp_hr 1023;
BA_ "GenSigSwitchedByIgnition" SG_ 992 KL_Fond_Fuss_Temp_hr 0;
BA_ "GenSigStartValue" SG_ 992 KL_Fond_Fuss_Temp_hr 1022;
BA_ "GenSigSendType" SG_ 992 KL_Fond_Fuss_Temp_hr 0;
BA_ "GenSigSwitchedByIgnition" SG_ 992 KL_SH_Soll_hl 0;
BA_ "GenSigSendType" SG_ 992 KL_SH_Soll_hl 0;
BA_ "GenSigSwitchedByIgnition" SG_ 992 KL_SH_Soll_hr 0;
BA_ "GenSigSendType" SG_ 992 KL_SH_Soll_hr 0;
BA_ "Fehlerwert" SG_ 992 KL_MA_Temp_hl 1023;
BA_ "GenSigSwitchedByIgnition" SG_ 992 KL_MA_Temp_hl 0;
BA_ "GenSigStartValue" SG_ 992 KL_MA_Temp_hl 1022;
BA_ "GenSigSendType" SG_ 992 KL_MA_Temp_hl 0;
BA_ "GenSigSwitchedByIgnition" SG_ 992 KL_SIH_Takt_hl 0;
BA_ "GenSigSendType" SG_ 992 KL_SIH_Takt_hl 0;
BA_ "GenSigSwitchedByIgnition" SG_ 992 KL_SIH_Takt_hr 0;
BA_ "GenSigSendType" SG_ 992 KL_SIH_Takt_hr 0;
BA_ "GenSigSwitchedByIgnition" SG_ 992 KL_Fehler_Umluft 0;
BA_ "GenSigSendType" SG_ 992 KL_Fehler_Umluft 0;
BA_ "GenSigSwitchedByIgnition" SG_ 992 KL_RAB 0;
BA_ "GenSigSendType" SG_ 992 KL_RAB 0;
BA_ "GenSigSwitchedByIgnition" SG_ 992 KL_Fond_Absperrventil 0;
BA_ "GenSigSendType" SG_ 992 KL_Fond_Absperrventil 0;
BA_ "GenSigSwitchedByIgnition" SG_ 992 KL_Fond_KD_Fehler 0;
BA_ "GenSigSendType" SG_ 992 KL_Fond_KD_Fehler 0;
BA_ "Fehlerwert" SG_ 992 KL_MA_Temp_hr 1023;
BA_ "GenSigSwitchedByIgnition" SG_ 992 KL_MA_Temp_hr 0;
BA_ "GenSigStartValue" SG_ 992 KL_MA_Temp_hr 1022;
BA_ "GenSigSendType" SG_ 992 KL_MA_Temp_hr 0;
BA_ "GenSigSwitchedByIgnition" SG_ 992 KL_Fehler_Fussraum_Klappen 0;
BA_ "GenSigSendType" SG_ 992 KL_Fehler_Fussraum_Klappen 0;
BA_ "GenSigSwitchedByIgnition" SG_ 992 KL_Fehler_Temp_Klappen 0;
BA_ "GenSigSendType" SG_ 992 KL_Fehler_Temp_Klappen 0;
BA_ "GenSigSwitchedByIgnition" SG_ 992 KL_Fehler_Temp_MA_Klappen 0;
BA_ "GenSigSendType" SG_ 992 KL_Fehler_Temp_MA_Klappen 0;
BA_ "GenSigMissingSourceValue" SG_ 1712 FS_Taupunkt 1023;
BA_ "Fehlerwert" SG_ 1712 FS_Taupunkt 1023;
BA_ "GenSigSendType" SG_ 1712 FS_Taupunkt 0;
BA_ "Fehlerwert" SG_ 1712 FS_ResponseError 1;
BA_ "GenSigSendType" SG_ 1712 FS_ResponseError 0;
BA_ "GenSigMissingSourceValue" SG_ 1712 FS_Temp_Scheibe 1023;
BA_ "Fehlerwert" SG_ 1712 FS_Temp_Scheibe 1023;
BA_ "GenSigSendType" SG_ 1712 FS_Temp_Scheibe 0;
BA_ "GenSigMissingSourceValue" SG_ 1712 FS_Temp_Sensor 255;
BA_ "Fehlerwert" SG_ 1712 FS_Temp_Sensor 255;
BA_ "GenSigSendType" SG_ 1712 FS_Temp_Sensor 0;
BA_ "GenSigMissingSourceValue" SG_ 1712 FS_Luftfeuchte_rel 255;
BA_ "Fehlerwert" SG_ 1712 FS_Luftfeuchte_rel 255;
BA_ "GenSigSendType" SG_ 1712 FS_Luftfeuchte_rel 0;
BA_ "Fehlerwert" SG_ 1505 BCM1_Aussen_Temp_ungef 255;
BA_ "GenSigSwitchedByIgnition" SG_ 1505 BCM1_Aussen_Temp_ungef 0;
BA_ "GenSigStartValue" SG_ 1505 BCM1_Aussen_Temp_ungef 254;
BA_ "GenSigSendType" SG_ 1505 BCM1_Aussen_Temp_ungef 0;
BA_ "Fehlerwert" SG_ 1505 BCM_Heizungsabsperrventil_Status 3;
BA_ "GenSigSwitchedByIgnition" SG_ 1505 BCM_Heizungsabsperrventil_Status 0;
BA_ "GenSigStartValue" SG_ 1505 BCM_Heizungsabsperrventil_Status 2;
BA_ "GenSigSendType" SG_ 1505 BCM_Heizungsabsperrventil_Status 0;
BA_ "Fehlerwert" SG_ 1505 BCM_Heizungspumpe_Status 3;
BA_ "GenSigSwitchedByIgnition" SG_ 1505 BCM_Heizungspumpe_Status 0;
BA_ "GenSigStartValue" SG_ 1505 BCM_Heizungspumpe_Status 2;
BA_ "GenSigSendType" SG_ 1505 BCM_Heizungspumpe_Status 0;
BA_ "Fehlerwert" SG_ 1505 BCM_Kompressorkupplung_Status 3;
BA_ "GenSigSwitchedByIgnition" SG_ 1505 BCM_Kompressorkupplung_Status 0;
BA_ "GenSigStartValue" SG_ 1505 BCM_Kompressorkupplung_Status 2;
BA_ "GenSigSendType" SG_ 1505 BCM_Kompressorkupplung_Status 0;
BA_ "Fehlerwert" SG_ 1505 BCM1_PTC_stufig_Status 7;
BA_ "GenSigSwitchedByIgnition" SG_ 1505 BCM1_PTC_stufig_Status 0;
BA_ "GenSigStartValue" SG_ 1505 BCM1_PTC_stufig_Status 6;
BA_ "GenSigSendType" SG_ 1505 BCM1_PTC_stufig_Status 0;
BA_ "GenSigSwitchedByIgnition" SG_ 1505 BCM1_FStatus_Aussentemp_ungef 0;
BA_ "GenSigStartValue" SG_ 1505 BCM1_FStatus_Aussentemp_ungef 1;
BA_ "GenSigSendType" SG_ 1505 BCM1_FStatus_Aussentemp_ungef 0;
BA_ "Fehlerwert" SG_ 1505 BCM1_Kompressorstrom_ist 255;
BA_ "GenSigSwitchedByIgnition" SG_ 1505 BCM1_Kompressorstrom_ist 0;
BA_ "GenSigStartValue" SG_ 1505 BCM1_Kompressorstrom_ist 254;
BA_ "GenSigSendType" SG_ 1505 BCM1_Kompressorstrom_ist 0;
BA_ "GenSigSwitchedByIgnition" SG_ 1505 BCM1_OBD_FStatus_ATemp 0;
BA_ "GenSigSendType" SG_ 1505 BCM1_OBD_FStatus_ATemp 0;
BA_ "GenSigSwitchedByIgnition" SG_ 2549088327 AAG_KompSchutz 0;
BA_ "GenSigSendType" SG_ 2549088327 AAG_KompSchutz 0;
BA_ "GenSigSwitchedByIgnition" SG_ 2549088327 AAG_Abschaltstufe 0;
BA_ "GenSigSendType" SG_ 2549088327 AAG_Abschaltstufe 0;
BA_ "GenSigSwitchedByIgnition" SG_ 2549088327 AAG_Transport_Mode 0;
BA_ "GenSigSendType" SG_ 2549088327 AAG_Transport_Mode 0;
BA_ "GenSigSwitchedByIgnition" SG_ 2549088327 AAG_Nachlauftyp 0;
BA_ "GenSigStartValue" SG_ 2549088327 AAG_Nachlauftyp 2;
BA_ "GenSigSendType" SG_ 2549088327 AAG_Nachlauftyp 0;
BA_ "GenSigSwitchedByIgnition" SG_ 2549088327 AAG_SNI 0;
BA_ "GenSigStartValue" SG_ 2549088327 AAG_SNI 71;
BA_ "GenSigSendType" SG_ 2549088327 AAG_SNI 0;
BA_ "GenSigSwitchedByIgnition" SG_ 2549088327 NM_AAG_Wakeup 0;
BA_ "NWM-WakeupAllowed" SG_ 2549088327 NM_AAG_Wakeup 1;
BA_ "GenSigSendType" SG_ 2549088327 NM_AAG_Wakeup 0;
BA_ "GenSigSwitchedByIgnition" SG_ 2549088327 NM_AAG_Lokalaktiv 0;
BA_ "GenSigSendType" SG_ 2549088327 NM_AAG_Lokalaktiv 0;
BA_ "GenSigSwitchedByIgnition" SG_ 2549088327 NM_AAG_Subsystemaktiv 0;
BA_ "GenSigSendType" SG_ 2549088327 NM_AAG_Subsystemaktiv 0;
BA_ "GenSigSwitchedByIgnition" SG_ 2549088327 AAG_KD_Fehler 0;
BA_ "GenSigSendType" SG_ 2549088327 AAG_KD_Fehler 0;
BA_ "GenSigSwitchedByIgnition" SG_ 2549088270 BCM1_KompSchutz 0;
BA_ "GenSigSendType" SG_ 2549088270 BCM1_KompSchutz 0;
BA_ "GenSigSwitchedByIgnition" SG_ 2549088270 BCM1_Abschaltstufe 0;
BA_ "GenSigSendType" SG_ 2549088270 BCM1_Abschaltstufe 0;
BA_ "GenSigSwitchedByIgnition" SG_ 2549088270 BCM1_Transport_Mode 0;
BA_ "GenSigSendType" SG_ 2549088270 BCM1_Transport_Mode 0;
BA_ "GenSigSwitchedByIgnition" SG_ 2549088270 BCM1_Nachlauftyp 0;
BA_ "GenSigStartValue" SG_ 2549088270 BCM1_Nachlauftyp 2;
BA_ "GenSigSendType" SG_ 2549088270 BCM1_Nachlauftyp 0;
BA_ "GenSigSwitchedByIgnition" SG_ 2549088270 BCM1_SNI 0;
BA_ "GenSigStartValue" SG_ 2549088270 BCM1_SNI 14;
BA_ "GenSigSendType" SG_ 2549088270 BCM1_SNI 0;
BA_ "GenSigSwitchedByIgnition" SG_ 2549088270 NM_BCM1_Wakeup 0;
BA_ "NWM-WakeupAllowed" SG_ 2549088270 NM_BCM1_Wakeup 1;
BA_ "GenSigSendType" SG_ 2549088270 NM_BCM1_Wakeup 0;
BA_ "GenSigSwitchedByIgnition" SG_ 2549088270 NM_BCM1_Lokalaktiv 0;
BA_ "GenSigSendType" SG_ 2549088270 NM_BCM1_Lokalaktiv 0;
BA_ "GenSigSwitchedByIgnition" SG_ 2549088270 NM_BCM1_Subsystemaktiv 0;
BA_ "GenSigSendType" SG_ 2549088270 NM_BCM1_Subsystemaktiv 0;
BA_ "GenSigSwitchedByIgnition" SG_ 2549088270 BCM1_KD_Fehler 0;
BA_ "GenSigSendType" SG_ 2549088270 BCM1_KD_Fehler 0;
BA_ "GenSigSwitchedByIgnition" SG_ 2549088395 BCM2_KompSchutz 0;
BA_ "GenSigSendType" SG_ 2549088395 BCM2_KompSchutz 0;
BA_ "GenSigSwitchedByIgnition" SG_ 2549088395 BCM2_Abschaltstufe 0;
BA_ "GenSigSendType" SG_ 2549088395 BCM2_Abschaltstufe 0;
BA_ "GenSigSwitchedByIgnition" SG_ 2549088395 BCM2_Transport_Mode 0;
BA_ "GenSigSendType" SG_ 2549088395 BCM2_Transport_Mode 0;
BA_ "GenSigSwitchedByIgnition" SG_ 2549088395 BCM2_Nachlauftyp 0;
BA_ "GenSigStartValue" SG_ 2549088395 BCM2_Nachlauftyp 2;
BA_ "GenSigSendType" SG_ 2549088395 BCM2_Nachlauftyp 0;
BA_ "GenSigSwitchedByIgnition" SG_ 2549088395 BCM2_SNI 0;
BA_ "GenSigStartValue" SG_ 2549088395 BCM2_SNI 139;
BA_ "GenSigSendType" SG_ 2549088395 BCM2_SNI 0;
BA_ "GenSigSwitchedByIgnition" SG_ 2549088395 NM_BCM2_Wakeup 0;
BA_ "NWM-WakeupAllowed" SG_ 2549088395 NM_BCM2_Wakeup 1;
BA_ "GenSigSendType" SG_ 2549088395 NM_BCM2_Wakeup 0;
BA_ "GenSigSwitchedByIgnition" SG_ 2549088395 NM_BCM2_Lokalaktiv 0;
BA_ "GenSigSendType" SG_ 2549088395 NM_BCM2_Lokalaktiv 0;
BA_ "GenSigSwitchedByIgnition" SG_ 2549088395 NM_BCM2_Subsystemaktiv 0;
BA_ "GenSigSendType" SG_ 2549088395 NM_BCM2_Subsystemaktiv 0;
BA_ "GenSigSwitchedByIgnition" SG_ 2549088395 BCM2_KD_Fehler 0;
BA_ "GenSigSendType" SG_ 2549088395 BCM2_KD_Fehler 0;
BA_ "GenSigSwitchedByIgnition" SG_ 2549088305 ELV_KompSchutz 0;
BA_ "GenSigSendType" SG_ 2549088305 ELV_KompSchutz 0;
BA_ "GenSigSwitchedByIgnition" SG_ 2549088305 ELV_Abschaltstufe 0;
BA_ "GenSigSendType" SG_ 2549088305 ELV_Abschaltstufe 0;
BA_ "GenSigSwitchedByIgnition" SG_ 2549088305 ELV_Transport_Mode 0;
BA_ "GenSigSendType" SG_ 2549088305 ELV_Transport_Mode 0;
BA_ "GenSigSwitchedByIgnition" SG_ 2549088305 ELV_Nachlauftyp 0;
BA_ "GenSigStartValue" SG_ 2549088305 ELV_Nachlauftyp 2;
BA_ "GenSigSendType" SG_ 2549088305 ELV_Nachlauftyp 0;
BA_ "GenSigSwitchedByIgnition" SG_ 2549088305 ELV_SNI 0;
BA_ "GenSigStartValue" SG_ 2549088305 ELV_SNI 49;
BA_ "GenSigSendType" SG_ 2549088305 ELV_SNI 0;
BA_ "GenSigSwitchedByIgnition" SG_ 2549088305 NM_ELV_Wakeup 0;
BA_ "NWM-WakeupAllowed" SG_ 2549088305 NM_ELV_Wakeup 1;
BA_ "GenSigSendType" SG_ 2549088305 NM_ELV_Wakeup 0;
BA_ "GenSigSwitchedByIgnition" SG_ 2549088305 NM_ELV_Lokalaktiv 0;
BA_ "GenSigSendType" SG_ 2549088305 NM_ELV_Lokalaktiv 0;
BA_ "GenSigSwitchedByIgnition" SG_ 2549088305 NM_ELV_Subsystemaktiv 0;
BA_ "GenSigSendType" SG_ 2549088305 NM_ELV_Subsystemaktiv 0;
BA_ "GenSigSwitchedByIgnition" SG_ 2549088305 ELV_KD_Fehler 0;
BA_ "GenSigSendType" SG_ 2549088305 ELV_KD_Fehler 0;
BA_ "GenSigSwitchedByIgnition" SG_ 2549088272 Gateway_KompSchutz 0;
BA_ "GenSigSendType" SG_ 2549088272 Gateway_KompSchutz 0;
BA_ "GenSigSwitchedByIgnition" SG_ 2549088272 Gateway_Abschaltstufe 0;
BA_ "GenSigSendType" SG_ 2549088272 Gateway_Abschaltstufe 0;
BA_ "GenSigSwitchedByIgnition" SG_ 2549088272 Gateway_Transport_Mode 0;
BA_ "GenSigSendType" SG_ 2549088272 Gateway_Transport_Mode 0;
BA_ "GenSigSwitchedByIgnition" SG_ 2549088272 Gateway_Nachlauftyp 0;
BA_ "GenSigStartValue" SG_ 2549088272 Gateway_Nachlauftyp 2;
BA_ "GenSigSendType" SG_ 2549088272 Gateway_Nachlauftyp 0;
BA_ "GenSigSwitchedByIgnition" SG_ 2549088272 Gateway_SNI 0;
BA_ "GenSigStartValue" SG_ 2549088272 Gateway_SNI 16;
BA_ "GenSigSendType" SG_ 2549088272 Gateway_SNI 0;
BA_ "GenSigSwitchedByIgnition" SG_ 2549088272 NM_Gateway_Wakeup 0;
BA_ "NWM-WakeupAllowed" SG_ 2549088272 NM_Gateway_Wakeup 1;
BA_ "GenSigSendType" SG_ 2549088272 NM_Gateway_Wakeup 0;
BA_ "GenSigSwitchedByIgnition" SG_ 2549088272 NM_Gateway_Lokalaktiv 0;
BA_ "GenSigSendType" SG_ 2549088272 NM_Gateway_Lokalaktiv 0;
BA_ "GenSigSendType" SG_ 2549088272 NM_Gateway_Subsystemaktiv 0;
BA_ "GenSigSendType" SG_ 2549088272 GW_KD_Fehler 0;
BA_ "GenSigSwitchedByIgnition" SG_ 2549088291 HDSG_KompSchutz 0;
BA_ "GenSigSendType" SG_ 2549088291 HDSG_KompSchutz 0;
BA_ "GenSigSwitchedByIgnition" SG_ 2549088291 HDSG_Abschaltstufe 0;
BA_ "GenSigSendType" SG_ 2549088291 HDSG_Abschaltstufe 0;
BA_ "GenSigSwitchedByIgnition" SG_ 2549088291 HDSG_Transport_Mode 0;
BA_ "GenSigSendType" SG_ 2549088291 HDSG_Transport_Mode 0;
BA_ "GenSigSwitchedByIgnition" SG_ 2549088291 HDSG_Nachlauftyp 0;
BA_ "GenSigStartValue" SG_ 2549088291 HDSG_Nachlauftyp 2;
BA_ "GenSigSendType" SG_ 2549088291 HDSG_Nachlauftyp 0;
BA_ "GenSigSwitchedByIgnition" SG_ 2549088291 HDSG_SNI 0;
BA_ "GenSigStartValue" SG_ 2549088291 HDSG_SNI 35;
BA_ "GenSigSendType" SG_ 2549088291 HDSG_SNI 0;
BA_ "GenSigSwitchedByIgnition" SG_ 2549088291 NM_HDSG_Wakeup 0;
BA_ "NWM-WakeupAllowed" SG_ 2549088291 NM_HDSG_Wakeup 1;
BA_ "GenSigSendType" SG_ 2549088291 NM_HDSG_Wakeup 0;
BA_ "GenSigSwitchedByIgnition" SG_ 2549088291 KN_HDSG_WakePrevention 0;
BA_ "GenSigSendType" SG_ 2549088291 KN_HDSG_WakePrevention 0;
BA_ "GenSigSwitchedByIgnition" SG_ 2549088291 NM_HDSG_Lokalaktiv 0;
BA_ "GenSigSendType" SG_ 2549088291 NM_HDSG_Lokalaktiv 0;
BA_ "GenSigSwitchedByIgnition" SG_ 2549088291 NM_HDSG_Subsystemaktiv 0;
BA_ "GenSigSendType" SG_ 2549088291 NM_HDSG_Subsystemaktiv 0;
BA_ "GenSigSwitchedByIgnition" SG_ 2549088291 HD_KD_Fehler 0;
BA_ "GenSigSendType" SG_ 2549088291 HD_KD_Fehler 0;
BA_ "GenSigSwitchedByIgnition" SG_ 2549088306 Kessy_KompSchutz 0;
BA_ "GenSigSendType" SG_ 2549088306 Kessy_KompSchutz 0;
BA_ "GenSigSwitchedByIgnition" SG_ 2549088306 Kessy_Abschaltstufe 0;
BA_ "GenSigSendType" SG_ 2549088306 Kessy_Abschaltstufe 0;
BA_ "GenSigSwitchedByIgnition" SG_ 2549088306 Kessy_Transport_Mode 0;
BA_ "GenSigSendType" SG_ 2549088306 Kessy_Transport_Mode 0;
BA_ "GenSigSwitchedByIgnition" SG_ 2549088306 Kessy_Nachlauftyp 0;
BA_ "GenSigStartValue" SG_ 2549088306 Kessy_Nachlauftyp 2;
BA_ "GenSigSendType" SG_ 2549088306 Kessy_Nachlauftyp 0;
BA_ "GenSigSwitchedByIgnition" SG_ 2549088306 Kessy_SNI 0;
BA_ "GenSigStartValue" SG_ 2549088306 Kessy_SNI 50;
BA_ "GenSigSendType" SG_ 2549088306 Kessy_SNI 0;
BA_ "GenSigSwitchedByIgnition" SG_ 2549088306 NM_Kessy_Wakeup 0;
BA_ "NWM-WakeupAllowed" SG_ 2549088306 NM_Kessy_Wakeup 1;
BA_ "GenSigSendType" SG_ 2549088306 NM_Kessy_Wakeup 0;
BA_ "GenSigSwitchedByIgnition" SG_ 2549088306 KN_Kessy_ECUKnockOut 0;
BA_ "GenSigSendType" SG_ 2549088306 KN_Kessy_ECUKnockOut 0;
BA_ "GenSigSwitchedByIgnition" SG_ 2549088306 KN_Kessy_WakePrevention 0;
BA_ "GenSigSendType" SG_ 2549088306 KN_Kessy_WakePrevention 0;
BA_ "GenSigSwitchedByIgnition" SG_ 2549088306 NM_Kessy_Lokalaktiv 0;
BA_ "GenSigSendType" SG_ 2549088306 NM_Kessy_Lokalaktiv 0;
BA_ "GenSigSwitchedByIgnition" SG_ 2549088306 Kessy_KD_Fehler 0;
BA_ "GenSigSendType" SG_ 2549088306 Kessy_KD_Fehler 0;
BA_REL_ "GenSigTimeoutTime" BU_SG_REL_ VTS SG_ 1381 HVLM_Ladetexte 5000;
BA_REL_ "GenSigTimeoutTime" BU_SG_REL_ VTS SG_ 1340 HVLM_Stecker_Status 5000;
BA_REL_ "GenSigTimeoutTime" BU_SG_REL_ BCM2 SG_ 371 IEZS_01_CRC 5000;
BA_REL_ "GenSigTimeoutTime" BU_SG_REL_ BCM2 SG_ 371 IEZS_01_BZ 5000;
BA_REL_ "GenSigTimeoutTime" BU_SG_REL_ BCM2 SG_ 371 IEZS_Anf_KL15 5000;
BA_REL_ "GenSigTimeoutTime" BU_SG_REL_ BCM2 SG_ 371 IEZS_Anf_KL50 5000;
BA_REL_ "GenSigTimeoutTime" BU_SG_REL_ BCM2 SG_ 371 IEZS_Anf_Klemmen_Aus 5000;
BA_REL_ "GenSigTimeoutTime" BU_SG_REL_ BCM2 SG_ 371 IEZS_AnfLeitung_KL15_Fehler 5000;
BA_REL_ "GenSigTimeoutTime" BU_SG_REL_ BCM2 SG_ 371 IEZS_AnfLeitung_KL50_Fehler 5000;
BA_REL_ "GenSigTimeoutTime" BU_SG_REL_ BCM2 SG_ 371 IEZS_F_Zuendanlassschalter_1 5000;
BA_REL_ "GenSigTimeoutTime" BU_SG_REL_ BCM2 SG_ 371 IEZS_F_Zuendanlassschalter_2 5000;
BA_REL_ "GenSigTimeoutTime" BU_SG_REL_ BCM2 SG_ 371 IEZS_Init_KlemmenAnf 5000;
BA_REL_ "GenSigTimeoutTime" BU_SG_REL_ BCM2 SG_ 371 IEZS_Noteinspeisung_erkannt 5000;
BA_REL_ "GenSigTimeoutTime" BU_SG_REL_ BCM2 SG_ 371 IEZS_T_Deckel_Vorne 5000;
BA_REL_ "GenSigTimeoutTime" BU_SG_REL_ BCM2 SG_ 371 IEZS_T_Deckel_Vorne_Fehler 5000;
BA_REL_ "GenSigTimeoutTime" BU_SG_REL_ BCM2 SG_ 371 IEZS_TrunkEntrapment_Fehler 5000;
BA_REL_ "GenSigTimeoutTime" BU_SG_REL_ TSG_BFS SG_ 1524 IL_Dimmung_V_Tuerkontur 5000;
BA_REL_ "GenSigTimeoutTime" BU_SG_REL_ TSG_FS SG_ 1524 IL_Dimmung_V_Tuerkontur 5000;
BA_REL_ "GenSigTimeoutTime" BU_SG_REL_ TSG_BFS SG_ 1524 IL_Dimmung_H_Tuerkontur 5000;
BA_REL_ "GenSigTimeoutTime" BU_SG_REL_ TSG_FS SG_ 1524 IL_Dimmung_H_Tuerkontur 5000;
BA_REL_ "GenSigTimeoutTime" BU_SG_REL_ TSG_BFS SG_ 1524 IL_Dimmung_Tuerinnengriff 5000;
BA_REL_ "GenSigTimeoutTime" BU_SG_REL_ TSG_FS SG_ 1524 IL_Dimmung_Tuerinnengriff 5000;
BA_REL_ "GenSigTimeoutTime" BU_SG_REL_ TSG_BFS SG_ 1524 IL_Dimmung_Umfeldbel 5000;
BA_REL_ "GenSigTimeoutTime" BU_SG_REL_ TSG_FS SG_ 1524 IL_Dimmung_Umfeldbel 5000;
BA_REL_ "GenSigTimeoutTime" BU_SG_REL_ TSG_FS SG_ 1524 IL_Bel_FS_Ausstieg 5000;
BA_REL_ "GenSigTimeoutTime" BU_SG_REL_ TSG_BFS SG_ 1524 IL_Bel_BFS_Ausstieg 5000;
BA_REL_ "GenSigTimeoutTime" BU_SG_REL_ TSG_FS SG_ 1524 IL_Bel_HFS_Ausstieg 5000;
BA_REL_ "GenSigTimeoutTime" BU_SG_REL_ TSG_BFS SG_ 1524 IL_Bel_HBFS_Ausstieg 5000;
BA_REL_ "GenSigTimeoutTime" BU_SG_REL_ Gateway SG_ 1524 IL_Innenlicht_aktiv 5000;
BA_REL_ "GenSigTimeoutTime" BU_SG_REL_ TSG_BFS SG_ 1524 IL_Klemme_30G_aktiv 5000;
BA_REL_ "GenSigTimeoutTime" BU_SG_REL_ TSG_FS SG_ 1524 IL_Klemme_30G_aktiv 5000;
BA_REL_ "GenSigTimeoutTime" BU_SG_REL_ TSG_FS SG_ 1524 BCM1_Innenlicht_H 5000;
BA_REL_ "GenSigTimeoutTime" BU_SG_REL_ Gateway SG_ 1524 AMB_Charisma_FahrPr 5000;
BA_REL_ "GenSigTimeoutTime" BU_SG_REL_ Gateway SG_ 1524 AMB_Charisma_Status 5000;
BA_REL_ "GenSigTimeoutTime" BU_SG_REL_ TSG_BFS SG_ 1524 IL_Dimmung_Lautspr 5000;
BA_REL_ "GenSigTimeoutTime" BU_SG_REL_ TSG_FS SG_ 1524 IL_Dimmung_Lautspr 5000;
BA_REL_ "GenSigTimeoutTime" BU_SG_REL_ BCM1 SG_ 312 IPA_Fahrtaster_LED 2000;
BA_REL_ "GenSigTimeoutTime" BU_SG_REL_ BCM1 SG_ 312 IPA_Status_IPA_TSK 2000;
BA_REL_ "GenSigTimeoutTime" BU_SG_REL_ BCM1 SG_ 312 IPA_PLA_LED 2000;
BA_REL_ "GenSigTimeoutTime" BU_SG_REL_ BCM1 SG_ 312 IPA_APS_LED 2000;
BA_REL_ "GenSigTimeoutTime" BU_SG_REL_ HDSG SG_ 497 FBS_IDG_in_Reichweite 5000;
BA_REL_ "GenSigTimeoutTime" BU_SG_REL_ SitzMem_FS SG_ 497 FFB_Auf_Taste 5000;
BA_REL_ "GenSigTimeoutTime" BU_SG_REL_ AAG SG_ 497 FFB_HDF_Taste 5000;
BA_REL_ "GenSigTimeoutTime" BU_SG_REL_ BCM1 SG_ 497 FFB_HDF_Taste 5000;
BA_REL_ "GenSigTimeoutTime" BU_SG_REL_ HDSG SG_ 497 FFB_HDF_Taste 5000;
BA_REL_ "GenSigTimeoutTime" BU_SG_REL_ MFG SG_ 497 FFB_Panik_Taste 5000;
BA_REL_ "GenSigTimeoutTime" BU_SG_REL_ SitzMem_FS SG_ 497 FFB_Panik_Taste 5000;
BA_REL_ "GenSigTimeoutTime" BU_SG_REL_ SitzMem_FS SG_ 497 FFB_Zu_Taste 5000;
BA_REL_ "GenSigTimeoutTime" BU_SG_REL_ SitzMem_FS SG_ 497 KY_FT_Entriegelung_Autorisiert 5000;
BA_REL_ "GenSigTimeoutTime" BU_SG_REL_ TSG_BFS SG_ 497 KY_FT_Entriegelung_Autorisiert 5000;
BA_REL_ "GenSigTimeoutTime" BU_SG_REL_ TSG_FS SG_ 497 KY_FT_Entriegelung_Autorisiert 5000;
BA_REL_ "GenSigTimeoutTime" BU_SG_REL_ TSG_FS SG_ 497 KY_FT_Verriegelung_Autorisiert 5000;
BA_REL_ "GenSigTimeoutTime" BU_SG_REL_ TSG_BFS SG_ 497 KY_BT_Entriegelung_Autorisiert 5000;
BA_REL_ "GenSigTimeoutTime" BU_SG_REL_ TSG_BFS SG_ 497 KY_BT_Verriegelung_Autorisiert 5000;
BA_REL_ "GenSigTimeoutTime" BU_SG_REL_ TSG_FS SG_ 497 KY_HFS_Entriegelung_Autorisiert 5000;
BA_REL_ "GenSigTimeoutTime" BU_SG_REL_ TSG_FS SG_ 497 KY_HFS_Verriegelung_Autorisiert 5000;
BA_REL_ "GenSigTimeoutTime" BU_SG_REL_ TSG_BFS SG_ 497 KY_HBFS_Entriegelung_Autorisiert 5000;
BA_REL_ "GenSigTimeoutTime" BU_SG_REL_ TSG_BFS SG_ 497 KY_HBFS_Verriegelung_Autorisiert 5000;
BA_REL_ "GenSigTimeoutTime" BU_SG_REL_ BCM1 SG_ 497 KY_Front_Entr_Autorisiert 5000;
BA_REL_ "GenSigTimeoutTime" BU_SG_REL_ BCM1 SG_ 497 KY_Front_Verr_Autorisiert 5000;
BA_REL_ "GenSigTimeoutTime" BU_SG_REL_ HDSG SG_ 497 KY_HD_Entriegelung_Autorisiert 5000;
BA_REL_ "GenSigTimeoutTime" BU_SG_REL_ HDSG SG_ 497 KY_HD_Verriegelung_Autorisiert 5000;
BA_REL_ "GenSigTimeoutTime" BU_SG_REL_ BCM1 SG_ 497 KY_Bereich 5000;
BA_REL_ "GenSigTimeoutTime" BU_SG_REL_ BCM1 SG_ 497 KY_Position 5000;
BA_REL_ "GenSigTimeoutTime" BU_SG_REL_ TSG_BFS SG_ 497 KY_ZV_Signatur 5000;
BA_REL_ "GenSigTimeoutTime" BU_SG_REL_ TSG_FS SG_ 497 KY_ZV_Signatur 5000;
BA_REL_ "GenSigTimeoutTime" BU_SG_REL_ BCM1 SG_ 497 Schluesselnr_Personalisierung 5000;
BA_REL_ "GenSigTimeoutTime" BU_SG_REL_ Gateway SG_ 497 Schluesselnr_Personalisierung 5000;
BA_REL_ "GenSigTimeoutTime" BU_SG_REL_ MFG SG_ 497 Schluesselnr_Personalisierung 5000;
BA_REL_ "GenSigTimeoutTime" BU_SG_REL_ SitzMem_BFS SG_ 497 Schluesselnr_Personalisierung 5000;
BA_REL_ "GenSigTimeoutTime" BU_SG_REL_ SitzMem_FS SG_ 497 Schluesselnr_Personalisierung 5000;
BA_REL_ "GenSigTimeoutTime" BU_SG_REL_ TSG_BFS SG_ 497 Schluesselnr_Personalisierung 5000;
BA_REL_ "GenSigTimeoutTime" BU_SG_REL_ TSG_FS SG_ 497 Schluesselnr_Personalisierung 5000;
BA_REL_ "GenSigTimeoutTime" BU_SG_REL_ BCM1 SG_ 497 FFB_FDF_Taste 5000;
BA_REL_ "GenSigTimeoutTime" BU_SG_REL_ BCM1 SG_ 497 FFB_Joker_Taste 5000;
BA_REL_ "GenSigTimeoutTime" BU_SG_REL_ VSG SG_ 497 FFB_Joker_Taste 5000;
BA_REL_ "GenSigTimeoutTime" BU_SG_REL_ HDSG SG_ 1424 KY_FFB_Frequenz 2000;
BA_REL_ "GenSigTimeoutTime" BU_SG_REL_ HDSG SG_ 1424 KY_HF_Aktiv 2000;
BA_REL_ "GenSigTimeoutTime" BU_SG_REL_ HDSG SG_ 1424 KY_LF_Aktiv 2000;
BA_REL_ "GenSigTimeoutTime" BU_SG_REL_ Gateway SG_ 1424 KY_StartStopp_Info 2000;
BA_REL_ "GenSigTimeoutTime" BU_SG_REL_ ELV SG_ 1424 KY_Fzg_Verlassen_erkannt 2000;
BA_REL_ "GenSigTimeoutTime" BU_SG_REL_ ELV SG_ 1424 KY_Fzg_Zugang_erkannt 2000;
BA_REL_ "GenSigTimeoutTime" BU_SG_REL_ AAG SG_ 960 Klemmen_Status_01_CRC 1000;
BA_REL_ "GenSigTimeoutTime" BU_SG_REL_ BCM1 SG_ 960 Klemmen_Status_01_CRC 1000;
BA_REL_ "GenSigTimeoutTime" BU_SG_REL_ ELV SG_ 960 Klemmen_Status_01_CRC 1000;
BA_REL_ "GenSigTimeoutTime" BU_SG_REL_ Gateway SG_ 960 Klemmen_Status_01_CRC 1000;
BA_REL_ "GenSigTimeoutTime" BU_SG_REL_ SitzMem_SR3 SG_ 960 Klemmen_Status_01_CRC 1000;
BA_REL_ "GenSigTimeoutTime" BU_SG_REL_ AAG SG_ 960 Klemmen_Status_01_BZ 1000;
BA_REL_ "GenSigTimeoutTime" BU_SG_REL_ BCM1 SG_ 960 Klemmen_Status_01_BZ 1000;
BA_REL_ "GenSigTimeoutTime" BU_SG_REL_ ELV SG_ 960 Klemmen_Status_01_BZ 1000;
BA_REL_ "GenSigTimeoutTime" BU_SG_REL_ Gateway SG_ 960 Klemmen_Status_01_BZ 1000;
BA_REL_ "GenSigTimeoutTime" BU_SG_REL_ SitzMem_SR3 SG_ 960 Klemmen_Status_01_BZ 1000;
BA_REL_ "GenSigTimeoutTime" BU_SG_REL_ VTS SG_ 960 Klemmen_Status_01_BZ 1000;
BA_REL_ "GenSigTimeoutTime" BU_SG_REL_ AAG SG_ 960 ZAS_Kl_S 1000;
BA_REL_ "GenSigTimeoutTime" BU_SG_REL_ BCM1 SG_ 960 ZAS_Kl_S 1000;
BA_REL_ "GenSigTimeoutTime" BU_SG_REL_ ELV SG_ 960 ZAS_Kl_S 1000;
BA_REL_ "GenSigTimeoutTime" BU_SG_REL_ Gateway SG_ 960 ZAS_Kl_S 1000;
BA_REL_ "GenSigTimeoutTime" BU_SG_REL_ HDSG SG_ 960 ZAS_Kl_S 1000;
BA_REL_ "GenSigTimeoutTime" BU_SG_REL_ IEZS SG_ 960 ZAS_Kl_S 1000;
BA_REL_ "GenSigTimeoutTime" BU_SG_REL_ SAD SG_ 960 ZAS_Kl_S 1000;
BA_REL_ "GenSigTimeoutTime" BU_SG_REL_ SAD2 SG_ 960 ZAS_Kl_S 1000;
BA_REL_ "GenSigTimeoutTime" BU_SG_REL_ SitzMem_BFS SG_ 960 ZAS_Kl_S 1000;
BA_REL_ "GenSigTimeoutTime" BU_SG_REL_ SitzMem_FS SG_ 960 ZAS_Kl_S 1000;
BA_REL_ "GenSigTimeoutTime" BU_SG_REL_ SitzMem_HBFS SG_ 960 ZAS_Kl_S 1000;
BA_REL_ "GenSigTimeoutTime" BU_SG_REL_ SitzMem_HFS SG_ 960 ZAS_Kl_S 1000;
BA_REL_ "GenSigTimeoutTime" BU_SG_REL_ SitzMem_SR3 SG_ 960 ZAS_Kl_S 1000;
BA_REL_ "GenSigTimeoutTime" BU_SG_REL_ TSG_BFS SG_ 960 ZAS_Kl_S 1000;
BA_REL_ "GenSigTimeoutTime" BU_SG_REL_ TSG_FS SG_ 960 ZAS_Kl_S 1000;
BA_REL_ "GenSigTimeoutTime" BU_SG_REL_ VSG SG_ 960 ZAS_Kl_S 1000;
BA_REL_ "GenSigTimeoutTime" BU_SG_REL_ VTS SG_ 960 ZAS_Kl_S 1000;
BA_REL_ "GenSigTimeoutTime" BU_SG_REL_ AAG SG_ 960 ZAS_Kl_15 1000;
BA_REL_ "GenSigTimeoutTime" BU_SG_REL_ BCM1 SG_ 960 ZAS_Kl_15 1000;
BA_REL_ "GenSigTimeoutTime" BU_SG_REL_ ELV SG_ 960 ZAS_Kl_15 1000;
BA_REL_ "GenSigTimeoutTime" BU_SG_REL_ Gateway SG_ 960 ZAS_Kl_15 1000;
BA_REL_ "GenSigTimeoutTime" BU_SG_REL_ HDSG SG_ 960 ZAS_Kl_15 1000;
BA_REL_ "GenSigTimeoutTime" BU_SG_REL_ IEZS SG_ 960 ZAS_Kl_15 1000;
BA_REL_ "GenSigTimeoutTime" BU_SG_REL_ MSBBR SG_ 960 ZAS_Kl_15 1000;
BA_REL_ "GenSigTimeoutTime" BU_SG_REL_ SAD SG_ 960 ZAS_Kl_15 1000;
BA_REL_ "GenSigTimeoutTime" BU_SG_REL_ SAD2 SG_ 960 ZAS_Kl_15 1000;
BA_REL_ "GenSigTimeoutTime" BU_SG_REL_ SitzMem_BFS SG_ 960 ZAS_Kl_15 1000;
BA_REL_ "GenSigTimeoutTime" BU_SG_REL_ SitzMem_FS SG_ 960 ZAS_Kl_15 1000;
BA_REL_ "GenSigTimeoutTime" BU_SG_REL_ SitzMem_HBFS SG_ 960 ZAS_Kl_15 1000;
BA_REL_ "GenSigTimeoutTime" BU_SG_REL_ SitzMem_HFS SG_ 960 ZAS_Kl_15 1000;
BA_REL_ "GenSigTimeoutTime" BU_SG_REL_ SitzMem_SR3 SG_ 960 ZAS_Kl_15 1000;
BA_REL_ "GenSigTimeoutTime" BU_SG_REL_ SpoilerSG SG_ 960 ZAS_Kl_15 1000;
BA_REL_ "GenSigTimeoutTime" BU_SG_REL_ TSG_BFS SG_ 960 ZAS_Kl_15 1000;
BA_REL_ "GenSigTimeoutTime" BU_SG_REL_ TSG_FS SG_ 960 ZAS_Kl_15 1000;
BA_REL_ "GenSigTimeoutTime" BU_SG_REL_ VSG SG_ 960 ZAS_Kl_15 1000;
BA_REL_ "GenSigTimeoutTime" BU_SG_REL_ VTS SG_ 960 ZAS_Kl_15 1000;
BA_REL_ "GenSigTimeoutTime" BU_SG_REL_ AAG SG_ 960 ZAS_Kl_50_Startanforderung 1000;
BA_REL_ "GenSigTimeoutTime" BU_SG_REL_ BCM1 SG_ 960 ZAS_Kl_50_Startanforderung 1000;
BA_REL_ "GenSigTimeoutTime" BU_SG_REL_ Gateway SG_ 960 ZAS_Kl_50_Startanforderung 1000;
BA_REL_ "GenSigTimeoutTime" BU_SG_REL_ IEZS SG_ 960 ZAS_Kl_50_Startanforderung 1000;
BA_REL_ "GenSigTimeoutTime" BU_SG_REL_ SAD SG_ 960 ZAS_Kl_50_Startanforderung 1000;
BA_REL_ "GenSigTimeoutTime" BU_SG_REL_ SAD2 SG_ 960 ZAS_Kl_50_Startanforderung 1000;
BA_REL_ "GenSigTimeoutTime" BU_SG_REL_ TSG_BFS SG_ 960 ZAS_Kl_50_Startanforderung 1000;
BA_REL_ "GenSigTimeoutTime" BU_SG_REL_ TSG_FS SG_ 960 ZAS_Kl_50_Startanforderung 1000;
BA_REL_ "GenSigTimeoutTime" BU_SG_REL_ VTS SG_ 960 ZAS_Kl_50_Startanforderung 1000;
BA_REL_ "GenSigTimeoutTime" BU_SG_REL_ ELV SG_ 960 BCM_Remotestart_Betrieb 1000;
BA_REL_ "GenSigTimeoutTime" BU_SG_REL_ Gateway SG_ 960 BCM_Remotestart_Betrieb 1000;
BA_REL_ "GenSigTimeoutTime" BU_SG_REL_ TSG_BFS SG_ 960 BCM_Remotestart_Betrieb 1000;
BA_REL_ "GenSigTimeoutTime" BU_SG_REL_ TSG_FS SG_ 960 BCM_Remotestart_Betrieb 1000;
BA_REL_ "GenSigTimeoutTime" BU_SG_REL_ Gateway SG_ 960 BCM_Remotestart_KL15_Anf 1000;
BA_REL_ "GenSigTimeoutTime" BU_SG_REL_ Gateway SG_ 960 BCM_Remotestart_MO_Start 1000;
BA_REL_ "GenSigTimeoutTime" BU_SG_REL_ ELV SG_ 1420 KST_Anf_Klemmenfreigabe_ELV 5000;
BA_REL_ "GenSigTimeoutTime" BU_SG_REL_ BCM1 SG_ 1420 KST_aut_Abschaltung_Zuendung 5000;
BA_REL_ "GenSigTimeoutTime" BU_SG_REL_ BCM2 SG_ 1646 KL_STL_aktiv 5000;
BA_REL_ "GenSigTimeoutTime" BU_SG_REL_ BCM1 SG_ 1646 KL_STH_aktiv 5000;
BA_REL_ "GenSigTimeoutTime" BU_SG_REL_ BCM2 SG_ 1646 KL_STH_aktiv 5000;
BA_REL_ "GenSigTimeoutTime" BU_SG_REL_ TSG_FS SG_ 1646 KL_STH_aktiv 5000;
BA_REL_ "GenSigTimeoutTime" BU_SG_REL_ BCM2 SG_ 1646 KL_Solarluefter_aktiv 5000;
BA_REL_ "GenSigTimeoutTime" BU_SG_REL_ HDSG SG_ 1646 KL_Solarluefter_aktiv 5000;
BA_REL_ "GenSigTimeoutTime" BU_SG_REL_ BCM2 SG_ 1646 KL_Geblaese_Fond_Status 5000;
BA_REL_ "GenSigTimeoutTime" BU_SG_REL_ HDSG SG_ 1646 KL_Geblaese_Fond_Status 5000;
BA_REL_ "GenSigTimeoutTime" BU_SG_REL_ SAD SG_ 1646 KL_Geblaese_Fond_Status 5000;
BA_REL_ "GenSigTimeoutTime" BU_SG_REL_ BCM1 SG_ 1646 KL_WaPu 5000;
BA_REL_ "GenSigTimeoutTime" BU_SG_REL_ BCM2 SG_ 1646 KL_Geblaese_Status 5000;
BA_REL_ "GenSigTimeoutTime" BU_SG_REL_ HDSG SG_ 1646 KL_Geblaese_Status 5000;
BA_REL_ "GenSigTimeoutTime" BU_SG_REL_ SAD SG_ 1646 KL_Geblaese_Status 5000;
BA_REL_ "GenSigTimeoutTime" BU_SG_REL_ SAD2 SG_ 1646 KL_Geblaese_Status 5000;
BA_REL_ "GenSigTimeoutTime" BU_SG_REL_ BCM1 SG_ 1646 KL_Restwaerme_aktiv 5000;
BA_REL_ "GenSigTimeoutTime" BU_SG_REL_ BCM2 SG_ 1646 KL_Restwaerme_aktiv 5000;
BA_REL_ "GenSigTimeoutTime" BU_SG_REL_ BCM1 SG_ 1646 KL_Kompressorkupplung 5000;
BA_REL_ "GenSigTimeoutTime" BU_SG_REL_ BCM1 SG_ 1646 KL_Innen_Temp 5000;
BA_REL_ "GenSigTimeoutTime" BU_SG_REL_ BCM2 SG_ 1646 KL_Innen_Temp 5000;
BA_REL_ "GenSigTimeoutTime" BU_SG_REL_ HDSG SG_ 1646 KL_Innen_Temp 5000;
BA_REL_ "GenSigTimeoutTime" BU_SG_REL_ SAD SG_ 1646 KL_Innen_Temp 5000;
BA_REL_ "GenSigTimeoutTime" BU_SG_REL_ SAD2 SG_ 1646 KL_Innen_Temp 5000;
BA_REL_ "GenSigTimeoutTime" BU_SG_REL_ SitzMem_BFS SG_ 1646 KL_Innen_Temp 5000;
BA_REL_ "GenSigTimeoutTime" BU_SG_REL_ SitzMem_FS SG_ 1646 KL_Innen_Temp 5000;
BA_REL_ "GenSigTimeoutTime" BU_SG_REL_ SitzMem_HBFS SG_ 1646 KL_Innen_Temp 5000;
BA_REL_ "GenSigTimeoutTime" BU_SG_REL_ SitzMem_HFS SG_ 1646 KL_Innen_Temp 5000;
BA_REL_ "GenSigTimeoutTime" BU_SG_REL_ SitzMem_SR3 SG_ 1646 KL_Innen_Temp 5000;
BA_REL_ "GenSigTimeoutTime" BU_SG_REL_ TSG_BFS SG_ 1646 KL_Innen_Temp 5000;
BA_REL_ "GenSigTimeoutTime" BU_SG_REL_ TSG_FS SG_ 1646 KL_Innen_Temp 5000;
BA_REL_ "GenSigTimeoutTime" BU_SG_REL_ VTS SG_ 1646 KL_Innen_Temp 5000;
BA_REL_ "GenSigTimeoutTime" BU_SG_REL_ BCM1 SG_ 1646 KL_SIH_LEH_Verteilung_VL 5000;
BA_REL_ "GenSigTimeoutTime" BU_SG_REL_ BCM1 SG_ 1646 KL_SIH_LEL_Verteilung_VL 5000;
BA_REL_ "GenSigTimeoutTime" BU_SG_REL_ BCM1 SG_ 1646 KL_SIH_LEH_Verteilung_VR 5000;
BA_REL_ "GenSigTimeoutTime" BU_SG_REL_ BCM1 SG_ 1646 KL_SIH_LEL_Verteilung_VR 5000;
BA_REL_ "GenSigTimeoutTime" BU_SG_REL_ BCM1 SG_ 949 KL_Kompressorkupplung_linear 1000;
BA_REL_ "GenSigTimeoutTime" BU_SG_REL_ BCM1 SG_ 949 KL_el_Zuheizer_Stufe 1000;
BA_REL_ "GenSigTimeoutTime" BU_SG_REL_ BCM1 SG_ 949 KL_Ausstattung_Klima 1000;
BA_REL_ "GenSigTimeoutTime" BU_SG_REL_ BCM2 SG_ 1640 HSH_Taster 2000;
BA_REL_ "GenSigTimeoutTime" BU_SG_REL_ VSG SG_ 1640 HSH_Taster 2000;
BA_REL_ "GenSigTimeoutTime" BU_SG_REL_ BCM2 SG_ 1640 FSH_Taster 2000;
BA_REL_ "GenSigTimeoutTime" BU_SG_REL_ BCM1 SG_ 1640 KL_SIH_Soll_li 2000;
BA_REL_ "GenSigTimeoutTime" BU_SG_REL_ BCM1 SG_ 1640 KL_SIH_Soll_re 2000;
BA_REL_ "GenSigTimeoutTime" BU_SG_REL_ BCM1 SG_ 1640 KRH_Soll_li 2000;
BA_REL_ "GenSigTimeoutTime" BU_SG_REL_ BCM1 SG_ 1640 KL_SIL_Soll_li 2000;
BA_REL_ "GenSigTimeoutTime" BU_SG_REL_ BCM1 SG_ 1640 KL_SIL_Soll_re 2000;
BA_REL_ "GenSigTimeoutTime" BU_SG_REL_ BCM1 SG_ 1640 KRH_Soll_re 2000;
BA_REL_ "GenSigTimeoutTime" BU_SG_REL_ BCM1 SG_ 1640 KL_Kompressorstrom_soll 2000;
BA_REL_ "GenSigTimeoutTime" BU_SG_REL_ HDSG SG_ 1640 KL_Umluftklappe_Status 2000;
BA_REL_ "GenSigTimeoutTime" BU_SG_REL_ BCM1 SG_ 1441 KL_Temp_Soll_hl 5000;
BA_REL_ "GenSigTimeoutTime" BU_SG_REL_ BCM1 SG_ 1441 KL_Temp_Soll_hr 5000;
BA_REL_ "GenSigTimeoutTime" BU_SG_REL_ BCM1 SG_ 1441 KL_Temp_Soll_vl 5000;
BA_REL_ "GenSigTimeoutTime" BU_SG_REL_ BCM1 SG_ 1441 KL_Temp_Soll_vr 5000;
BA_REL_ "GenSigTimeoutTime" BU_SG_REL_ BCM1 SG_ 1441 KL_SIH_Stufe_hl 5000;
BA_REL_ "GenSigTimeoutTime" BU_SG_REL_ BCM1 SG_ 1441 KL_SIH_Stufe_hr 5000;
BA_REL_ "GenSigTimeoutTime" BU_SG_REL_ BCM1 SG_ 1441 KL_SIL_Stufe_hl 5000;
BA_REL_ "GenSigTimeoutTime" BU_SG_REL_ BCM1 SG_ 1441 KL_SIL_Stufe_hr 5000;
BA_REL_ "GenSigTimeoutTime" BU_SG_REL_ BCM1 SG_ 1441 KL_SIL_LEL_Verteilung_HR 5000;
BA_REL_ "GenSigTimeoutTime" BU_SG_REL_ BCM1 SG_ 1441 KL_SIL_LEL_Verteilung_HL 5000;
BA_REL_ "GenSigTimeoutTime" BU_SG_REL_ BCM1 SG_ 1441 KL_SIH_LEH_Verteilung_HR 5000;
BA_REL_ "GenSigTimeoutTime" BU_SG_REL_ BCM1 SG_ 1441 KL_SIH_LEH_Verteilung_HL 5000;
BA_REL_ "GenSigTimeoutTime" BU_SG_REL_ BCM1 SG_ 992 KL_SL_Soll_hl 1000;
BA_REL_ "GenSigTimeoutTime" BU_SG_REL_ BCM1 SG_ 992 KL_SL_Soll_hr 1000;
BA_REL_ "GenSigTimeoutTime" BU_SG_REL_ BCM1 SG_ 992 KL_SH_Soll_hl 1000;
BA_REL_ "GenSigTimeoutTime" BU_SG_REL_ BCM1 SG_ 992 KL_SH_Soll_hr 1000;
BA_REL_ "GenSigTimeoutTime" BU_SG_REL_ VTS SG_ 1712 FS_Taupunkt 5000;
BA_REL_ "GenSigTimeoutTime" BU_SG_REL_ VTS SG_ 1712 FS_Temp_Scheibe 5000;
BA_REL_ "GenSigTimeoutTime" BU_SG_REL_ VTS SG_ 1712 FS_Temp_Sensor 5000;
BA_REL_ "GenSigTimeoutTime" BU_SG_REL_ VTS SG_ 1712 FS_Luftfeuchte_rel 5000;
BA_REL_ "GenSigTimeoutTime" BU_SG_REL_ BCM2 SG_ 1505 BCM1_Aussen_Temp_ungef 2000;
BA_REL_ "GenSigTimeoutTime" BU_SG_REL_ Gateway SG_ 1505 BCM1_Aussen_Temp_ungef 2000;
BA_REL_ "GenSigTimeoutTime" BU_SG_REL_ HDSG SG_ 1505 BCM1_Aussen_Temp_ungef 2000;
BA_REL_ "GenSigTimeoutTime" BU_SG_REL_ TSG_BFS SG_ 1505 BCM1_Aussen_Temp_ungef 2000;
BA_REL_ "GenSigTimeoutTime" BU_SG_REL_ TSG_FS SG_ 1505 BCM1_Aussen_Temp_ungef 2000;
BA_REL_ "GenSigTimeoutTime" BU_SG_REL_ BCM2 SG_ 1505 BCM_Heizungsabsperrventil_Status 2000;
BA_REL_ "GenSigTimeoutTime" BU_SG_REL_ BCM2 SG_ 1505 BCM_Heizungspumpe_Status 2000;
BA_REL_ "GenSigTimeoutTime" BU_SG_REL_ BCM2 SG_ 1505 BCM_Kompressorkupplung_Status 2000;
BA_REL_ "GenSigTimeoutTime" BU_SG_REL_ Gateway SG_ 1505 BCM1_PTC_stufig_Status 2000;
BA_REL_ "GenSigTimeoutTime" BU_SG_REL_ Gateway SG_ 2549088327 AAG_Nachlauftyp 5000;
BA_REL_ "GenSigTimeoutTime" BU_SG_REL_ Gateway SG_ 2549088327 AAG_SNI 5000;
BA_REL_ "GenSigTimeoutTime" BU_SG_REL_ Gateway SG_ 2549088327 NM_AAG_Lokalaktiv 5000;
BA_REL_ "GenSigTimeoutTime" BU_SG_REL_ Gateway SG_ 2549088327 NM_AAG_Subsystemaktiv 5000;
BA_REL_ "GenSigTimeoutTime" BU_SG_REL_ Gateway SG_ 2549088327 AAG_KD_Fehler 2500;
BA_REL_ "GenSigTimeoutTime" BU_SG_REL_ Gateway SG_ 2549088270 BCM1_Nachlauftyp 5000;
BA_REL_ "GenSigTimeoutTime" BU_SG_REL_ Gateway SG_ 2549088270 BCM1_SNI 5000;
BA_REL_ "GenSigTimeoutTime" BU_SG_REL_ Gateway SG_ 2549088270 NM_BCM1_Lokalaktiv 5000;
BA_REL_ "GenSigTimeoutTime" BU_SG_REL_ Gateway SG_ 2549088270 NM_BCM1_Subsystemaktiv 5000;
BA_REL_ "GenSigTimeoutTime" BU_SG_REL_ Gateway SG_ 2549088270 BCM1_KD_Fehler 2500;
BA_REL_ "GenSigTimeoutTime" BU_SG_REL_ Gateway SG_ 2549088395 BCM2_Nachlauftyp 5000;
BA_REL_ "GenSigTimeoutTime" BU_SG_REL_ Gateway SG_ 2549088395 BCM2_SNI 5000;
BA_REL_ "GenSigTimeoutTime" BU_SG_REL_ Gateway SG_ 2549088395 NM_BCM2_Lokalaktiv 5000;
BA_REL_ "GenSigTimeoutTime" BU_SG_REL_ Gateway SG_ 2549088395 NM_BCM2_Subsystemaktiv 5000;
BA_REL_ "GenSigTimeoutTime" BU_SG_REL_ Gateway SG_ 2549088395 BCM2_KD_Fehler 2500;
BA_REL_ "GenSigTimeoutTime" BU_SG_REL_ Gateway SG_ 2549088305 ELV_Nachlauftyp 5000;
BA_REL_ "GenSigTimeoutTime" BU_SG_REL_ Gateway SG_ 2549088305 ELV_SNI 5000;
BA_REL_ "GenSigTimeoutTime" BU_SG_REL_ Gateway SG_ 2549088305 NM_ELV_Lokalaktiv 5000;
BA_REL_ "GenSigTimeoutTime" BU_SG_REL_ Gateway SG_ 2549088305 NM_ELV_Subsystemaktiv 5000;
BA_REL_ "GenSigTimeoutTime" BU_SG_REL_ Gateway SG_ 2549088305 ELV_KD_Fehler 2500;
BA_REL_ "GenSigTimeoutTime" BU_SG_REL_ Gateway SG_ 2549088291 HDSG_Nachlauftyp 5000;
BA_REL_ "GenSigTimeoutTime" BU_SG_REL_ Gateway SG_ 2549088291 HDSG_SNI 5000;
BA_REL_ "GenSigTimeoutTime" BU_SG_REL_ Gateway SG_ 2549088291 KN_HDSG_WakePrevention 5000;
BA_REL_ "GenSigTimeoutTime" BU_SG_REL_ Gateway SG_ 2549088291 NM_HDSG_Lokalaktiv 5000;
BA_REL_ "GenSigTimeoutTime" BU_SG_REL_ Gateway SG_ 2549088291 HD_KD_Fehler 2500;
BA_REL_ "GenSigTimeoutTime" BU_SG_REL_ Gateway SG_ 2549088306 Kessy_Nachlauftyp 5000;
BA_REL_ "GenSigTimeoutTime" BU_SG_REL_ Gateway SG_ 2549088306 Kessy_SNI 5000;
BA_REL_ "GenSigTimeoutTime" BU_SG_REL_ Gateway SG_ 2549088306 KN_Kessy_ECUKnockOut 5000;
BA_REL_ "GenSigTimeoutTime" BU_SG_REL_ Gateway SG_ 2549088306 KN_Kessy_WakePrevention 5000;
BA_REL_ "GenSigTimeoutTime" BU_SG_REL_ Gateway SG_ 2549088306 NM_Kessy_Lokalaktiv 5000;
BA_REL_ "GenSigTimeoutTime" BU_SG_REL_ Gateway SG_ 2549088306 Kessy_KD_Fehler 2500;
VAL_ 1381 HVLM_HV_Abstellzeit 254 "Init" 255 "Fehler" ;
VAL_ 1381 HVLM_Ladesystemhinweise 0 "kein_Hinweis" 1 "Ladesystem_defekt" 2 "Ladesaeule_inkompatibel" 3 "DC_Laden_nicht_moeglich" ;
VAL_ 1381 HVLM_Zustand_LED 0 "Farbe_1__aus" 1 "Farbe_2__weiss" 2 "Farbe_3__gelb" 3 "Farbe_4__gruen" 4 "Farbe_5__rot" 5 "Farbe_3_pulsierend" 6 "Farbe_4_pulsierend" 7 "Farbe_5_pulsierend" 8 "Farbe_4_5_pulsierend" 9 "Farbe_4__gruen_blinkend" 14 "Init" 15 "Fehler" ;
VAL_ 1381 HVLM_MaxLadezeitDCHV 254 "Init" 255 "Fehler" ;
VAL_ 1381 HVLM_MaxStrom_Netz 126 "Init" 127 "Fehler" ;
VAL_ 1381 HVLM_LG_Sollmodus 0 "Standby" 1 "Netzladung" ;
VAL_ 1381 HVLM_FreigabeTankdeckel 0 "keine_Freigabe" 1 "Freigabe" 2 "Init" 3 "Fehler" ;
VAL_ 1381 HVLM_Stecker_Verriegeln 0 "Stecker_entriegeln" 1 "Stecker_verriegeln" 2 "Init" 3 "keine_Anforderung" ;
VAL_ 1381 HVLM_Start_Spannungsmessung_DCLS 0 "inaktiv" 1 "DCLS_mit_Diode_Start_Messung" 2 "DCLS_ohne_Diode_Start_Messung" 3 "reserve" ;
VAL_ 1381 HVLM_Taster_Profil_Laden_Anf 0 "nicht_aktiv" 1 "aktiv" 2 "Init" 3 "Fehler" ;
VAL_ 1381 HVLM_Taster_Sofort_Laden_Anf 0 "nicht_aktiv" 1 "aktiv" 2 "Init" 3 "Fehler" ;
VAL_ 1381 HVLM_FreigabeKlimatisierung 0 "keine_Freigabe" 1 "Freigabe" 2 "Init" 3 "Fehler" ;
VAL_ 1381 HVLM_Ladetexte 0 "Keine_Anzeige" 1 "AC_Laden_nicht_moeglich" 2 "DC_Laden_nicht_moeglich" 3 "AC_und_DC_Laden_nicht_moeglich" ;
VAL_ 1381 HVLM_IstSpannung_HV 1022 "Init" 1023 "Fehler" ;
VAL_ 1340 HVLM_STH_Betriebsmodus 0 "Keine_Klimatisierung" 1 "Heizen" 2 "Abtauen" 6 "Init" 7 "Fehler" ;
VAL_ 1340 HVLM_Standklima_Timer_Status 0 "Standklimatimer_nicht_aktiv" 1 "Standklimatimer_aktiv" ;
VAL_ 1340 HVLM_HVEM_MaxLeistung 510 "Init" 511 "Fehler" ;
VAL_ 1340 HVLM_Status_Netz 0 "Fzg_nicht_am_Netz" 1 "Fzg_ist_am_Stromnetz" ;
VAL_ 1340 HVLM_Ladeart 0 "keine_Auswahl" 1 "AC_Laden" 2 "DC_Laden" 3 "Konditionierung" ;
VAL_ 1340 HVLM_VK_STH_Einsatz 0 "Verbrennerstandheizung verbieten" 1 "Automatik (Verbrennerstandheizung erlauben)" 2 "Verbrennerstandheizung erzwingen" 3 "reserviert" 4 "reserviert" 5 "reserviert" 6 "Init" 7 "Fehler" ;
VAL_ 1340 HVLM_VK_Modus 0 "keine Vorkonditionierung" 1 "Sofort-Konditionierung" 2 "zeitversetzte Konditionierung" 3 "Fehler" ;
VAL_ 1340 HVLM_IstModus_02 0 "inaktiv" 1 "aktiv" 2 "Init" 3 "Fehler" ;
VAL_ 1340 HVLM_HV_Anf 0 "keine_Anforderung" 1 "Laden_angefordert" 2 "Batteriekonditionierung_angefordert" 3 "Standklimatisierung_angefordert" ;
VAL_ 1340 HVLM_Fehlerstatus 0 "Komponente_IO" 1 "Eingeschr_KompFkt_DC_Lad_NIO" 2 "Eingeschr_KompFkt_AC_Lad_NIO" 3 "Eingeschr_KompFkt_Interlock" 4 "Eingeschr_KompFkt_reserve" 5 "Eingeschr_KompFkt_reserve" 6 "Keine_Komponentenfunktion" 7 "Init" ;
VAL_ 1340 HVLM_Anforderung_HMS 0 "keine_Anforderung" 1 "halten" 2 "parken" 3 "halten_Standby" 4 "anfahren" 5 "Loesen_ueber_Rampe" ;
VAL_ 1340 HVLM_Parken_beibehalten_HMS 0 "Parken_nicht_beibehalten" 1 "Parken_beibehalten" 2 "Init" 3 "Fehler" ;
VAL_ 1340 HVLM_Dauer_Klima 31 "Fehler" ;
VAL_ 1340 HVLM_Stecker_Status 0 "Init" 1 "kein_Stecker_gesteckt" 2 "Stecker_erkannt_nicht_verriegelt" 3 "Stecker_erkannt_und_verriegelt" ;
VAL_ 1340 HVLM_LadeAnforderung 0 "keine_Anforderung" 1 "AC_Laden" 2 "DC_Laden" 3 "Nachladen_12V" 4 "Reserve" 5 "Reserve" 6 "Init" 7 "Fehler" ;
VAL_ 1340 HVLM_MaxBatLadestromHV 254 "Init" 255 "Fehler" ;
VAL_ 371 IEZS_01_CRC 0 "Init" ;
VAL_ 371 IEZS_Anf_KL15 0 "Init" ;
VAL_ 371 IEZS_Anf_KL50 0 "Init" ;
VAL_ 371 IEZS_AnfLeitung_KL15_Fehler 0 "Init" ;
VAL_ 371 IEZS_AnfLeitung_KL50_Fehler 0 "Init" ;
VAL_ 371 IEZS_F_Zuendanlassschalter_1 0 "Init" ;
VAL_ 371 IEZS_F_Zuendanlassschalter_2 0 "Init" ;
VAL_ 371 IEZS_Init_KlemmenAnf 0 "Init" ;
VAL_ 371 IEZS_Noteinspeisung_erkannt 0 "Init" ;
VAL_ 371 IEZS_T_Deckel_Vorne 0 "Init" ;
VAL_ 371 IEZS_T_Deckel_Vorne_Fehler 0 "Init" ;
VAL_ 371 IEZS_TrunkEntrapment_Fehler 0 "Init" ;
VAL_ 29 IMMO_Auth_Master_Slave07_Sig1 0 "Initwert" ;
VAL_ 31 IMMO_Auth_Master_Slave08_Sig 0 "Initwert" ;
VAL_ 28 IMMO_Auth_Slave07_Master_Sig1 0 "Init" ;
VAL_ 30 IMMO_Auth_Slave08_Master_Sig 0 "Init" ;
VAL_ 268 ImoCord_Auth_Aufforderung_WFS 0 "nicht_anfordern" 1 "anfordern" ;
VAL_ 1524 IL_Bel_FS_Ausstieg 0 "inaktiv" 1 "aktiv" ;
VAL_ 1524 IL_Bel_BFS_Ausstieg 0 "inaktiv" 1 "aktiv" ;
VAL_ 1524 IL_Bel_HFS_Ausstieg 0 "inaktiv" 1 "aktiv" ;
VAL_ 1524 IL_Bel_HBFS_Ausstieg 0 "inaktiv" 1 "aktiv" ;
VAL_ 1524 BCM1_Innenlicht_gedimmt_V 0 "100% Innenlicht" 1 "gedimmtes Innenlicht" ;
VAL_ 1524 BCM1_Innenlicht_gedimmt_H 0 "100% Innenlicht" 1 "gedimmtes Innenlicht" ;
VAL_ 1524 IL_Innenlicht_aktiv 0 "Innenlicht inaktiv" 1 "Innenlicht aktiv" ;
VAL_ 1524 IL_Klemme_30G_aktiv 0 "Kl 30G abgeschaltet" 1 "eingeschaltet" ;
VAL_ 1524 BCM1_DI_Rampe_Innenlicht 0 "Dimmrampe 0" 1 "Dimmrampe 1" ;
VAL_ 1524 BCM1_DI_Rampe_Leselicht 0 "Dimmrampe 0" 1 "Dimmrampe 1" ;
VAL_ 1524 BCM1_Innenlicht_H 0 "Aus" 1 "Ein" ;
VAL_ 1524 BCM1_Innenlicht_V 0 "Aus" 1 "Ein" ;
VAL_ 1524 BCM1_Leselicht_Anf_hl 0 "Aus" 1 "Ein" ;
VAL_ 1524 BCM1_Leselicht_Anf_hr 0 "Aus" 1 "Ein" ;
VAL_ 1524 BCM1_Leselicht_Anf_vl 0 "Aus" 1 "Ein" ;
VAL_ 1524 BCM1_Leselicht_Anf_vr 0 "Aus" 1 "Ein" ;
VAL_ 1524 BCM1_Leuchten_Aus 0 "keine Aenderung" 1 "Aus" ;
VAL_ 1524 AMB_Charisma_FahrPr 0 "keine_Funktion" 1 "Programm_1" 2 "Programm_2" 3 "Programm_3" 4 "Programm_4" 5 "Programm_5" 6 "Programm_6" 7 "Programm_7" 8 "Programm_8" 9 "Programm_9" 10 "Programm_10" 11 "Programm_11" 12 "Programm_12" 13 "Programm_13" 14 "Programm_14" 15 "Programm_15" ;
VAL_ 1524 AMB_Charisma_Status 0 "Init" 1 "verfuegbar" 2 "nicht_verfuegbar" 3 "asynchron_durch_Fahrerwunsch" ;
VAL_ 312 IPA_Anforderung_HMS 0 "keine_Anforderung" 1 "halten" 2 "parken" 3 "halten_Standby" 4 "anfahren" 5 "Loesen_ueber_Rampe" 6 "Parken_mit_P" ;
VAL_ 312 IPA_Fahrtaster_LED 0 "Init_Inaktiv" 1 "LED_pulsieren" ;
VAL_ 312 IPA_Fahrstufenwunsch 0 "Init" 2 "Position_R" 4 "Position_D" ;
VAL_ 312 IPA_Status_IPA_GE 0 "IPA_GE_inaktiv" 1 "IPA_GE_Initialisierung" 2 "IPA_GE_Fehler" 4 "IPA_GE_aktivierbar" 5 "IPA_GE_Aktivierung" 6 "IPA_GE_aktiv" 8 "IPA_GE_funktionsbereit" 9 "IPA_GE_Neustart" 10 "IPA_GE_Abbruch" ;
VAL_ 312 IPA_Status_IPA_TSK 1 "IPA_TSK_Init" 2 "IPA_TSK_Fehler" 4 "IPA_TSK_aktivierbar" 5 "IPA_TSK_pausiert" 6 "IPA_TSK_aktiv" 8 "IPA_TSK_funktionsbereit" 10 "IPA_TSK_Abbruch" ;
VAL_ 312 IPA_Sollbeschleunigung 0 "Init" ;
VAL_ 312 IPA_PLA_LED 0 "LED_aus" 1 "LED_ein" 2 "LED_blinken" 3 "Funktion_gesperrt__LED_aus" 6 "Init" ;
VAL_ 312 IPA_APS_LED 0 "LED_aus" 1 "LED_ein" 2 "LED_blinken" 3 "Funktion_gesperrt__LED_aus" 6 "Init" ;
VAL_ 497 FBS_IDG_in_Reichweite 0 "ausser_Reichweite_bzw_nicht_ermittelbar" 1 "innerhalb_Reichweite" ;
VAL_ 497 FFB_Auf_Taste 0 "Taste_nicht_betaetigt" 1 "Oeffnentaste_betaetigt" ;
VAL_ 497 FFB_HDF_Taste 0 "Taste_nicht_betaetigt" 1 "HDF_Taste_am_Funkschluessel_betaetigt" ;
VAL_ 497 FFB_Panik_Taste 0 "Taste_nicht_betaetigt" 1 "Panik_Taste_am_Funkschluessel_betaetigt" ;
VAL_ 497 FFB_Zu_Taste 0 "Taste_nicht_betaetigt" 1 "Zu_Taste_am_Funkschluessel_betaetigt" ;
VAL_ 497 KY_FT_Entriegelung_Autorisiert 0 "kein_Keylessschluessel_erkannt" 1 "Keyless_Schluessel_erkannt_und_authorisiert" ;
VAL_ 497 KY_FT_Verriegelung_Autorisiert 0 "kein_Verriegelungssensor_erkannt" 1 "Verriegelungssensor_erkannt_und_authorisiert" ;
VAL_ 497 KY_BT_Entriegelung_Autorisiert 0 "kein_Keylessschluessel_erkannt" 1 "Keyless_Schluessel_erkannt_und_authorisiert" ;
VAL_ 497 KY_BT_Verriegelung_Autorisiert 0 "kein_Verriegelungssensor_erkannt" 1 "Verriegelungssensor_erkannt_und_authorisiert" ;
VAL_ 497 KY_HFS_Entriegelung_Autorisiert 0 "kein_Keylessschluessel_erkannt" 1 "Keyless_Schluessel_erkannt_und_authorisiert" ;
VAL_ 497 KY_HFS_Verriegelung_Autorisiert 0 "kein_Verriegelungssensor_erkannt" 1 "Verriegelungssensor_erkannt_und_authorisiert" ;
VAL_ 497 KY_HBFS_Entriegelung_Autorisiert 0 "kein_Keylessschluessel_erkannt" 1 "Keyless_Schluessel_erkannt_und_authorisiert" ;
VAL_ 497 KY_HBFS_Verriegelung_Autorisiert 0 "kein_Verriegelungssensor_erkannt" 1 "Verriegelungssensor_erkannt_und_authorisiert" ;
VAL_ 497 KY_Front_Entr_Autorisiert 0 "kein_Keylessschluessel_erkannt" 1 "Keyless_Schluessel_erkannt_und_authorisiert" ;
VAL_ 497 KY_Front_Verr_Autorisiert 0 "kein_Verriegelungssensor_erkannt" 1 "Verriegelungssensor_erkannt_und_authorisiert" ;
VAL_ 497 KY_HD_Entriegelung_Autorisiert 0 "kein_Keylessschluessel_erkannt" 1 "Keyless_Schluessel_erkannt_und_authorisiert" ;
VAL_ 497 KY_HD_Verriegelung_Autorisiert 0 "nicht_autorisiert" 1 "autorisiert" ;
VAL_ 497 KY_Bereich 0 "Bereich_0" 1 "Bereich_1" 2 "Bereich_2" 3 "Bereich_3" 4 "Bereich_4" 5 "Bereich_5" 6 "Kein_Schluessel_gefunden" 7 "Init" ;
VAL_ 497 KY_Position 0 "Position_0" 1 "Postition_1" 2 "Postition_2" 3 "Postition_3" 4 "Postition_4" 6 "Kein_Schluessel_gefunden" 7 "Init" ;
VAL_ 497 Schluesselnr_Personalisierung 14 "Init" 15 "Fehler" ;
VAL_ 497 FFB_FDF_Taste 0 "Taste_nicht_betaetigt" 1 "FDF_Taste_am_Funkschluessel_betaetigt" ;
VAL_ 497 FFB_Joker_Taste 0 "Taste_nicht_betaetigt" 1 "Joker_Taste_an_FFFB_betaetigt" ;
VAL_ 1424 FBS_Warn_Schluessel_Batt 0 "i.O." 1 "defekt" ;
VAL_ 1424 KY_FFB_Frequenz 1 "433 MHz" 2 "315 MHz" 3 "868 MHz" ;
VAL_ 1424 KY_HF_Aktiv 0 "Funktempfang_nicht_aktiv" 1 "HF_Funkempfang_aktiv" ;
VAL_ 1424 KY_LF_Aktiv 0 "Funktempfang_nicht_aktiv" 1 "LF_Funkempfang_aktiv" ;
VAL_ 1424 KY_StartStopp_Info 0 "Motorlauf_nicht_notwendig_(Stoppfreigabe)" 1 "Motoranlauf_nicht_zwingend_notwendig_(Stoppverbot,keine_Startanforderung)" 2 "Motoranlauf_zwingend_notwendig_(Startanforderung)" 3 "Systemfehler" ;
VAL_ 1424 KY_Keyless_Verbau 0 "nicht_verbaut" 1 "verbaut" ;
VAL_ 1424 KY_Keyless_Go_Verbau 0 "nicht_verbaut" 1 "verbaut" ;
VAL_ 1424 KY_Kombinierte_Notspule 0 "nicht_verbaut" 1 "verbaut" ;
VAL_ 1424 KYL_Warn_kein_Schluessel 1 "kein Schluessel erkannt" ;
VAL_ 1424 KYL_Warn_Kessy_defekt 0 "Kessy_i.O." 1 "Kessy defekt" ;
VAL_ 1424 KYL_Warn_Notzuendschloss 0 "Aus" 1 "Ein" ;
VAL_ 1424 KY_Fzg_Verlassen_erkannt 0 "nicht_erkannt" 1 "erkannt" ;
VAL_ 1424 KY_Fzg_Zugang_erkannt 0 "nicht_erkannt" 1 "erkannt" ;
VAL_ 1424 KST_Wegstrecke_Challenge 0 "Init" ;
VAL_ 960 ZAS_Kl_S 0 "aus" 1 "S_Kontakt_ein" ;
VAL_ 960 ZAS_Kl_15 0 "aus" 1 "ein" ;
VAL_ 960 ZAS_Kl_X 0 "aus" 1 "ein" ;
VAL_ 960 ZAS_Kl_50_Startanforderung 0 "aus" 1 "KL50_ein_Startwunsch_Fahrer" ;
VAL_ 960 BCM_Remotestart_Betrieb 0 "kein_RS_Betrieb" 1 "RS_Betrieb" ;
VAL_ 960 ZAS_Kl_Infotainment 0 "inaktiv" 1 "aktiv" ;
VAL_ 960 BCM_Remotestart_KL15_Anf 0 "inaktiv" 1 "aktiv" ;
VAL_ 960 BCM_Remotestart_MO_Start 0 "nicht_angefordert" 1 "angefordert" ;
VAL_ 960 KST_Warn_P1_ZST_def 0 "nicht_defekt" 1 "defekt" ;
VAL_ 960 KST_Warn_P2_ZST_def 0 "nicht_defekt" 1 "defekt" ;
VAL_ 960 KST_Fahrerhinweis_1 0 "inaktiv" 1 "aktiv" ;
VAL_ 960 KST_Fahrerhinweis_2 0 "inaktiv" 1 "aktiv" ;
VAL_ 960 KST_Fahrerhinweis_3 0 "inaktiv" 1 "aktiv" ;
VAL_ 960 KST_Fahrerhinweis_4 0 "inaktiv" 1 "aktiv" ;
VAL_ 960 KST_Fahrerhinweis_5 0 "inaktiv" 1 "aktiv" ;
VAL_ 960 KST_Fahrerhinweis_6 0 "inaktiv" 1 "aktiv" ;
VAL_ 1420 KST_Txt_P_Gang 0 "Aus" 1 "Ein" ;
VAL_ 1420 KST_Txt_Panikabschaltung 0 "Aus" 1 "Ein" ;
VAL_ 1420 KST_Anf_Klemmenfreigabe_ELV 0 "nicht_angefordert" 1 "angefordert" ;
VAL_ 1420 KST_Txt_Komfortabschaltung 0 "inaktiv" 1 "aktiv" ;
VAL_ 1420 KST_Unterdr_Zuendungsmeldung 0 "keine_Unterdr_der_Zuendungsmeldung" 1 "Unterdr_der_Zuendungsmeldung_aktiv" ;
VAL_ 1420 KST_aut_Abschaltung_Zuendung 0 "Zuendung_wird_bei_Verl_nicht_deaktiviert" 1 "Zuendung_wird_bei_Verl_deaktiviert" ;
VAL_ 1420 KST_Anf_ZV_Verriegelung 0 "inaktiv" 1 "aktiv" ;
VAL_ 1646 KL_STL_aktiv 0 "Standlueftung_nicht_aktiv" 1 "Standlueftung_aktiv" ;
VAL_ 1646 KL_STH_aktiv 0 "Standheizung_nicht_aktiv" 1 "Standheizung_aktiv" ;
VAL_ 1646 KL_Solarluefter_aktiv 0 "Solarluefter_nicht_aktiv" 1 "Solarluefter_aktiv__auto" ;
VAL_ 1646 KL_Umluft_Taste 0 "Taste_nicht_gedrueckt" 1 "Taste_gedrueckt" ;
VAL_ 1646 KL_Geblaese_Fond_Status 0 "Geblaese_aus" 1 "Geblaesestufe_10" 2 "Geblaesestufe_20" 3 "Geblaesestufe_30" 4 "Geblaesestufe_40" 5 "Geblaesestufe_50" 6 "Geblaesestufe_60" 7 "Geblaesestufe_70" 8 "Geblaesestufe_80" 9 "Geblaesestufe_90" 10 "Geblaesestufe_100" 14 "Init" 15 "Fehler" ;
VAL_ 1646 KL_STH_Ansteuerung 0 "Aus" 1 "Ein" 2 "Ein_mit_Motorvorwaermung" 3 "Heizleistung_reduziert" ;
VAL_ 1646 KL_Magnetventil 0 "Aus" 1 "Ein" ;
VAL_ 1646 KL_WaPu 0 "Wasserpumpe_aus" 1 "Wasserpumpe_aktiv" ;
VAL_ 1646 KL_Geblaese_Status 0 "Geblaese_aus" 1 "Geblaesestufe_10" 2 "Geblaesestufe_20" 3 "Geblaesestufe_30" 4 "Geblaesestufe_40" 5 "Geblaesestufe_50" 6 "Geblaesestufe_60" 7 "Geblaesestufe_70" 8 "Geblaesestufe_80" 9 "Geblaesestufe_90" 10 "Geblaesestufe_100" 14 "Init" 15 "Fehler" ;
VAL_ 1646 KL_Restwaerme_aktiv 0 "inaktiv" 1 "aktiv" ;
VAL_ 1646 KL_Kompressorkupplung 0 "oeffnen" 1 "schliessen" ;
VAL_ 1646 KL_BCmE_Livetip_Freigabe 0 "Anzeige_Livetip_nicht_zulaessig" 1 "Anzeige_Livetip_zulaessig" ;
VAL_ 1646 KL_HYB_ASV_hinten_schliessen_Anf 0 "keine_Anforderung" 1 "Ventil_schliessen" ;
VAL_ 1646 KL_HYB_ASV_vorne_schliessen_Anf 0 "keine_Anforderung" 1 "Ventil_schliessen" ;
VAL_ 1646 KL_HYB_Spuelbetrieb_Freigabe 0 "kein_Spuelbetrieb" 1 "Spuelbetrieb_moeglich" ;
VAL_ 1646 KL_Innen_Temp 253 "nicht_verbaut" 254 "nicht_verfuegbar" 255 "Fehler" ;
VAL_ 1646 KL_FSH_Automatikbetrieb 0 "aus" 1 "angefordert_durch_Regelung" ;
VAL_ 1646 KL_SIH_LEH_Verteilung_VL 0 "gleichmaessige_Verteilung" 1 "Sitz_Prio_Hoch" 2 "Sitz_Prio_Mittel" 3 "Sitz_Prio_Niedrig" 4 "Lehne_Prio_Niedrig" 5 "Lehne_Prio_Mittel" 6 "Lehne_Prio_Hoch" ;
VAL_ 1646 KL_SIH_LEL_Verteilung_VL 0 "gleichmaessige_Verteilung" 1 "Sitz_Prio_Hoch" 2 "Sitz_Prio_Mittel" 3 "Sitz_Prio_Niedrig" 4 "Lehne_Prio_Niedrig" 5 "Lehne_Prio_Mittel" 6 "Lehne_Prio_Hoch" ;
VAL_ 1646 KL_SIH_LEH_Verteilung_VR 0 "gleichmaessige_Verteilung" 1 "Sitz_Prio_Hoch" 2 "Sitz_Prio_Mittel" 3 "Sitz_Prio_Niedrig" 4 "Lehne_Prio_Niedrig" 5 "Lehne_Prio_Mittel" 6 "Lehne_Prio_Hoch" ;
VAL_ 1646 KL_SIH_LEL_Verteilung_VR 0 "gleichmaessige_Verteilung" 1 "Sitz_Prio_Hoch" 2 "Sitz_Prio_Mittel" 3 "Sitz_Prio_Niedrig" 4 "Lehne_Prio_Niedrig" 5 "Lehne_Prio_Mittel" 6 "Lehne_Prio_Hoch" ;
VAL_ 949 KL_Drehz_Anh 0 "keine_Anhebung" 1 "Drehzahlanhebung_vom_Motor_angefordert" ;
VAL_ 949 KL_Vorwarn_Komp_ein 0 "Init" 1 "Vorwarnung_Kompressor_ein" ;
VAL_ 949 KL_AC_Schalter 0 "aus" 1 "ein" ;
VAL_ 949 KL_Komp_Moment_alt 1 "veraltet_bzw_Ermittlung_des_Moments_nicht_moeglich__zB_keine_Drehzahl_kein_Kaeltemitteldruck" ;
VAL_ 949 KL_Vorwarn_Zuheizer_ein 0 "keine_Vorwarnung" 1 "Vorwarnung_Zuheizer_ein" ;
VAL_ 949 KL_Zustand 0 "aus" 1 "ein" ;
VAL_ 949 KL_Kompressorkupplung_linear 253 "volle_Ansteuerung" 254 "Init__nicht_bedient" ;
VAL_ 949 KL_Charisma_FahrPr 0 "keine_Funktion" 1 "Programm_1" 2 "Programm_2" 3 "Programm_3" 4 "Programm_4" 5 "Programm_5" 6 "Programm_6" 7 "Programm_7" 8 "Programm_8" 9 "Programm_9" 10 "Programm_10" 11 "Programm_11" 12 "Programm_12" 13 "Programm_13" 14 "Programm_14" 15 "Programm_15" ;
VAL_ 949 KL_Charisma_Status 0 "Init" 1 "verfuegbar" 2 "nicht_verfuegbar" 3 "asynchron_durch_Fahrerwunsch" ;
VAL_ 949 KL_nachtr_Stopp_Anf 0 "nicht_angefordert" 1 "angefordert" ;
VAL_ 949 KL_T_Charge 0 "Taster_nicht_betaetigt" 1 "Taster_betaetigt" ;
VAL_ 949 KL_Last_Kompr 255 "Fehler" ;
VAL_ 949 KL_Spannungs_Anf 0 "keine_Anforderung" 1 "Anforderung_Stufe_1" 2 "Anforderung_Stufe_2" 3 "Anforderung_Stufe_3" ;
VAL_ 949 KL_Thermomanagement 0 "keine_Freigabe_TMM__max_Heizbedarf" 1 "kleine_Freigabe_TMM" 2 "mittlere_Freigabe_TMM" 3 "volle_Freigabe_TMM__kein_Heizbedarf" ;
VAL_ 949 KL_StartStopp_Info 0 "Motorlauf_nicht_notwendig_(Stoppfreigabe)" 1 "Motoranlauf_nicht_zwingend_notwendig_(Stoppverbot,keine_Startanforderung)" 2 "Motoranlauf_zwingend_notwendig_(Startanforderung)" 3 "Systemfehler" ;
VAL_ 949 KL_Freilauf_Info 0 "Freilauf_freigegeben" 1 "Uebergang_in_Freilauf_unzulaessig" 2 "Freilauf_nicht_freigegeben_Abbruch" 3 "Freilauf_Anforderung" ;
VAL_ 949 KL_Anf_KL 255 "Fehler" ;
VAL_ 949 KL_el_Zuheizer_Stufe 0 "Aus" 1 "Stufe_1" 2 "Stufe_2" 3 "Stufe_3" ;
VAL_ 949 KL_Ausstattung_Klima 0 "Heizung_elektrisch" 1 "Klimamanuell_elektrisch" 2 "Climatic__1_Zone" 3 "Climatronic__1_Zone" 4 "Climatronic__2_Zonen" 5 "Climatronic__3_Zonen" 6 "Climatronic__4_Zonen" 7 "reserviert" ;
VAL_ 1640 KL_LRH_Taster 0 "nicht_betaetigt" 1 "betaetigt" ;
VAL_ 1640 KL_LRH_Stufe 0 "Stufe_niedrig" 1 "Stufe_mittel" 2 "Stufe_hoch" ;
VAL_ 1640 HSH_Taster 0 "nicht_betaetigt" 1 "short_push" 2 "long_push" 3 "tbd" ;
VAL_ 1640 FSH_Taster 0 "nicht_betaetigt" 1 "betaetigt" ;
VAL_ 1640 KL_Zuheizer_Freigabe 0 "keine_Freigabe_Zuheizer" 1 "Zuheizerfreigabe" ;
VAL_ 1640 KL_Beschlagsgefahr 0 "keine_Beschlagsgefahr" 1 "Beschlagsgefahr" ;
VAL_ 1640 KRH_Soll_li 0 "aus" 1 "Stufe_1" 2 "Stufe_2" 3 "Stufe_3" ;
VAL_ 1640 KRH_Soll_re 0 "aus" 1 "Stufe_1" 2 "Stufe_2" 3 "Stufe_3" ;
VAL_ 1640 KL_Geblspng_Soll 0 "0V_Motorspannung" 252 "0V_sofort_Abschalten" 253 "0V_senken_mit_Rampe" 254 "reserviert" 255 "Fehler" ;
VAL_ 1640 KL_Geblspng_Fond_Soll 0 "0V_Motorspannung" 252 "0V_sofort_Abschalten" 253 "0V_senken_mit_Rampe" 254 "reserviert" 255 "Fehler" ;
VAL_ 1640 KL_I_Geblaese 255 "Fehler" ;
VAL_ 1640 KL_Kompressorstrom_soll 1022 "Init" 1023 "Fehler" ;
VAL_ 1640 KL_Umluftklappe_Status 0 "Frischluft" 1 "Teilumluft_10" 2 "Teilumluft_20" 3 "Teilumluft_30" 4 "Teilumluft_40" 5 "Teilumluft_50" 6 "Teilumluft_60" 7 "Teilumluft_70" 8 "Teilumluft_80" 9 "Teilumluft_90" 10 "Umluft" 15 "Fehler" ;
VAL_ 1640 KL_PTC_Verbauinfo 0 "kein_PTC" 1 "600W_geschaltet" 2 "1000W_geschaltet" 3 "1400W_LIN" ;
VAL_ 1441 KL_Temp_Soll_hl 30 "Klima_OFF" 31 "Init" ;
VAL_ 1441 KL_Temp_Soll_hr 30 "Klima_OFF" 31 "Init" ;
VAL_ 1441 KL_Temp_Soll_vl 30 "Klima_OFF" 31 "Init" ;
VAL_ 1441 KL_Temp_Soll_vr 30 "Klima_OFF" 31 "Init" ;
VAL_ 1441 KL_SIH_Stufe_hl 7 "nicht_verbaut" ;
VAL_ 1441 KL_SIH_Stufe_hr 7 "nicht_verbaut" ;
VAL_ 1441 KL_SIL_Stufe_hl 7 "nicht_verbaut" ;
VAL_ 1441 KL_SIL_Stufe_hr 7 "nicht_verbaut" ;
VAL_ 1441 KL_SIL_LEL_Verteilung_HR 0 "gleichmaessige_Verteilung" 1 "Sitz_Prio_Hoch" 2 "Sitz_Prio_Mittel" 3 "Sitz_Prio_Niedrig" 4 "Lehne_Prio_Niedrig" 5 "Lehne_Prio_Mittel" 6 "Lehne_Prio_Hoch" ;
VAL_ 1441 KL_SIL_LEL_Verteilung_HL 0 "gleichmaessige_Verteilung" 1 "Sitz_Prio_Hoch" 2 "Sitz_Prio_Mittel" 3 "Sitz_Prio_Niedrig" 4 "Lehne_Prio_Niedrig" 5 "Lehne_Prio_Mittel" 6 "Lehne_Prio_Hoch" ;
VAL_ 1441 KL_SIH_LEH_Verteilung_HR 0 "gleichmaessige_Verteilung" 1 "Sitz_Prio_Hoch" 2 "Sitz_Prio_Mittel" 3 "Sitz_Prio_Niedrig" 4 "Lehne_Prio_Niedrig" 5 "Lehne_Prio_Mittel" 6 "Lehne_Prio_Hoch" ;
VAL_ 1441 KL_PTC_linear_Anf 0 "Init" 63 "Fehler" ;
VAL_ 1441 KL_SIH_LEH_Verteilung_HL 0 "gleichmaessige_Verteilung" 1 "Sitz_Prio_Hoch" 2 "Sitz_Prio_Mittel" 3 "Sitz_Prio_Niedrig" 4 "Lehne_Prio_Niedrig" 5 "Lehne_Prio_Mittel" 6 "Lehne_Prio_Hoch" ;
VAL_ 1441 KL_Frischluftklappe_Status 126 "Init" 127 "Fehler" ;
VAL_ 992 KL_Fond_Fuss_Temp_hl 1022 "Init" 1023 "Fehler" ;
VAL_ 992 KL_Fond_Fuss_Temp_hr 1022 "Init" 1023 "Fehler" ;
VAL_ 992 KL_MA_Temp_hl 1022 "Init" 1023 "Fehler" ;
VAL_ 992 KL_SIH_Takt_hl 0 "Aus" 1 "Ein" ;
VAL_ 992 KL_SIH_Takt_hr 0 "Aus" 1 "Ein" ;
VAL_ 992 KL_Fehler_Umluft 0 "Umluftklappe_iO" 1 "Umluftklappe_niO" ;
VAL_ 992 KL_RAB 0 "keine_Auswirkung_auf_Klimasystem" 1 "Fehler_hat_Auswirkung_auf_die_Klimatisierung" ;
VAL_ 992 KL_Fond_Absperrventil 0 "nicht angesteuert" 1 "wird angesteuert" ;
VAL_ 992 KL_Fond_KD_Fehler 0 "kein_KD_Fehler" 1 "KD_Fehler" ;
VAL_ 992 KL_MA_Temp_hr 1022 "Init" 1023 "Fehler" ;
VAL_ 992 KL_Fehler_Fussraum_Klappen 0 "kein_Fehler" 1 "Fehler_Fuss_li" 2 "Fehler_Fuss_re" 3 "Beide_Klappen_defekt" ;
VAL_ 992 KL_Fehler_Temp_Klappen 0 "kein_Fehler" 1 "Fehler_Temp_li" 2 "Fehler_Temp_re" 3 "Beide_Klappen_defekt" ;
VAL_ 992 KL_Fehler_Temp_MA_Klappen 0 "kein_Fehler" 1 "Fehler_MA_li" 2 "Fehler_MA_re" 3 "Beide_Klappen_defekt" ;
VAL_ 1712 FS_Taupunkt 0 "nicht verfuegbar" 1023 "Fehler" ;
VAL_ 1712 FS_ResponseError 0 "normal" 1 "Fehler" ;
VAL_ 1712 FS_Temp_Scheibe 0 "nicht verfuegbar" 1023 "Fehler" ;
VAL_ 1712 FS_Temp_Sensor 0 "nicht verfuegbar" 255 "Fehler" ;
VAL_ 1712 FS_Luftfeuchte_rel 0 "nicht verfuegbar" 255 "Fehler" ;
VAL_ 1505 BCM1_Aussen_Temp_ungef 253 "nicht_verbaut" 254 "Initwert" 255 "Fehler" ;
VAL_ 1505 BCM_Heizungsabsperrventil_Status 0 "HAV_offen" 1 "HAV_geschlossen" 2 "Init_oder_nicht_verbaut" 3 "Fehler" ;
VAL_ 1505 BCM_Heizungspumpe_Status 0 "Pumpe_aus" 1 "Pumpe_aktiv_und_Stauts_iO" 2 "Init_oder_nicht_verbaut" 3 "Fehler" ;
VAL_ 1505 BCM_Kompressorkupplung_Status 0 "Kupplung_offen" 1 "Kupplung_geschlossen" 2 "Init_oder_nicht_verbaut" 3 "Fehler" ;
VAL_ 1505 BCM1_PTC_stufig_Status 0 "Aus" 1 "Stufe_1_aktiv" 2 "Stufe_2_aktiv" 3 "Stufe_3_aktiv" 6 "Init_oder_nicht_verbaut" 7 "Fehler" ;
VAL_ 1505 BCM1_FStatus_Aussentemp_ungef 0 "iO" 1 "niO" ;
VAL_ 1505 BCM1_Kompressorstrom_ist 254 "Init, bzw. nicht verfuegbar" 255 "Fehler" ;
VAL_ 1505 BCM1_OBD_FStatus_ATemp 0 "kein Fehler / Init / nicht verbaut" 1 "KS- (Kurzschluss nach minus)" 2 "KS+ (Kurzschluss nach plus)" 3 "OC (Leitungsunterbrechung)" 4 "OOR+ (Signal zu gross)" 5 "OOR- (Signal zu klein)" 6 "RC+ (Signal unplausibel zu gross)" 7 "RC- (Signal unplausibel zu klein)" 8 "KS+/OC (Kurzschluss nach plus/Unterbrechung)" 9 "KS-/OC  (Kurzschluss nach minus/Unterbrechung)" 10 "KS-/KS+  (Kurzschluss nach minus/plus)" 11 "KS-/KS+/OC (Kurzschluss nach minus/plus/Unterbrechung)" 12 "frei" 13 "frei" 14 "frei" 15 "frei" ;
VAL_ 2549088327 AAG_KompSchutz 0 "inaktiv" 1 "aktiv" ;
VAL_ 2549088327 AAG_Abschaltstufe 0 "keine_Einschraenkung" 1 "Funktionseinschraenkung" ;
VAL_ 2549088327 AAG_Transport_Mode 0 "keine_Einschraenkung" 1 "Funktionseinschraenkung" ;
VAL_ 2549088327 AAG_Nachlauftyp 0 "Komm_bei_KL15_EIN" 1 "Komm_nach_KL15_AUS" 2 "Komm_bei_KL15_AUS" ;
VAL_ 2549088327 AAG_SNI 71 "" ;
VAL_ 2549088327 NM_AAG_Wakeup 0 "Peripherie_Wakeup__Ursache_nicht_bekannt" 1 "Bus_Wakeup" 2 "KL15_HW" 3 "KL54_BLS" 4 "Erkennung_Anhaenger" 5 "AVS_Taster" 6 "AVS_Zustandswechsel" ;
VAL_ 2549088327 NM_AAG_Lokalaktiv 0 "war_nicht_lokal_aktiv" 1 "war_lokal_aktiv" ;
VAL_ 2549088327 NM_AAG_Subsystemaktiv 0 "Subsystem_war_nicht_lokalaktiv" 1 "war_lokalaktiv" ;
VAL_ 2549088327 AAG_KD_Fehler 0 "kein_KD_Fehler" 1 "KD_Fehler" ;
VAL_ 2549088270 BCM1_KompSchutz 0 "inaktiv" 1 "aktiv" ;
VAL_ 2549088270 BCM1_Abschaltstufe 0 "keine_Einschraenkung" 1 "Funktionseinschraenkung" ;
VAL_ 2549088270 BCM1_Transport_Mode 0 "keine_Einschraenkung" 1 "Funktionseinschraenkung" ;
VAL_ 2549088270 BCM1_Nachlauftyp 0 "Komm_bei_KL15_EIN" 1 "Komm_nach_KL15_AUS" 2 "Komm_bei_KL15_AUS" ;
VAL_ 2549088270 BCM1_SNI 14 "" ;
VAL_ 2549088270 NM_BCM1_Wakeup 0 "Peripherie_Wakeup__Ursache_nicht_bekannt" 1 "CAN_Wakeup" 2 "KL15_HW" 3 "KL30" 4 "KL58_xs_xt_xd" 5 "Warnblinktaster_EIN" 6 "LDS_Standlicht" 7 "Klemme_S" 8 "Lock_Unlock_Taster" 9 "Heckdeckel_Grifftaster" 10 "Funkbefehl" 11 "Drehfalle_HL" 12 "Drehfalle_HR" 13 "Motorhaubenkontakt" 14 "Heckdeckel_Vorraste" 15 "Heckdeckel_Hauptraste" 16 "LDS_Abblendlicht" 17 "Drehfalle_FT" 18 "Drehfalle_BT" 19 "Kessy_Schluessel_erkannt" 20 "Heckdeckel_Entriegelungstaster" 21 "Schlossrueckmeldung_HL" 22 "Schlossrueckmeldung_HR" 23 "Lichthupe" 25 "DWA_Heckscheibenbruch" 26 "LIN1" 27 "LIN2" 28 "LIN3" 29 "LIN4" 30 "LIN5" 31 "LIN6" 36 "LDS_Nebellicht_Nebelschlusslicht" 37 "Valet_Taster" 38 "Scheinwerferdiebstahlueberwachung" 39 "Versorgung_Innenlicht_KL30g" 40 "Display_Taster" 41 "RearMode_Taster" 42 "SAD_Taster" 43 "Rollo_Taster" 44 "bCall_Taster" 45 "eCall_Taster" 128 "ZV_Wiederverriegelung" 129 "Coming_Home_Ende" 130 "Leaving_Home_Ende" 131 "Softtouch_Freigabe_entziehen" 132 "Fensterheber_Freigabe_entziehen" 133 "Schiebedach_Freigabe_entziehen" 134 "Verdeck_Freigabe_entziehen" 135 "ELV_Freigabe" 136 "KL58xt_Ende" 137 "IRUE_Ausloesung" 138 "NGS_Ausloesung" 139 "Sounder_Alarm" 140 "Regenschliessen" 141 "Remotestart" 142 "Lichtwarnung_Ende" 143 "DWA_Alarm" 144 "Innenlicht" 145 "Tankklappe_wurde_geschlossen" 146 "Parklicht" 254 "Watchdog_Test" 255 "Entwicklungsursache" ;
VAL_ 2549088270 NM_BCM1_Lokalaktiv 0 "war_nicht_lokal_aktiv" 1 "war_lokal_aktiv" ;
VAL_ 2549088270 NM_BCM1_Subsystemaktiv 0 "Subsystem_war_nicht_lokalaktiv" 1 "war_lokalaktiv" ;
VAL_ 2549088270 BCM1_KD_Fehler 0 "kein_KD_Fehler" 1 "KD_Fehler" ;
VAL_ 2549088395 BCM2_KompSchutz 0 "inaktiv" 1 "aktiv" ;
VAL_ 2549088395 BCM2_Abschaltstufe 0 "keine_Einschraenkung" 1 "Funktionseinschraenkung" ;
VAL_ 2549088395 BCM2_Transport_Mode 0 "keine_Einschraenkung" 1 "Funktionseinschraenkung" ;
VAL_ 2549088395 BCM2_Nachlauftyp 0 "Komm_bei_KL15_EIN" 1 "Komm_nach_KL15_AUS" 2 "Komm_bei_KL15_AUS" ;
VAL_ 2549088395 BCM2_SNI 139 "" ;
VAL_ 2549088395 NM_BCM2_Wakeup 0 "Peripherie_Wakeup__Ursache_nicht_bekannt" 1 "CAN_Wakeup" 2 "KL15_HW" 3 "KL30_Reset" 4 "Statusaenderung_Klemme_S" 5 "Funkempfaenger" 6 "Stellung_P_Automat" 7 "Heckklappenkontakt_Vorraste" 8 "Heckklappenkontakt_Hauptraste" 9 "DWA_Alarm" 10 "HD_Softtouch" 11 "Tankklappenschalter" 12 "Kessy_FT_schliessen" 13 "Kessy_BT_schliessen" 14 "Kessy_HFS_schliessen" 15 "Kessy_HBFS_schliessen" 16 "Kessy_FT_oeffnen" 17 "Kessy_BT_oeffnen" 18 "Kessy_HFS_oeffnen" 19 "Kessy_HBFT_oeffnen" 20 "Kessy_Begruessungslicht" 21 "Kessy_Authentifizierung" 22 "Kessy_Personalisierung" 23 "LIN_IRUE_Alarm" 24 "LIN_NGS_Alarm" 25 "LIN_Sounder_Leitungsueberwachung" 26 "LIN_EZS" 27 "LIN_VIP_Sensor" 28 "Kofferraumdeckel_hinten" 29 "Kessy_Funk" 30 "Kessy_Nummer_Zugang" 31 "Kessy_Defekt" 128 "ZV_Nachverriegelung" 129 "FH_Freigabe_Nachlauf_beendet" 130 "Remote_Door_Lock_Unlock" 131 "Infotainmentnachlauf_beendet" 132 "Remote_Motorstart" 133 "Uebernahme_LED_blinken" ;
VAL_ 2549088395 NM_BCM2_Lokalaktiv 0 "war_nicht_lokal_aktiv" 1 "war_lokal_aktiv" ;
VAL_ 2549088395 NM_BCM2_Subsystemaktiv 0 "Subsystem_war_nicht_lokalaktiv" 1 "war_lokalaktiv" ;
VAL_ 2549088395 BCM2_KD_Fehler 0 "kein_KD_Fehler" 1 "KD_Fehler" ;
VAL_ 2549088305 ELV_KompSchutz 0 "inaktiv" 1 "aktiv" ;
VAL_ 2549088305 ELV_Abschaltstufe 0 "keine_Einschraenkung" 1 "Funktionseinschraenkung" ;
VAL_ 2549088305 ELV_Transport_Mode 0 "keine_Einschraenkung" 1 "Funktionseinschraenkung" ;
VAL_ 2549088305 ELV_Nachlauftyp 0 "Komm_bei_KL15_EIN" 1 "Komm_nach_KL15_AUS" 2 "Komm_bei_KL15_AUS" ;
VAL_ 2549088305 ELV_SNI 49 "" ;
VAL_ 2549088305 NM_ELV_Wakeup 0 "Peripherie_Wakeup__Ursache_nicht_bekannt" 1 "Bus_Wakeup" 2 "KL15_HW" 3 "ZAT_betaetigt" 4 "KL30_Reset" ;
VAL_ 2549088305 NM_ELV_Lokalaktiv 0 "war_nicht_lokal_aktiv" 1 "war_lokal_aktiv" ;
VAL_ 2549088305 NM_ELV_Subsystemaktiv 0 "Subsystem_war_nicht_lokalaktiv" 1 "war_lokalaktiv" ;
VAL_ 2549088305 ELV_KD_Fehler 0 "kein_KD_Fehler" 1 "KD_Fehler" ;
VAL_ 2549088272 Gateway_KompSchutz 0 "inaktiv" 1 "aktiv" ;
VAL_ 2549088272 Gateway_Abschaltstufe 0 "keine_Einschraenkung" 1 "Funktionseinschraenkung" ;
VAL_ 2549088272 Gateway_Transport_Mode 0 "keine_Einschraenkung" 1 "Funktionseinschraenkung" ;
VAL_ 2549088272 Gateway_Nachlauftyp 0 "Komm_bei_KL15_EIN" 1 "Komm_nach_KL15_AUS" 2 "Komm_bei_KL15_AUS" ;
VAL_ 2549088272 Gateway_SNI 16 "" ;
VAL_ 2549088272 NM_Gateway_Wakeup 0 "Peripherie_Wakeup__Ursache_nicht_bekannt" 1 "Bus_Wakeup" 2 "KL15_HW" 3 "ACAN_Wakeup" 4 "FCAN_Wakeup" 5 "KCAN_Wakeup" 6 "ICAN_Wakeup" 7 "DiagCAN_Wakeup" 8 "ECAN_Wakeup" 9 "Energie_LIN_Wakeup" 10 "Bedien_LIN_Wakeup" 11 "HybridCAN_Wakeup" 12 "Flexray_Wakeup" 13 "MFL_WakeUp" 128 "Energiemanagement" 129 "Funktionswakeup_OBDC" 130 "Hochvoltenergiemanagement" 131 "CWU_empfangen" 132 "Fuer_Bus_relevanten_FC_empfangen" 133 "OnlineDienst_empfangen" 134 "HV_Aktivieren" 135 "HV_Deaktivieren" ;
VAL_ 2549088272 NM_Gateway_Lokalaktiv 0 "war_nicht_lokal_aktiv" 1 "war_lokal_aktiv" ;
VAL_ 2549088272 NM_Gateway_Subsystemaktiv 0 "Subsystem_war_nicht_lokalaktiv" 1 "war_lokalaktiv" ;
VAL_ 2549088272 GW_KD_Fehler 0 "kein_KD_Fehler" 1 "KD_Fehler" ;
VAL_ 2549088291 HDSG_KompSchutz 0 "inaktiv" 1 "aktiv" ;
VAL_ 2549088291 HDSG_Abschaltstufe 0 "keine_Einschraenkung" 1 "Funktionseinschraenkung" ;
VAL_ 2549088291 HDSG_Transport_Mode 0 "keine_Einschraenkung" 1 "Funktionseinschraenkung" ;
VAL_ 2549088291 HDSG_Nachlauftyp 0 "Komm_bei_KL15_EIN" 1 "Komm_nach_KL15_AUS" 2 "Komm_bei_KL15_AUS" ;
VAL_ 2549088291 HDSG_SNI 35 "" ;
VAL_ 2549088291 NM_HDSG_Wakeup 0 "Peripherie_Wakeup__Ursache_nicht_bekannt" 1 "Bus_Wakeup" 2 "KL15_HW" 3 "KL30_Reset" 4 "Innentaster_bet" 5 "Kessy_Taster_bet" 6 "Hall_Motor1_Bewegung_man" 7 "Hall_Motor2_Bewegung_man" ;
VAL_ 2549088291 KN_HDSG_WakePrevention 0 "Funktion_nicht_ausgeloest" 1 "WakePrevention_aktiv" 2 "Reset_durchgefuehrt" 3 "Funktion_deaktiviert" ;
VAL_ 2549088291 NM_HDSG_Lokalaktiv 0 "war_nicht_lokal_aktiv" 1 "war_lokal_aktiv" ;
VAL_ 2549088291 NM_HDSG_Subsystemaktiv 0 "Subsystem_war_nicht_lokalaktiv" 1 "war_lokalaktiv" ;
VAL_ 2549088291 HD_KD_Fehler 0 "kein_KD_Fehler" 1 "KD_Fehler" ;
VAL_ 2549088306 Kessy_KompSchutz 0 "inaktiv" 1 "aktiv" ;
VAL_ 2549088306 Kessy_Abschaltstufe 0 "keine_Einschraenkung" 1 "Funktionseinschraenkung" ;
VAL_ 2549088306 Kessy_Transport_Mode 0 "keine_Einschraenkung" 1 "Funktionseinschraenkung" ;
VAL_ 2549088306 Kessy_Nachlauftyp 0 "Komm_bei_KL15_EIN" 1 "Komm_nach_KL15_AUS" 2 "Komm_bei_KL15_AUS" ;
VAL_ 2549088306 Kessy_SNI 50 "" ;
VAL_ 2549088306 NM_Kessy_Wakeup 0 "Peripherie_Wakeup__Ursache_nicht_bekannt" 1 "Bus_Wakeup" 2 "KL15_HW" 3 "ZAT_betaetigt" 4 "KL30_Reset" ;
VAL_ 2549088306 KN_Kessy_ECUKnockOut 0 "Funktion_nicht_ausgeloest" 2 "SG_wurde_ausgeschaltet" 3 "Funktion_deaktiviert" ;
VAL_ 2549088306 KN_Kessy_WakePrevention 0 "Funktion_nicht_ausgeloest" 1 "WakePrevention_aktiv" 2 "Reset_durchgefuehrt" 3 "Funktion_deaktiviert" ;
VAL_ 2549088306 NM_Kessy_Lokalaktiv 0 "war_nicht_lokal_aktiv" 1 "war_lokal_aktiv" ;
VAL_ 2549088306 Kessy_KD_Fehler 0 "kein_KD_Fehler" 1 "KD_Fehler" ;
